VERSION ""

NS_ :

BS_:

BU_:

BO_ 2633719294 VFSSM3DET: 24 Vector__XXX
 SG_ VFSSMdl3Dttr1DttrTp : 0|4@1+ (1,0) [0|15] "" Vector__XXX
 SG_ VFSSMdl3Dttr1DttrDtSLOT : 4|4@1+ (1,0) [0|15] "" Vector__XXX
 SG_ VFSSMdl3Dttr2DttrTp : 24|4@1+ (1,0) [0|15] "" Vector__XXX
 SG_ VFSSMdl3Dttr2DttrDtSLOT : 28|4@1+ (1,0) [0|15] "" Vector__XXX
 SG_ VFSSMdl3Dttr3DttrTp : 48|4@1+ (1,0) [0|15] "" Vector__XXX
 SG_ VFSSMdl3Dttr3DttrDtSLOT : 52|4@1+ (1,0) [0|15] "" Vector__XXX
 SG_ VFSSMdl3Dttr4DttrTp : 72|4@1+ (1,0) [0|15] "" Vector__XXX
 SG_ VFSSMdl3Dttr4DttrDtSLOT : 76|4@1+ (1,0) [0|15] "" Vector__XXX
 SG_ VFSSMdl3Dttr5DttrTp : 96|4@1+ (1,0) [0|15] "" Vector__XXX
 SG_ VFSSMdl3Dttr5DttrDtSLOT : 100|4@1+ (1,0) [0|15] "" Vector__XXX
 SG_ VFSSMdl3Dttr6DttrTp : 120|4@1+ (1,0) [0|15] "" Vector__XXX
 SG_ VFSSMdl3Dttr6DttrDtSLOT : 124|4@1+ (1,0) [0|15] "" Vector__XXX
 SG_ VFSSMdl3Dttr7DttrTp : 144|4@1+ (1,0) [0|15] "" Vector__XXX
 SG_ VFSSMdl3Dttr7DttrDtSLOT : 148|4@1+ (1,0) [0|15] "" Vector__XXX
 SG_ VFSSMdl3Dttr8DttrTp : 168|4@1+ (1,0) [0|15] "" Vector__XXX
 SG_ VFSSMdl3Dttr8DttrDtSLOT : 172|4@1+ (1,0) [0|15] "" Vector__XXX

BO_ 2633719550 VFSSM4DET: 24 Vector__XXX
 SG_ VFSSMdl4Dttr1DttrTp : 0|4@1+ (1,0) [0|15] "" Vector__XXX
 SG_ VFSSMdl4Dttr1DttrDtSLOT : 4|4@1+ (1,0) [0|15] "" Vector__XXX
 SG_ VFSSMdl4Dttr2DttrTp : 24|4@1+ (1,0) [0|15] "" Vector__XXX
 SG_ VFSSMdl4Dttr2DttrDtSLOT : 28|4@1+ (1,0) [0|15] "" Vector__XXX
 SG_ VFSSMdl4Dttr3DttrTp : 48|4@1+ (1,0) [0|15] "" Vector__XXX
 SG_ VFSSMdl4Dttr3DttrDtSLOT : 52|4@1+ (1,0) [0|15] "" Vector__XXX
 SG_ VFSSMdl4Dttr4DttrTp : 72|4@1+ (1,0) [0|15] "" Vector__XXX
 SG_ VFSSMdl4Dttr4DttrDtSLOT : 76|4@1+ (1,0) [0|15] "" Vector__XXX
 SG_ VFSSMdl4Dttr5DttrTp : 96|4@1+ (1,0) [0|15] "" Vector__XXX
 SG_ VFSSMdl4Dttr5DttrDtSLOT : 100|4@1+ (1,0) [0|15] "" Vector__XXX
 SG_ VFSSMdl4Dttr6DttrTp : 120|4@1+ (1,0) [0|15] "" Vector__XXX
 SG_ VFSSMdl4Dttr6DttrDtSLOT : 124|4@1+ (1,0) [0|15] "" Vector__XXX
 SG_ VFSSMdl4Dttr7DttrTp : 144|4@1+ (1,0) [0|15] "" Vector__XXX
 SG_ VFSSMdl4Dttr7DttrDtSLOT : 148|4@1+ (1,0) [0|15] "" Vector__XXX
 SG_ VFSSMdl4Dttr8DttrTp : 168|4@1+ (1,0) [0|15] "" Vector__XXX
 SG_ VFSSMdl4Dttr8DttrDtSLOT : 172|4@1+ (1,0) [0|15] "" Vector__XXX

BO_ 2633719806 VFSSM1AUX: 16 Vector__XXX
 SG_ VFSSModule1HeatZone1Data : 0|16@1+ (0.01,0) [0|642.55] "V" Vector__XXX
 SG_ VFSSModule1HeatZone2Data : 16|16@1+ (0.01,0) [0|642.55] "V" Vector__XXX
 SG_ VFSSModule1ReleaseZone1Data : 32|16@1+ (0.01,0) [0|642.55] "V" Vector__XXX
 SG_ VFSSModule1ReleaseZone2Data : 48|16@1+ (0.01,0) [0|642.55] "V" Vector__XXX
 SG_ VFSSModule1PressureSwitch1Data : 64|16@1+ (0.01,0) [0|642.55] "V" Vector__XXX
 SG_ VFSSModule1PressureSwitch2Data : 80|16@1+ (0.01,0) [0|642.55] "V" Vector__XXX
 SG_ VFSSModule1PrimaryPowerVoltage : 96|16@1+ (0.01,0) [0|642.55] "V" Vector__XXX
 SG_ VFSSMdl1SndrPwrVltg : 112|16@1+ (0.01,0) [0|642.55] "V" Vector__XXX

BO_ 2633720062 VFSSM2AUX: 16 Vector__XXX
 SG_ VFSSModule2HeatZone1Data : 0|16@1+ (0.01,0) [0|642.55] "V" Vector__XXX
 SG_ VFSSModule2HeatZone2Data : 16|16@1+ (0.01,0) [0|642.55] "V" Vector__XXX
 SG_ VFSSModule2ReleaseZone1Data : 32|16@1+ (0.01,0) [0|642.55] "V" Vector__XXX
 SG_ VFSSModule2ReleaseZone2Data : 48|16@1+ (0.01,0) [0|642.55] "V" Vector__XXX
 SG_ VFSSModule2PressureSwitch1Data : 64|16@1+ (0.01,0) [0|642.55] "V" Vector__XXX
 SG_ VFSSModule2PressureSwitch2Data : 80|16@1+ (0.01,0) [0|642.55] "V" Vector__XXX
 SG_ VFSSModule2PrimaryPowerVoltage : 96|16@1+ (0.01,0) [0|642.55] "V" Vector__XXX
 SG_ VFSSMdl2SndrPwrVltg : 112|16@1+ (0.01,0) [0|642.55] "V" Vector__XXX

BO_ 2633720318 VFSSM3AUX: 16 Vector__XXX
 SG_ VFSSModule3HeatZone1Data : 0|16@1+ (0.01,0) [0|642.55] "V" Vector__XXX
 SG_ VFSSModule3HeatZone2Data : 16|16@1+ (0.01,0) [0|642.55] "V" Vector__XXX
 SG_ VFSSModule3ReleaseZone1Data : 32|16@1+ (0.01,0) [0|642.55] "V" Vector__XXX
 SG_ VFSSModule3ReleaseZone2Data : 48|16@1+ (0.01,0) [0|642.55] "V" Vector__XXX
 SG_ VFSSModule3PressureSwitch1Data : 64|16@1+ (0.01,0) [0|642.55] "V" Vector__XXX
 SG_ VFSSModule3PressureSwitch2Data : 80|16@1+ (0.01,0) [0|642.55] "V" Vector__XXX
 SG_ VFSSModule3PrimaryPowerVoltage : 96|16@1+ (0.01,0) [0|642.55] "V" Vector__XXX
 SG_ VFSSMdl3SndrPwrVltg : 112|16@1+ (0.01,0) [0|642.55] "V" Vector__XXX

BO_ 2633720574 VFSSM4AUX: 16 Vector__XXX
 SG_ VFSSModule4HeatZone1Data : 0|16@1+ (0.01,0) [0|642.55] "V" Vector__XXX
 SG_ VFSSModule4HeatZone2Data : 16|16@1+ (0.01,0) [0|642.55] "V" Vector__XXX
 SG_ VFSSModule4ReleaseZone1Data : 32|16@1+ (0.01,0) [0|642.55] "V" Vector__XXX
 SG_ VFSSModule4ReleaseZone2Data : 48|16@1+ (0.01,0) [0|642.55] "V" Vector__XXX
 SG_ VFSSModule4PressureSwitch1Data : 64|16@1+ (0.01,0) [0|642.55] "V" Vector__XXX
 SG_ VFSSModule4PressureSwitch2Data : 80|16@1+ (0.01,0) [0|642.55] "V" Vector__XXX
 SG_ VFSSModule4PrimaryPowerVoltage : 96|16@1+ (0.01,0) [0|642.55] "V" Vector__XXX
 SG_ VFSSMdl4SndrPwrVltg : 112|16@1+ (0.01,0) [0|642.55] "V" Vector__XXX

BO_ 2633720830 VFSSM1NAMES: 104 Vector__XXX
 SG_ VFSSModule1Name : 0|64@1+ (1,0) [0|255] "ASCII" Vector__XXX
 SG_ VFSSModule1DetectorZone1Name : 64|64@1+ (1,0) [0|255] "ASCII" Vector__XXX
 SG_ VFSSModule1DetectorZone2Name : 128|64@1+ (1,0) [0|255] "ASCII" Vector__XXX
 SG_ VFSSModule1DetectorZone3Name : 192|64@1+ (1,0) [0|255] "ASCII" Vector__XXX
 SG_ VFSSModule1DetectorZone4Name : 256|64@1+ (1,0) [0|255] "ASCII" Vector__XXX
 SG_ VFSSModule1DetectorZone5Name : 320|64@1+ (1,0) [0|255] "ASCII" Vector__XXX
 SG_ VFSSModule1DetectorZone6Name : 384|64@1+ (1,0) [0|255] "ASCII" Vector__XXX
 SG_ VFSSModule1DetectorZone7Name : 448|64@1+ (1,0) [0|255] "ASCII" Vector__XXX
 SG_ VFSSModule1DetectorZone8Name : 512|64@1+ (1,0) [0|255] "ASCII" Vector__XXX
 SG_ VFSSModule1HeatZone1Name : 576|64@1+ (1,0) [0|255] "ASCII" Vector__XXX
 SG_ VFSSModule1HeatZone2Name : 640|64@1+ (1,0) [0|255] "ASCII" Vector__XXX
 SG_ VFSSModule1ReleaseZone1Name : 704|64@1+ (1,0) [0|255] "ASCII" Vector__XXX
 SG_ VFSSModule1ReleaseZone2Name : 768|64@1+ (1,0) [0|255] "ASCII" Vector__XXX

BO_ 2633721086 VFSSM2NAMES: 104 Vector__XXX
 SG_ VFSSModule2Name : 0|64@1+ (1,0) [0|255] "ASCII" Vector__XXX
 SG_ VFSSModule2DetectorZone1Name : 64|64@1+ (1,0) [0|255] "ASCII" Vector__XXX
 SG_ VFSSModule2DetectorZone2Name : 128|64@1+ (1,0) [0|255] "ASCII" Vector__XXX
 SG_ VFSSModule2DetectorZone3Name : 192|64@1+ (1,0) [0|255] "ASCII" Vector__XXX
 SG_ VFSSModule2DetectorZone4Name : 256|64@1+ (1,0) [0|255] "ASCII" Vector__XXX
 SG_ VFSSModule2DetectorZone5Name : 320|64@1+ (1,0) [0|255] "ASCII" Vector__XXX
 SG_ VFSSModule2DetectorZone6Name : 384|64@1+ (1,0) [0|255] "ASCII" Vector__XXX
 SG_ VFSSModule2DetectorZone7Name : 448|64@1+ (1,0) [0|255] "ASCII" Vector__XXX
 SG_ VFSSModule2DetectorZone8Name : 512|64@1+ (1,0) [0|255] "ASCII" Vector__XXX
 SG_ VFSSModule2HeatZone1Name : 576|64@1+ (1,0) [0|255] "ASCII" Vector__XXX
 SG_ VFSSModule2HeatZone2Name : 640|64@1+ (1,0) [0|255] "ASCII" Vector__XXX
 SG_ VFSSModule2ReleaseZone1Name : 704|64@1+ (1,0) [0|255] "ASCII" Vector__XXX
 SG_ VFSSModule2ReleaseZone2Name : 768|64@1+ (1,0) [0|255] "ASCII" Vector__XXX

BO_ 2633721342 VFSSM3NAMES: 104 Vector__XXX
 SG_ VFSSModule3Name : 0|64@1+ (1,0) [0|255] "ASCII" Vector__XXX
 SG_ VFSSModule3DetectorZone1Name : 64|64@1+ (1,0) [0|255] "ASCII" Vector__XXX
 SG_ VFSSModule3DetectorZone2Name : 128|64@1+ (1,0) [0|255] "ASCII" Vector__XXX
 SG_ VFSSModule3DetectorZone3Name : 192|64@1+ (1,0) [0|255] "ASCII" Vector__XXX
 SG_ VFSSModule3DetectorZone4Name : 256|64@1+ (1,0) [0|255] "ASCII" Vector__XXX
 SG_ VFSSModule3DetectorZone5Name : 320|64@1+ (1,0) [0|255] "ASCII" Vector__XXX
 SG_ VFSSModule3DetectorZone6Name : 384|64@1+ (1,0) [0|255] "ASCII" Vector__XXX
 SG_ VFSSModule3DetectorZone7Name : 448|64@1+ (1,0) [0|255] "ASCII" Vector__XXX
 SG_ VFSSModule3DetectorZone8Name : 512|64@1+ (1,0) [0|255] "ASCII" Vector__XXX
 SG_ VFSSModule3HeatZone1Name : 576|64@1+ (1,0) [0|255] "ASCII" Vector__XXX
 SG_ VFSSModule3HeatZone2Name : 640|64@1+ (1,0) [0|255] "ASCII" Vector__XXX
 SG_ VFSSModule3ReleaseZone1Name : 704|64@1+ (1,0) [0|255] "ASCII" Vector__XXX
 SG_ VFSSModule3ReleaseZone2Name : 768|64@1+ (1,0) [0|255] "ASCII" Vector__XXX

BO_ 2633721598 VFSSM4NAMES: 104 Vector__XXX
 SG_ VFSSModule4Name : 0|64@1+ (1,0) [0|255] "ASCII" Vector__XXX
 SG_ VFSSModule4DetectorZone1Name : 64|64@1+ (1,0) [0|255] "ASCII" Vector__XXX
 SG_ VFSSModule4DetectorZone2Name : 128|64@1+ (1,0) [0|255] "ASCII" Vector__XXX
 SG_ VFSSModule4DetectorZone3Name : 192|64@1+ (1,0) [0|255] "ASCII" Vector__XXX
 SG_ VFSSModule4DetectorZone4Name : 256|64@1+ (1,0) [0|255] "ASCII" Vector__XXX
 SG_ VFSSModule4DetectorZone5Name : 320|64@1+ (1,0) [0|255] "ASCII" Vector__XXX
 SG_ VFSSModule4DetectorZone6Name : 384|64@1+ (1,0) [0|255] "ASCII" Vector__XXX
 SG_ VFSSModule4DetectorZone7Name : 448|64@1+ (1,0) [0|255] "ASCII" Vector__XXX
 SG_ VFSSModule4DetectorZone8Name : 512|64@1+ (1,0) [0|255] "ASCII" Vector__XXX
 SG_ VFSSModule4HeatZone1Name : 576|64@1+ (1,0) [0|255] "ASCII" Vector__XXX
 SG_ VFSSModule4HeatZone2Name : 640|64@1+ (1,0) [0|255] "ASCII" Vector__XXX
 SG_ VFSSModule4ReleaseZone1Name : 704|64@1+ (1,0) [0|255] "ASCII" Vector__XXX
 SG_ VFSSModule4ReleaseZone2Name : 768|64@1+ (1,0) [0|255] "ASCII" Vector__XXX

BO_ 2566612990 MG2IAPL: 8 Vector__XXX
 SG_ MtGt2IvtPwLtddtUddRs : 0|2@1+ (1,0) [0|3] "" Vector__XXX
 SG_ MtGt2IvtPwLtddtDCSdCtMx : 2|2@1+ (1,0) [0|3] "" Vector__XXX
 SG_ MtGt2IvtPwLtddtDCSdCtM : 4|2@1+ (1,0) [0|3] "" Vector__XXX
 SG_ MtGt2IvtPwLtddtDCSdVtMx : 6|2@1+ (1,0) [0|3] "" Vector__XXX
 SG_ MtGt2IvtPwLtddtDCSdVtM : 8|2@1+ (1,0) [0|3] "" Vector__XXX
 SG_ MtGt2IvtPwLtddtMPwMx : 10|2@1+ (1,0) [0|3] "" Vector__XXX
 SG_ MtGt2IvtPwLtddtMPwM : 12|2@1+ (1,0) [0|3] "" Vector__XXX
 SG_ MtGt2IvtPwLtddtDCSdPwMx : 14|2@1+ (1,0) [0|3] "" Vector__XXX
 SG_ MtGt2IvtPwLtddtDCSdPwM : 16|2@1+ (1,0) [0|3] "" Vector__XXX
 SG_ MtrGnrtr2InvrtrPwrLmtddtTrqMxmm : 18|2@1+ (1,0) [0|3] "" Vector__XXX
 SG_ MtrGnrtr2InvrtrPwrLmtddtTrqMnmm : 20|2@1+ (1,0) [0|3] "" Vector__XXX
 SG_ MtrGnrtr2InvrtrPwrLmtddtSpdMxmm : 22|2@1+ (1,0) [0|3] "" Vector__XXX
 SG_ MtrGnrtr2InvrtrPwrLmtddtSpdMnmm : 24|2@1+ (1,0) [0|3] "" Vector__XXX
 SG_ MtGt2IvtPwLtddtIvtTpt : 28|2@1+ (1,0) [0|3] "" Vector__XXX
 SG_ MtGt2IvtPwLtddtMtTpt : 30|2@1+ (1,0) [0|3] "" Vector__XXX
 SG_ MtGt2IvtPwLtdDtFtCdt : 32|2@1+ (1,0) [0|3] "" Vector__XXX
 SG_ MtGt2IvtPwLtdDtAtvTqRtLt : 34|2@1+ (1,0) [0|3] "" Vector__XXX
 SG_ MtGt2IvtPwLtdDtAtvSpdRtLt : 36|2@1+ (1,0) [0|3] "" Vector__XXX
 SG_ MtGt2IvtTqLtdDtMCtsts : 38|2@1+ (1,0) [0|3] "" Vector__XXX

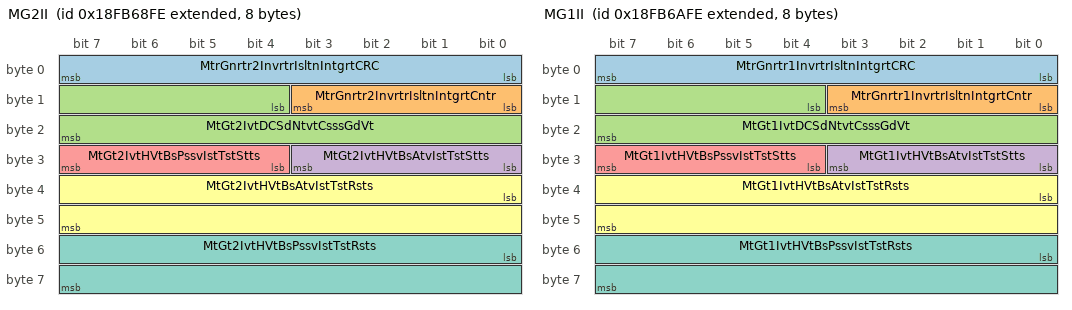
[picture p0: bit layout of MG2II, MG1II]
BO_ 2566613246 MG2II: 8 Vector__XXX
 SG_ MtrGnrtr2InvrtrIsltnIntgrtCRC : 0|8@1+ (1,0) [0|255] "count" Vector__XXX
 SG_ MtrGnrtr2InvrtrIsltnIntgrtCntr : 8|4@1+ (1,0) [0|15] "" Vector__XXX
 SG_ MtGt2IvtDCSdNtvtCsssGdVt : 12|12@1+ (42370,-125) [-125|125.9375] "%" Vector__XXX
 SG_ MtGt2IvtHVtBsAtvIstTstStts : 24|4@1+ (1,0) [0|15] "" Vector__XXX
 SG_ MtGt2IvtHVtBsPssvIstTstStts : 28|4@1+ (1,0) [0|15] "" Vector__XXX
 SG_ MtGt2IvtHVtBsAtvIstTstRsts : 32|16@1+ (0.1,0) [0|6425.5] "ohm/V" Vector__XXX
 SG_ MtGt2IvtHVtBsPssvIstTstRsts : 48|16@1+ (0.1,0) [0|6425.5] "ohm/V" Vector__XXX

BO_ 2566613502 MG1IAPL: 8 Vector__XXX
 SG_ MtGt1IvtPwLtddtUddRs : 0|2@1+ (1,0) [0|3] "" Vector__XXX
 SG_ MtGt1IvtPwLtddtDCSdCtMx : 2|2@1+ (1,0) [0|3] "" Vector__XXX
 SG_ MtGt1IvtPwLtddtDCSdCtM : 4|2@1+ (1,0) [0|3] "" Vector__XXX
 SG_ MtGt1IvtPwLtddtDCSdVtMx : 6|2@1+ (1,0) [0|3] "" Vector__XXX
 SG_ MtGt1IvtPwLtddtDCSdVtM : 8|2@1+ (1,0) [0|3] "" Vector__XXX
 SG_ MtGt1IvtPwLtddtMPwMx : 10|2@1+ (1,0) [0|3] "" Vector__XXX
 SG_ MtGt1IvtPwLtddtMPwM : 12|2@1+ (1,0) [0|3] "" Vector__XXX
 SG_ MtGt1IvtPwLtddtDCSdPwMx : 14|2@1+ (1,0) [0|3] "" Vector__XXX
 SG_ MtGt1IvtPwLtddtDCSdPwM : 16|2@1+ (1,0) [0|3] "" Vector__XXX
 SG_ MtrGnrtr1InvrtrPwrLmtddtTrqMxmm : 18|2@1+ (1,0) [0|3] "" Vector__XXX
 SG_ MtrGnrtr1InvrtrPwrLmtddtTrqMnmm : 20|2@1+ (1,0) [0|3] "" Vector__XXX
 SG_ MtrGnrtr1InvrtrPwrLmtddtSpdMxmm : 22|2@1+ (1,0) [0|3] "" Vector__XXX
 SG_ MtrGnrtr1InvrtrPwrLmtddtSpdMnmm : 24|2@1+ (1,0) [0|3] "" Vector__XXX
 SG_ MtGt1IvtPwLtddtIvtTpt : 28|2@1+ (1,0) [0|3] "" Vector__XXX
 SG_ MtGt1IvtPwLtddtMtTpt : 30|2@1+ (1,0) [0|3] "" Vector__XXX
 SG_ MtGt1IvtPwLtdDtFtCdt : 32|2@1+ (1,0) [0|3] "" Vector__XXX
 SG_ MtGt1IvtPwLtdDtAtvTqRtLt : 34|2@1+ (1,0) [0|3] "" Vector__XXX
 SG_ MtGt1IvtPwLtdDtAtvSpdRtLt : 36|2@1+ (1,0) [0|3] "" Vector__XXX
 SG_ MtGt1IvtTqLtdDtMCtsts : 38|2@1+ (1,0) [0|3] "" Vector__XXX

BO_ 2566613758 MG1II: 8 Vector__XXX
 SG_ MtrGnrtr1InvrtrIsltnIntgrtCRC : 0|8@1+ (1,0) [0|255] "count" Vector__XXX
 SG_ MtrGnrtr1InvrtrIsltnIntgrtCntr : 8|4@1+ (1,0) [0|15] "" Vector__XXX
 SG_ MtGt1IvtDCSdNtvtCsssGdVt : 12|12@1+ (42370,-125) [-125|125.9375] "%" Vector__XXX
 SG_ MtGt1IvtHVtBsAtvIstTstStts : 24|4@1+ (1,0) [0|15] "" Vector__XXX
 SG_ MtGt1IvtHVtBsPssvIstTstStts : 28|4@1+ (1,0) [0|15] "" Vector__XXX
 SG_ MtGt1IvtHVtBsAtvIstTstRsts : 32|16@1+ (0.1,0) [0|6425.5] "ohm/V" Vector__XXX
 SG_ MtGt1IvtHVtBsPssvIstTstRsts : 48|16@1+ (0.1,0) [0|6425.5] "ohm/V" Vector__XXX

BO_ 2566614014 HVBI: 8 Vector__XXX
 SG_ HighVoltageDCBusAvailability : 0|4@1+ (1,0) [0|15] "" Vector__XXX

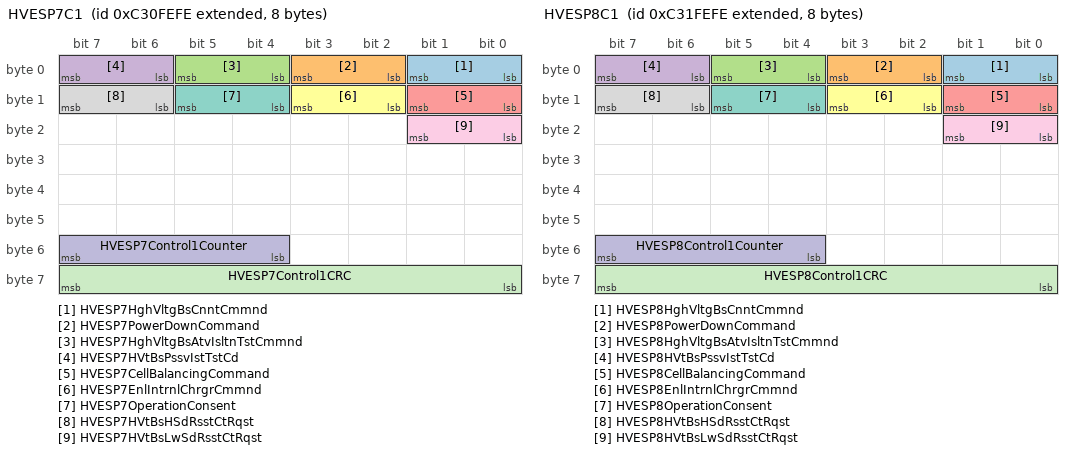
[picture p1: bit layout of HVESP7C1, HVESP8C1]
BO_ 2352021246 HVESP7C1: 8 Vector__XXX
 SG_ HVESP7HghVltgBsCnntCmmnd : 0|2@1+ (1,0) [0|3] "" Vector__XXX
 SG_ HVESP7PowerDownCommand : 2|2@1+ (1,0) [0|3] "" Vector__XXX
 SG_ HVESP7HghVltgBsAtvIsltnTstCmmnd : 4|2@1+ (1,0) [0|3] "" Vector__XXX
 SG_ HVESP7HVtBsPssvIstTstCd : 6|2@1+ (1,0) [0|3] "" Vector__XXX
 SG_ HVESP7CellBalancingCommand : 8|2@1+ (1,0) [0|3] "" Vector__XXX
 SG_ HVESP7EnlIntrnlChrgrCmmnd : 10|2@1+ (1,0) [0|3] "" Vector__XXX
 SG_ HVESP7OperationConsent : 12|2@1+ (1,0) [0|3] "" Vector__XXX
 SG_ HVESP7HVtBsHSdRsstCtRqst : 14|2@1+ (1,0) [0|3] "" Vector__XXX
 SG_ HVESP7HVtBsLwSdRsstCtRqst : 16|2@1+ (1,0) [0|3] "" Vector__XXX
 SG_ HVESP7Control1Counter : 52|4@1+ (1,0) [0|15] "" Vector__XXX
 SG_ HVESP7Control1CRC : 56|8@1+ (1,0) [0|255] "count" Vector__XXX

BO_ 2352086782 HVESP8C1: 8 Vector__XXX
 SG_ HVESP8HghVltgBsCnntCmmnd : 0|2@1+ (1,0) [0|3] "" Vector__XXX
 SG_ HVESP8PowerDownCommand : 2|2@1+ (1,0) [0|3] "" Vector__XXX
 SG_ HVESP8HghVltgBsAtvIsltnTstCmmnd : 4|2@1+ (1,0) [0|3] "" Vector__XXX
 SG_ HVESP8HVtBsPssvIstTstCd : 6|2@1+ (1,0) [0|3] "" Vector__XXX
 SG_ HVESP8CellBalancingCommand : 8|2@1+ (1,0) [0|3] "" Vector__XXX
 SG_ HVESP8EnlIntrnlChrgrCmmnd : 10|2@1+ (1,0) [0|3] "" Vector__XXX
 SG_ HVESP8OperationConsent : 12|2@1+ (1,0) [0|3] "" Vector__XXX
 SG_ HVESP8HVtBsHSdRsstCtRqst : 14|2@1+ (1,0) [0|3] "" Vector__XXX
 SG_ HVESP8HVtBsLwSdRsstCtRqst : 16|2@1+ (1,0) [0|3] "" Vector__XXX
 SG_ HVESP8Control1Counter : 52|4@1+ (1,0) [0|15] "" Vector__XXX
 SG_ HVESP8Control1CRC : 56|8@1+ (1,0) [0|255] "count" Vector__XXX

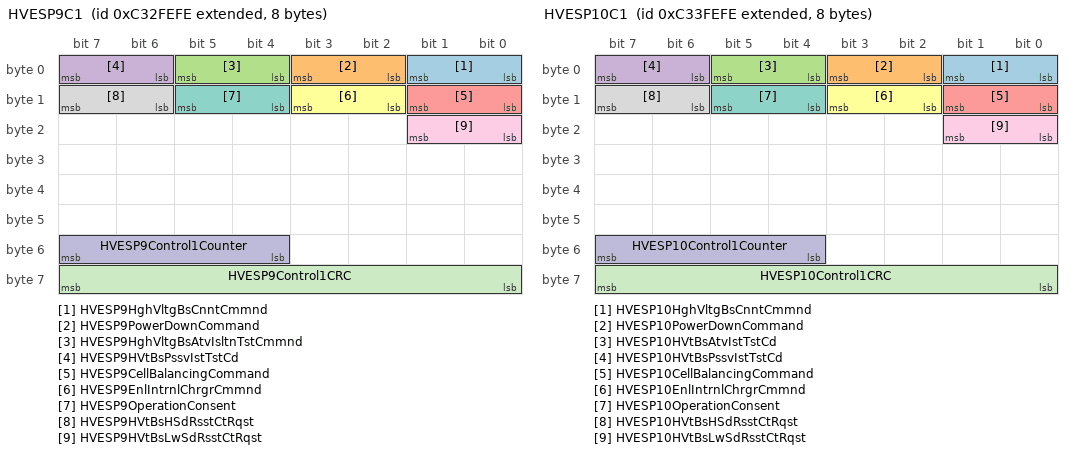
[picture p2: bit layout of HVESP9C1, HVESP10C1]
BO_ 2352152318 HVESP9C1: 8 Vector__XXX
 SG_ HVESP9HghVltgBsCnntCmmnd : 0|2@1+ (1,0) [0|3] "" Vector__XXX
 SG_ HVESP9PowerDownCommand : 2|2@1+ (1,0) [0|3] "" Vector__XXX
 SG_ HVESP9HghVltgBsAtvIsltnTstCmmnd : 4|2@1+ (1,0) [0|3] "" Vector__XXX
 SG_ HVESP9HVtBsPssvIstTstCd : 6|2@1+ (1,0) [0|3] "" Vector__XXX
 SG_ HVESP9CellBalancingCommand : 8|2@1+ (1,0) [0|3] "" Vector__XXX
 SG_ HVESP9EnlIntrnlChrgrCmmnd : 10|2@1+ (1,0) [0|3] "" Vector__XXX
 SG_ HVESP9OperationConsent : 12|2@1+ (1,0) [0|3] "" Vector__XXX
 SG_ HVESP9HVtBsHSdRsstCtRqst : 14|2@1+ (1,0) [0|3] "" Vector__XXX
 SG_ HVESP9HVtBsLwSdRsstCtRqst : 16|2@1+ (1,0) [0|3] "" Vector__XXX
 SG_ HVESP9Control1Counter : 52|4@1+ (1,0) [0|15] "" Vector__XXX
 SG_ HVESP9Control1CRC : 56|8@1+ (1,0) [0|255] "count" Vector__XXX

BO_ 2352217854 HVESP10C1: 8 Vector__XXX
 SG_ HVESP10HghVltgBsCnntCmmnd : 0|2@1+ (1,0) [0|3] "" Vector__XXX
 SG_ HVESP10PowerDownCommand : 2|2@1+ (1,0) [0|3] "" Vector__XXX
 SG_ HVESP10HVtBsAtvIstTstCd : 4|2@1+ (1,0) [0|3] "" Vector__XXX
 SG_ HVESP10HVtBsPssvIstTstCd : 6|2@1+ (1,0) [0|3] "" Vector__XXX
 SG_ HVESP10CellBalancingCommand : 8|2@1+ (1,0) [0|3] "" Vector__XXX
 SG_ HVESP10EnlIntrnlChrgrCmmnd : 10|2@1+ (1,0) [0|3] "" Vector__XXX
 SG_ HVESP10OperationConsent : 12|2@1+ (1,0) [0|3] "" Vector__XXX
 SG_ HVESP10HVtBsHSdRsstCtRqst : 14|2@1+ (1,0) [0|3] "" Vector__XXX
 SG_ HVESP10HVtBsLwSdRsstCtRqst : 16|2@1+ (1,0) [0|3] "" Vector__XXX
 SG_ HVESP10Control1Counter : 52|4@1+ (1,0) [0|15] "" Vector__XXX
 SG_ HVESP10Control1CRC : 56|8@1+ (1,0) [0|255] "count" Vector__XXX

BO_ 2555379454 DTS: 29 Vector__XXX
 SG_ DataTransferManufacturerID : 0|11@1+ (1,0) [0|2047] "" Vector__XXX
 SG_ TotalWeeklyMessageInstances : 88|16@1+ (1,0) [0|65535] "count" Vector__XXX
 SG_ LongestWeeklyMessageInstance : 104|24@1+ (1,0) [0|16777215] "count" Vector__XXX
 SG_ TotalMonthlyMessageInstances : 160|16@1+ (1,0) [0|65535] "count" Vector__XXX
 SG_ LongestMonthlyMessageInstance : 176|24@1+ (1,0) [0|16777215] "count" Vector__XXX
 SG_ TotalDailyMessageInstances : 16|16@1+ (1,0) [0|65535] "count" Vector__XXX
 SG_ LongestDailyMessageInstance : 32|24@1+ (1,0) [0|16777215] "count" Vector__XXX
 SG_ TotalDailyMessageBytes : 56|32@1+ (1,0) [0|4294967295] "count" Vector__XXX
 SG_ TotalWeeklyMessageBytes : 128|32@1+ (1,0) [0|4294967295] "count" Vector__XXX
 SG_ TotalMonthlyMessageBytes : 200|32@1+ (1,0) [0|4294967295] "count" Vector__XXX

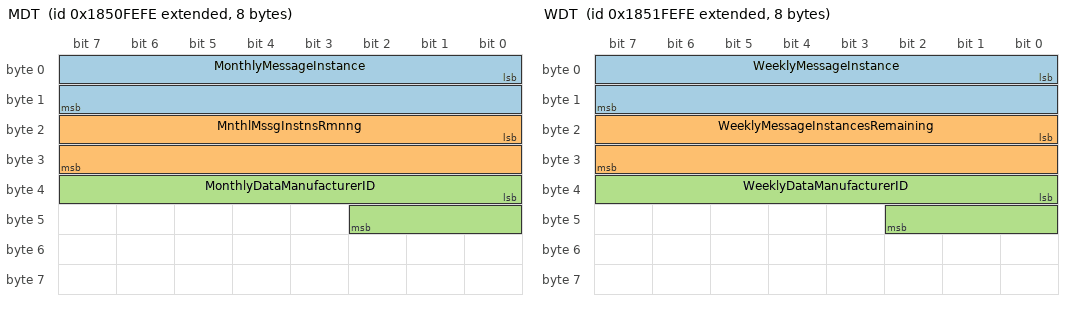
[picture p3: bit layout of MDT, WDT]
BO_ 2555444990 MDT: 8 Vector__XXX
 SG_ MonthlyMessageInstance : 0|16@1+ (1,0) [0|65535] "count" Vector__XXX
 SG_ MnthlMssgInstnsRmnng : 16|16@1+ (1,0) [0|65535] "count" Vector__XXX
 SG_ MonthlyDataManufacturerID : 32|11@1+ (1,0) [0|2047] "" Vector__XXX

BO_ 2555510526 WDT: 8 Vector__XXX
 SG_ WeeklyMessageInstance : 0|16@1+ (1,0) [0|65535] "count" Vector__XXX
 SG_ WeeklyMessageInstancesRemaining : 16|16@1+ (1,0) [0|65535] "count" Vector__XXX
 SG_ WeeklyDataManufacturerID : 32|11@1+ (1,0) [0|2047] "" Vector__XXX

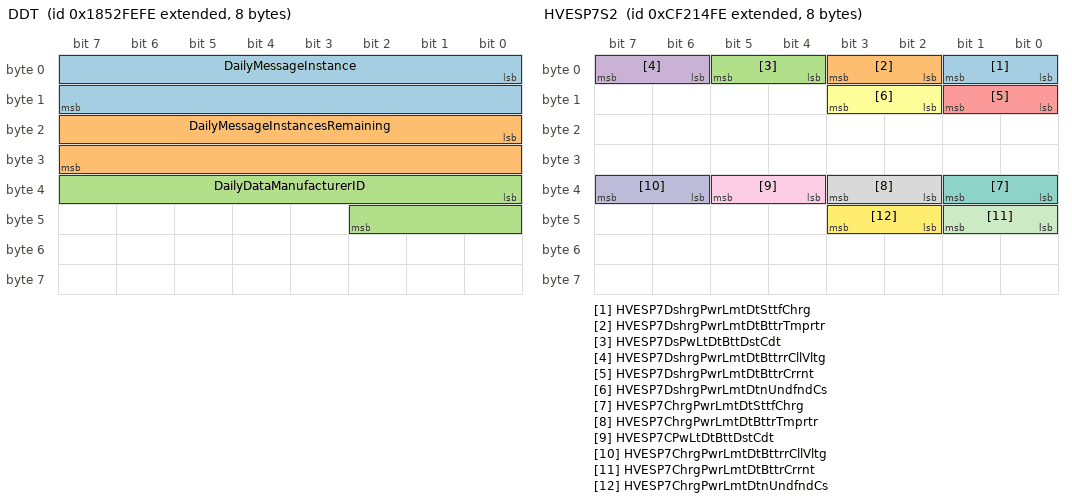
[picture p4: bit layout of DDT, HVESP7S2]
BO_ 2555576062 DDT: 8 Vector__XXX
 SG_ DailyMessageInstance : 0|16@1+ (1,0) [0|65535] "count" Vector__XXX
 SG_ DailyMessageInstancesRemaining : 16|16@1+ (1,0) [0|65535] "count" Vector__XXX
 SG_ DailyDataManufacturerID : 32|11@1+ (1,0) [0|2047] "" Vector__XXX

BO_ 2364675326 HVESP7S2: 8 Vector__XXX
 SG_ HVESP7DshrgPwrLmtDtSttfChrg : 0|2@1+ (1,0) [0|3] "" Vector__XXX
 SG_ HVESP7DshrgPwrLmtDtBttrTmprtr : 2|2@1+ (1,0) [0|3] "" Vector__XXX
 SG_ HVESP7DsPwLtDtBttDstCdt : 4|2@1+ (1,0) [0|3] "" Vector__XXX
 SG_ HVESP7DshrgPwrLmtDtBttrrCllVltg : 6|2@1+ (1,0) [0|3] "" Vector__XXX
 SG_ HVESP7DshrgPwrLmtDtBttrCrrnt : 8|2@1+ (1,0) [0|3] "" Vector__XXX
 SG_ HVESP7DshrgPwrLmtDtnUndfndCs : 10|2@1+ (1,0) [0|3] "" Vector__XXX
 SG_ HVESP7ChrgPwrLmtDtSttfChrg : 32|2@1+ (1,0) [0|3] "" Vector__XXX
 SG_ HVESP7ChrgPwrLmtDtBttrTmprtr : 34|2@1+ (1,0) [0|3] "" Vector__XXX
 SG_ HVESP7CPwLtDtBttDstCdt : 36|2@1+ (1,0) [0|3] "" Vector__XXX
 SG_ HVESP7ChrgPwrLmtDtBttrrCllVltg : 38|2@1+ (1,0) [0|3] "" Vector__XXX
 SG_ HVESP7ChrgPwrLmtDtBttrCrrnt : 40|2@1+ (1,0) [0|3] "" Vector__XXX
 SG_ HVESP7ChrgPwrLmtDtnUndfndCs : 42|2@1+ (1,0) [0|3] "" Vector__XXX

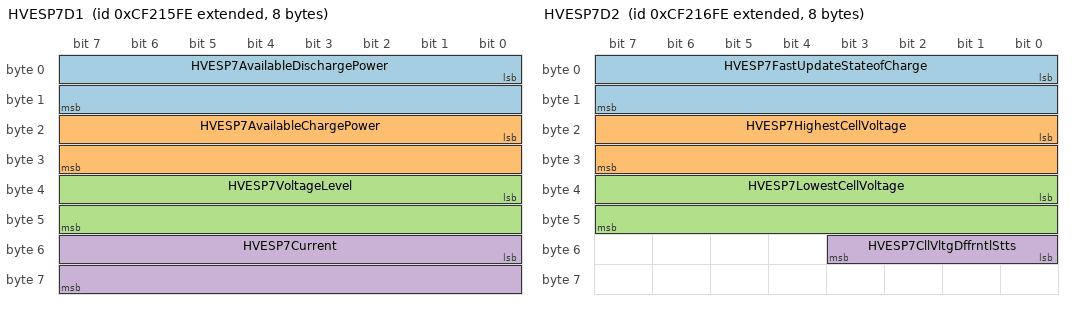
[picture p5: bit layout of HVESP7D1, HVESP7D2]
BO_ 2364675582 HVESP7D1: 8 Vector__XXX
 SG_ HVESP7AvailableDischargePower : 0|16@1+ (0.05,0) [0|3212.75] "kW" Vector__XXX
 SG_ HVESP7AvailableChargePower : 16|16@1+ (0.05,0) [0|3212.75] "kW" Vector__XXX
 SG_ HVESP7VoltageLevel : 32|16@1+ (0.05,0) [0|3212.75] "V" Vector__XXX
 SG_ HVESP7Current : 48|16@1+ (0.05,-1600) [-1600|1612.75] "A" Vector__XXX

BO_ 2364675838 HVESP7D2: 8 Vector__XXX
 SG_ HVESP7FastUpdateStateofCharge : 0|16@1+ (0.0015625,0) [0|100.3984375] "%" Vector__XXX
 SG_ HVESP7HighestCellVoltage : 16|16@1+ (0.001,0) [0|64.255] "V" Vector__XXX
 SG_ HVESP7LowestCellVoltage : 32|16@1+ (0.001,0) [0|64.255] "V" Vector__XXX
 SG_ HVESP7CllVltgDffrntlStts : 48|4@1+ (1,0) [0|15] "" Vector__XXX

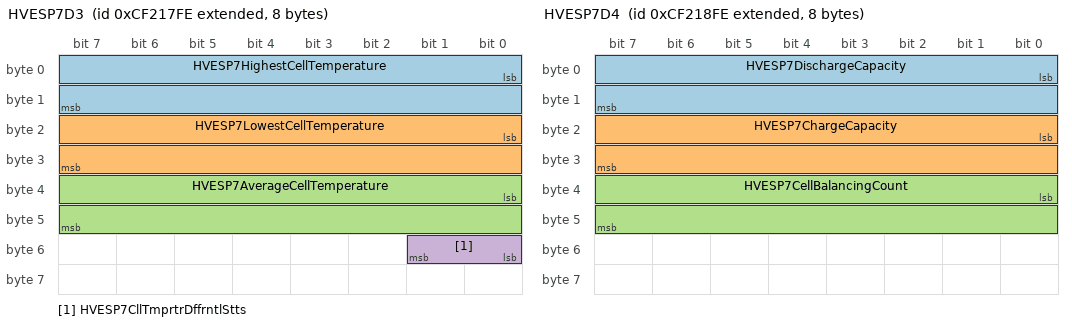
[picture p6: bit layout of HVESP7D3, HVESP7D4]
BO_ 2364676094 HVESP7D3: 8 Vector__XXX
 SG_ HVESP7HighestCellTemperature : 0|16@1+ (0.03125,-273) [-273|1734.96875] "degC" Vector__XXX
 SG_ HVESP7LowestCellTemperature : 16|16@1+ (0.03125,-273) [-273|1734.96875] "degC" Vector__XXX
 SG_ HVESP7AverageCellTemperature : 32|16@1+ (0.03125,-273) [-273|1734.96875] "degC" Vector__XXX
 SG_ HVESP7CllTmprtrDffrntlStts : 48|2@1+ (1,0) [0|3] "" Vector__XXX

BO_ 2364676350 HVESP7D4: 8 Vector__XXX
 SG_ HVESP7DischargeCapacity : 0|16@1+ (0.01,0) [0|642.55] "Ah" Vector__XXX
 SG_ HVESP7ChargeCapacity : 16|16@1+ (0.01,0) [0|642.55] "Ah" Vector__XXX
 SG_ HVESP7CellBalancingCount : 32|16@1+ (1,0) [0|64255] "count" Vector__XXX

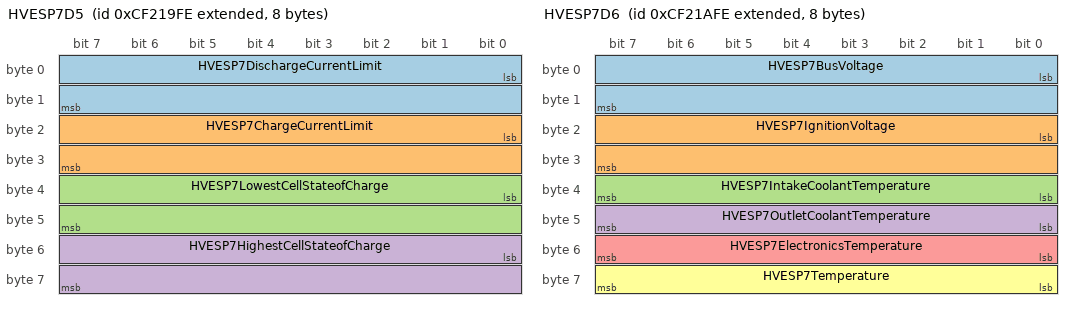
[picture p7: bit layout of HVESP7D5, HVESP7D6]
BO_ 2364676606 HVESP7D5: 8 Vector__XXX
 SG_ HVESP7DischargeCurrentLimit : 0|16@1+ (0.05,-1600) [-1600|1612.75] "A" Vector__XXX
 SG_ HVESP7ChargeCurrentLimit : 16|16@1+ (0.05,-1600) [-1600|1612.75] "A" Vector__XXX
 SG_ HVESP7LowestCellStateofCharge : 32|16@1+ (0.0015625,0) [0|100.3984375] "%" Vector__XXX
 SG_ HVESP7HighestCellStateofCharge : 48|16@1+ (0.0015625,0) [0|100.3984375] "%" Vector__XXX

BO_ 2364676862 HVESP7D6: 8 Vector__XXX
 SG_ HVESP7BusVoltage : 0|16@1+ (0.05,0) [0|3212.75] "V" Vector__XXX
 SG_ HVESP7IgnitionVoltage : 16|16@1+ (0.01,0) [0|642.55] "V" Vector__XXX
 SG_ HVESP7IntakeCoolantTemperature : 32|8@1+ (1,-40) [-40|210] "degC" Vector__XXX
 SG_ HVESP7OutletCoolantTemperature : 40|8@1+ (1,-40) [-40|210] "degC" Vector__XXX
 SG_ HVESP7ElectronicsTemperature : 48|8@1+ (1,-40) [-40|210] "degC" Vector__XXX
 SG_ HVESP7Temperature : 56|8@1+ (1,-40) [-40|210] "degC" Vector__XXX

BO_ 2364677118 HVESP7S1: 8 Vector__XXX
 SG_ HVESP7HghVltgBsPstvCnttrStt : 0|2@1+ (1,0) [0|3] "" Vector__XXX
 SG_ HVESP7HghVltgBsNgtvCnttrStt : 2|2@1+ (1,0) [0|3] "" Vector__XXX
 SG_ HVESP7HghVltgBsDsnntFrwrnng : 4|4@1+ (1,0) [0|15] "" Vector__XXX
 SG_ HVESP7HghVltgBsPrChrgRlStt : 8|2@1+ (1,0) [0|3] "" Vector__XXX
 SG_ HVESP7CntrfPkCnttrStt : 10|2@1+ (1,0) [0|3] "" Vector__XXX
 SG_ HVESP7HghVltgBsAtvIsltnTstStts : 12|4@1+ (1,0) [0|15] "" Vector__XXX
 SG_ HVESP7HghVltgBsPssvIsltnTstStts : 16|4@1+ (1,0) [0|15] "" Vector__XXX
 SG_ HVESP7HVILStatus : 20|2@1+ (1,0) [0|3] "" Vector__XXX
 SG_ HVESP7InertiaSwitchStatus : 22|2@1+ (1,0) [0|3] "" Vector__XXX
 SG_ HVESP7StateofChargeStatus : 24|4@1+ (1,0) [0|15] "" Vector__XXX
 SG_ HVESP7CellBalanceStatus : 28|2@1+ (1,0) [0|3] "" Vector__XXX
 SG_ HVESP7CellBalancingActive : 30|2@1+ (1,0) [0|3] "" Vector__XXX
 SG_ HVESP7InternalChargerStatus : 32|2@1+ (1,0) [0|3] "" Vector__XXX
 SG_ HVESP7HghVltgBsCnntnStts : 40|4@1+ (1,0) [0|15] "" Vector__XXX
 SG_ HVESP7OperationalStatus : 44|4@1+ (1,0) [0|15] "" Vector__XXX
 SG_ HVESP7Status1Counter : 52|4@1+ (1,0) [0|15] "" Vector__XXX
 SG_ HVESP7Status1CRC : 56|8@1+ (1,0) [0|255] "count" Vector__XXX

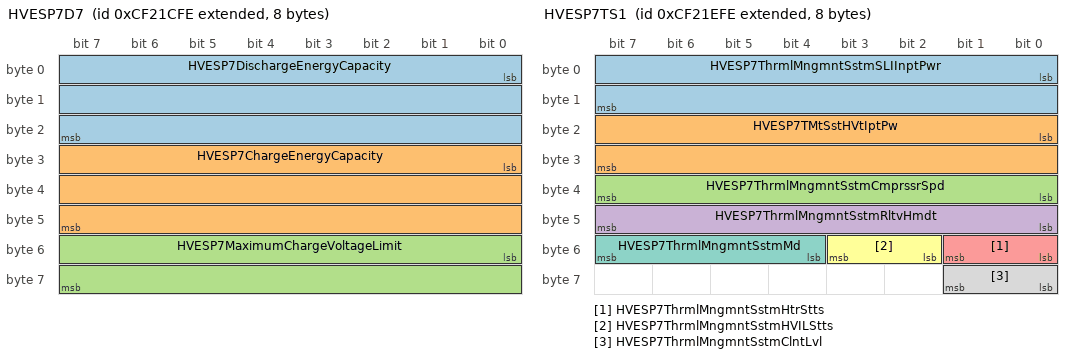
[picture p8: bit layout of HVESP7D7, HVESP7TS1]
BO_ 2364677374 HVESP7D7: 8 Vector__XXX
 SG_ HVESP7DischargeEnergyCapacity : 0|24@1+ (0.001,0) [0|16449.535] "kWh" Vector__XXX
 SG_ HVESP7ChargeEnergyCapacity : 24|24@1+ (0.001,0) [0|16449.535] "kWh" Vector__XXX
 SG_ HVESP7MaximumChargeVoltageLimit : 48|16@1+ (0.05,0) [0|3212.75] "V" Vector__XXX

BO_ 2364677630 HVESP7MS1: 8 Vector__XXX
 SG_ HVESP7Module1OperationalStatus : 0|2@1+ (1,0) [0|3] "" Vector__XXX
 SG_ HVESP7Module2OperationalStatus : 2|2@1+ (1,0) [0|3] "" Vector__XXX
 SG_ HVESP7Module3OperationalStatus : 4|2@1+ (1,0) [0|3] "" Vector__XXX
 SG_ HVESP7Module4OperationalStatus : 6|2@1+ (1,0) [0|3] "" Vector__XXX
 SG_ HVESP7Module5OperationalStatus : 8|2@1+ (1,0) [0|3] "" Vector__XXX
 SG_ HVESP7Module6OperationalStatus : 10|2@1+ (1,0) [0|3] "" Vector__XXX
 SG_ HVESP7Module7OperationalStatus : 12|2@1+ (1,0) [0|3] "" Vector__XXX
 SG_ HVESP7Module8OperationalStatus : 14|2@1+ (1,0) [0|3] "" Vector__XXX
 SG_ HVESP7Module9OperationalStatus : 16|2@1+ (1,0) [0|3] "" Vector__XXX
 SG_ HVESP7Module10OperationalStatus : 18|2@1+ (1,0) [0|3] "" Vector__XXX
 SG_ HVESP7Module11OperationalStatus : 20|2@1+ (1,0) [0|3] "" Vector__XXX
 SG_ HVESP7Module12OperationalStatus : 22|2@1+ (1,0) [0|3] "" Vector__XXX
 SG_ HVESP7Module13OperationalStatus : 24|2@1+ (1,0) [0|3] "" Vector__XXX
 SG_ HVESP7Module14OperationalStatus : 26|2@1+ (1,0) [0|3] "" Vector__XXX
 SG_ HVESP7Module15OperationalStatus : 28|2@1+ (1,0) [0|3] "" Vector__XXX
 SG_ HVESP7Module16OperationalStatus : 30|2@1+ (1,0) [0|3] "" Vector__XXX
 SG_ HVESP7Module17OperationalStatus : 32|2@1+ (1,0) [0|3] "" Vector__XXX
 SG_ HVESP7Module18OperationalStatus : 34|2@1+ (1,0) [0|3] "" Vector__XXX
 SG_ HVESP7Module19OperationalStatus : 36|2@1+ (1,0) [0|3] "" Vector__XXX
 SG_ HVESP7Module20OperationalStatus : 38|2@1+ (1,0) [0|3] "" Vector__XXX
 SG_ HVESP7Module21OperationalStatus : 40|2@1+ (1,0) [0|3] "" Vector__XXX
 SG_ HVESP7Module22OperationalStatus : 42|2@1+ (1,0) [0|3] "" Vector__XXX
 SG_ HVESP7Module23OperationalStatus : 44|2@1+ (1,0) [0|3] "" Vector__XXX
 SG_ HVESP7Module24OperationalStatus : 46|2@1+ (1,0) [0|3] "" Vector__XXX
 SG_ HVESP7Module25OperationalStatus : 48|2@1+ (1,0) [0|3] "" Vector__XXX
 SG_ HVESP7Module26OperationalStatus : 50|2@1+ (1,0) [0|3] "" Vector__XXX
 SG_ HVESP7Module27OperationalStatus : 52|2@1+ (1,0) [0|3] "" Vector__XXX
 SG_ HVESP7Module28OperationalStatus : 54|2@1+ (1,0) [0|3] "" Vector__XXX
 SG_ HVESP7Module29OperationalStatus : 56|2@1+ (1,0) [0|3] "" Vector__XXX
 SG_ HVESP7Module30OperationalStatus : 58|2@1+ (1,0) [0|3] "" Vector__XXX
 SG_ HVESP7Module31OperationalStatus : 60|2@1+ (1,0) [0|3] "" Vector__XXX
 SG_ HVESP7Module32OperationalStatus : 62|2@1+ (1,0) [0|3] "" Vector__XXX

BO_ 2364677886 HVESP7TS1: 8 Vector__XXX
 SG_ HVESP7ThrmlMngmntSstmSLIInptPwr : 0|16@1+ (0.5,0) [0|32127.5] "W" Vector__XXX
 SG_ HVESP7TMtSstHVtIptPw : 16|16@1+ (0.5,0) [0|32127.5] "W" Vector__XXX
 SG_ HVESP7ThrmlMngmntSstmCmprssrSpd : 32|8@1+ (32,0) [0|8000] "rpm" Vector__XXX
 SG_ HVESP7ThrmlMngmntSstmRltvHmdt : 40|8@1+ (0.4,0) [0|100] "%" Vector__XXX
 SG_ HVESP7ThrmlMngmntSstmHtrStts : 48|2@1+ (1,0) [0|3] "" Vector__XXX
 SG_ HVESP7ThrmlMngmntSstmHVILStts : 50|2@1+ (1,0) [0|3] "" Vector__XXX
 SG_ HVESP7ThrmlMngmntSstmMd : 52|4@1+ (1,0) [0|15] "" Vector__XXX
 SG_ HVESP7ThrmlMngmntSstmClntLvl : 56|2@1+ (1,0) [0|3] "" Vector__XXX

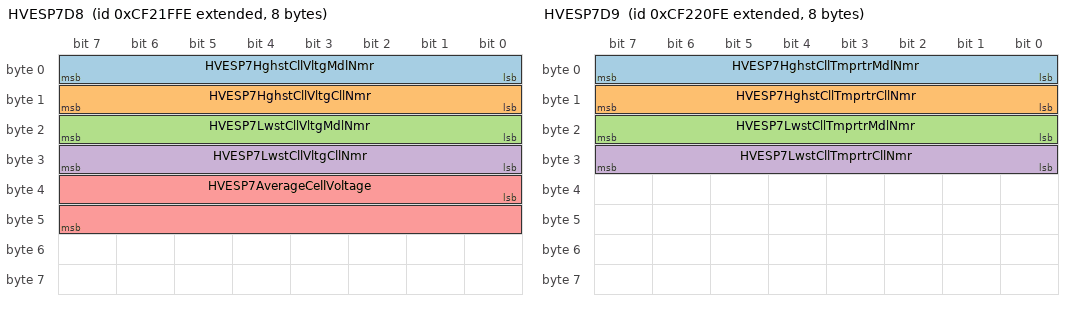
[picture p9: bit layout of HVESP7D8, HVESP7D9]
BO_ 2364678142 HVESP7D8: 8 Vector__XXX
 SG_ HVESP7HghstCllVltgMdlNmr : 0|8@1+ (1,0) [0|250] "count" Vector__XXX
 SG_ HVESP7HghstCllVltgCllNmr : 8|8@1+ (1,0) [0|250] "count" Vector__XXX
 SG_ HVESP7LwstCllVltgMdlNmr : 16|8@1+ (1,0) [0|250] "count" Vector__XXX
 SG_ HVESP7LwstCllVltgCllNmr : 24|8@1+ (1,0) [0|250] "count" Vector__XXX
 SG_ HVESP7AverageCellVoltage : 32|16@1+ (0.001,0) [0|64.255] "V" Vector__XXX

BO_ 2364678398 HVESP7D9: 8 Vector__XXX
 SG_ HVESP7HghstCllTmprtrMdlNmr : 0|8@1+ (1,0) [0|250] "count" Vector__XXX
 SG_ HVESP7HghstCllTmprtrCllNmr : 8|8@1+ (1,0) [0|250] "count" Vector__XXX
 SG_ HVESP7LwstCllTmprtrMdlNmr : 16|8@1+ (1,0) [0|250] "count" Vector__XXX
 SG_ HVESP7LwstCllTmprtrCllNmr : 24|8@1+ (1,0) [0|250] "count" Vector__XXX

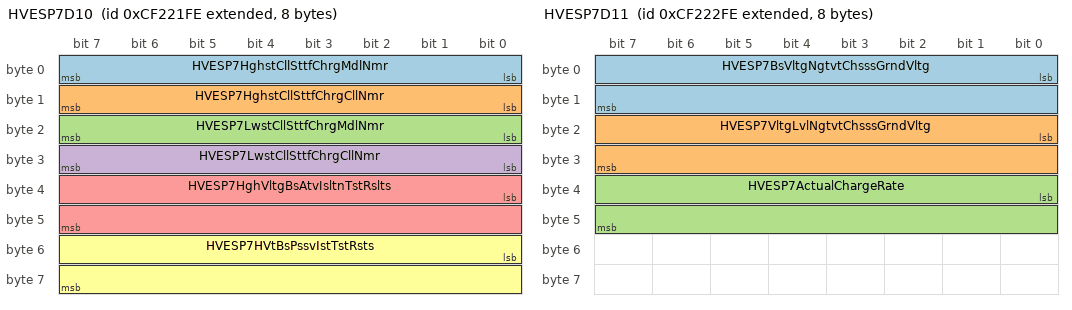
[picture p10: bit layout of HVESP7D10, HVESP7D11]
BO_ 2364678654 HVESP7D10: 8 Vector__XXX
 SG_ HVESP7HghstCllSttfChrgMdlNmr : 0|8@1+ (1,0) [0|250] "count" Vector__XXX
 SG_ HVESP7HghstCllSttfChrgCllNmr : 8|8@1+ (1,0) [0|250] "count" Vector__XXX
 SG_ HVESP7LwstCllSttfChrgMdlNmr : 16|8@1+ (1,0) [0|250] "count" Vector__XXX
 SG_ HVESP7LwstCllSttfChrgCllNmr : 24|8@1+ (1,0) [0|250] "count" Vector__XXX
 SG_ HVESP7HghVltgBsAtvIsltnTstRslts : 32|16@1+ (0.1,0) [0|6425.5] "ohm/V" Vector__XXX
 SG_ HVESP7HVtBsPssvIstTstRsts : 48|16@1+ (0.1,0) [0|6425.5] "ohm/V" Vector__XXX

BO_ 2364678910 HVESP7D11: 8 Vector__XXX
 SG_ HVESP7BsVltgNgtvtChsssGrndVltg : 0|16@1+ (0.05,0) [0|3212.75] "V" Vector__XXX
 SG_ HVESP7VltgLvlNgtvtChsssGrndVltg : 16|16@1+ (0.05,0) [0|3212.75] "V" Vector__XXX
 SG_ HVESP7ActualChargeRate : 32|16@1+ (0.05,0) [0|3212.75] "kW" Vector__XXX

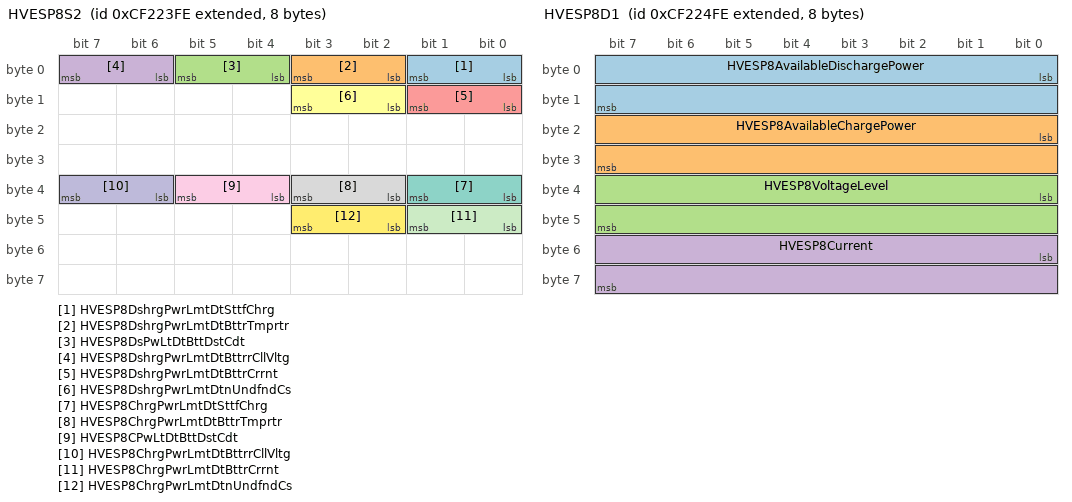
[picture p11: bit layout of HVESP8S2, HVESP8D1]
BO_ 2364679166 HVESP8S2: 8 Vector__XXX
 SG_ HVESP8DshrgPwrLmtDtSttfChrg : 0|2@1+ (1,0) [0|3] "" Vector__XXX
 SG_ HVESP8DshrgPwrLmtDtBttrTmprtr : 2|2@1+ (1,0) [0|3] "" Vector__XXX
 SG_ HVESP8DsPwLtDtBttDstCdt : 4|2@1+ (1,0) [0|3] "" Vector__XXX
 SG_ HVESP8DshrgPwrLmtDtBttrrCllVltg : 6|2@1+ (1,0) [0|3] "" Vector__XXX
 SG_ HVESP8DshrgPwrLmtDtBttrCrrnt : 8|2@1+ (1,0) [0|3] "" Vector__XXX
 SG_ HVESP8DshrgPwrLmtDtnUndfndCs : 10|2@1+ (1,0) [0|3] "" Vector__XXX
 SG_ HVESP8ChrgPwrLmtDtSttfChrg : 32|2@1+ (1,0) [0|3] "" Vector__XXX
 SG_ HVESP8ChrgPwrLmtDtBttrTmprtr : 34|2@1+ (1,0) [0|3] "" Vector__XXX
 SG_ HVESP8CPwLtDtBttDstCdt : 36|2@1+ (1,0) [0|3] "" Vector__XXX
 SG_ HVESP8ChrgPwrLmtDtBttrrCllVltg : 38|2@1+ (1,0) [0|3] "" Vector__XXX
 SG_ HVESP8ChrgPwrLmtDtBttrCrrnt : 40|2@1+ (1,0) [0|3] "" Vector__XXX
 SG_ HVESP8ChrgPwrLmtDtnUndfndCs : 42|2@1+ (1,0) [0|3] "" Vector__XXX

BO_ 2364679422 HVESP8D1: 8 Vector__XXX
 SG_ HVESP8AvailableDischargePower : 0|16@1+ (0.05,0) [0|3212.75] "kW" Vector__XXX
 SG_ HVESP8AvailableChargePower : 16|16@1+ (0.05,0) [0|3212.75] "kW" Vector__XXX
 SG_ HVESP8VoltageLevel : 32|16@1+ (0.05,0) [0|3212.75] "V" Vector__XXX
 SG_ HVESP8Current : 48|16@1+ (0.05,-1600) [-1600|1612.75] "A" Vector__XXX

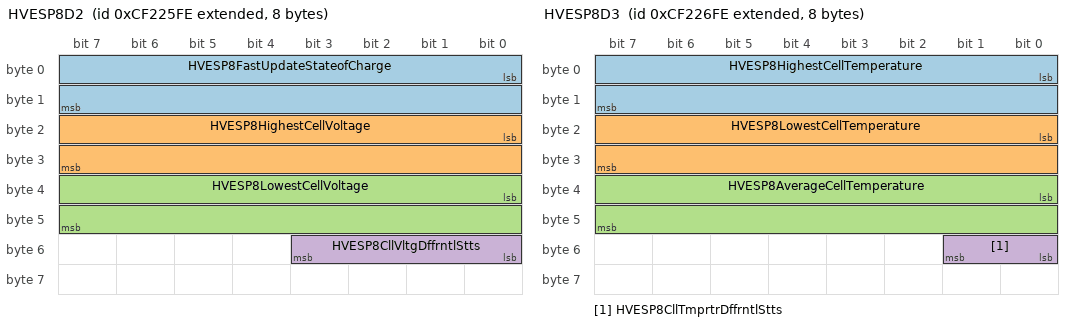
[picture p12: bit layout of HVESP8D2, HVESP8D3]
BO_ 2364679678 HVESP8D2: 8 Vector__XXX
 SG_ HVESP8FastUpdateStateofCharge : 0|16@1+ (0.0015625,0) [0|100.3984375] "%" Vector__XXX
 SG_ HVESP8HighestCellVoltage : 16|16@1+ (0.001,0) [0|64.255] "V" Vector__XXX
 SG_ HVESP8LowestCellVoltage : 32|16@1+ (0.001,0) [0|64.255] "V" Vector__XXX
 SG_ HVESP8CllVltgDffrntlStts : 48|4@1+ (1,0) [0|15] "" Vector__XXX

BO_ 2364679934 HVESP8D3: 8 Vector__XXX
 SG_ HVESP8HighestCellTemperature : 0|16@1+ (0.03125,-273) [-273|1734.96875] "degC" Vector__XXX
 SG_ HVESP8LowestCellTemperature : 16|16@1+ (0.03125,-273) [-273|1734.96875] "degC" Vector__XXX
 SG_ HVESP8AverageCellTemperature : 32|16@1+ (0.03125,-273) [-273|1734.96875] "degC" Vector__XXX
 SG_ HVESP8CllTmprtrDffrntlStts : 48|2@1+ (1,0) [0|3] "" Vector__XXX

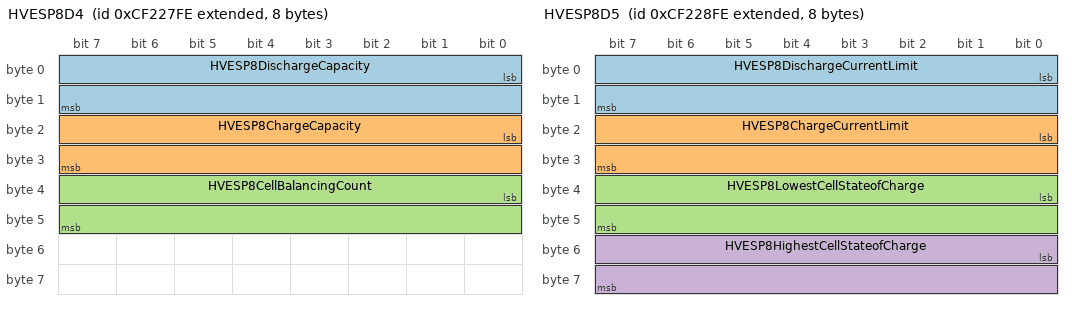
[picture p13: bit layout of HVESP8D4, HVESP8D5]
BO_ 2364680190 HVESP8D4: 8 Vector__XXX
 SG_ HVESP8DischargeCapacity : 0|16@1+ (0.01,0) [0|642.55] "Ah" Vector__XXX
 SG_ HVESP8ChargeCapacity : 16|16@1+ (0.01,0) [0|642.55] "Ah" Vector__XXX
 SG_ HVESP8CellBalancingCount : 32|16@1+ (1,0) [0|64255] "count" Vector__XXX

BO_ 2364680446 HVESP8D5: 8 Vector__XXX
 SG_ HVESP8DischargeCurrentLimit : 0|16@1+ (0.05,-1600) [-1600|1612.75] "A" Vector__XXX
 SG_ HVESP8ChargeCurrentLimit : 16|16@1+ (0.05,-1600) [-1600|1612.75] "A" Vector__XXX
 SG_ HVESP8LowestCellStateofCharge : 32|16@1+ (0.0015625,0) [0|100.3984375] "%" Vector__XXX
 SG_ HVESP8HighestCellStateofCharge : 48|16@1+ (0.0015625,0) [0|100.3984375] "%" Vector__XXX

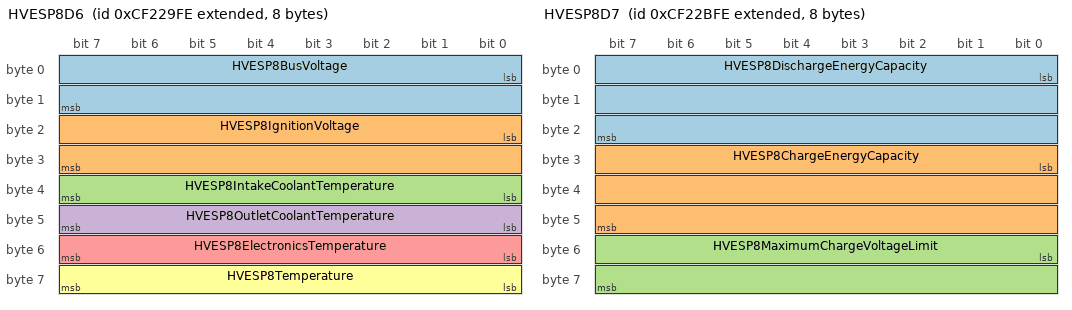
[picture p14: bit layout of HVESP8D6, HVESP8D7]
BO_ 2364680702 HVESP8D6: 8 Vector__XXX
 SG_ HVESP8BusVoltage : 0|16@1+ (0.05,0) [0|3212.75] "V" Vector__XXX
 SG_ HVESP8IgnitionVoltage : 16|16@1+ (0.01,0) [0|642.55] "V" Vector__XXX
 SG_ HVESP8IntakeCoolantTemperature : 32|8@1+ (1,-40) [-40|210] "degC" Vector__XXX
 SG_ HVESP8OutletCoolantTemperature : 40|8@1+ (1,-40) [-40|210] "degC" Vector__XXX
 SG_ HVESP8ElectronicsTemperature : 48|8@1+ (1,-40) [-40|210] "degC" Vector__XXX
 SG_ HVESP8Temperature : 56|8@1+ (1,-40) [-40|210] "degC" Vector__XXX

BO_ 2364680958 HVESP8S1: 8 Vector__XXX
 SG_ HVESP8HghVltgBsPstvCnttrStt : 0|2@1+ (1,0) [0|3] "" Vector__XXX
 SG_ HVESP8HghVltgBsNgtvCnttrStt : 2|2@1+ (1,0) [0|3] "" Vector__XXX
 SG_ HVESP8HghVltgBsDsnntFrwrnng : 4|4@1+ (1,0) [0|15] "" Vector__XXX
 SG_ HVESP8HghVltgBsPrChrgRlStt : 8|2@1+ (1,0) [0|3] "" Vector__XXX
 SG_ HVESP8CntrfPkCnttrStt : 10|2@1+ (1,0) [0|3] "" Vector__XXX
 SG_ HVESP8HghVltgBsAtvIsltnTstStts : 12|4@1+ (1,0) [0|15] "" Vector__XXX
 SG_ HVESP8HghVltgBsPssvIsltnTstStts : 16|4@1+ (1,0) [0|15] "" Vector__XXX
 SG_ HVESP8HVILStatus : 20|2@1+ (1,0) [0|3] "" Vector__XXX
 SG_ HVESP8InertiaSwitchStatus : 22|2@1+ (1,0) [0|3] "" Vector__XXX
 SG_ HVESP8StateofChargeStatus : 24|4@1+ (1,0) [0|15] "" Vector__XXX
 SG_ HVESP8CellBalanceStatus : 28|2@1+ (1,0) [0|3] "" Vector__XXX
 SG_ HVESP8CellBalancingActive : 30|2@1+ (1,0) [0|3] "" Vector__XXX
 SG_ HVESP8InternalChargerStatus : 32|2@1+ (1,0) [0|3] "" Vector__XXX
 SG_ HVESP8HghVltgBsCnntnStts : 40|4@1+ (1,0) [0|15] "" Vector__XXX
 SG_ HVESP8OperationalStatus : 44|4@1+ (1,0) [0|15] "" Vector__XXX
 SG_ HVESP8Status1Counter : 52|4@1+ (1,0) [0|15] "" Vector__XXX
 SG_ HVESP8Status1CRC : 56|8@1+ (1,0) [0|255] "count" Vector__XXX

BO_ 2364681214 HVESP8D7: 8 Vector__XXX
 SG_ HVESP8DischargeEnergyCapacity : 0|24@1+ (0.001,0) [0|16449.535] "kWh" Vector__XXX
 SG_ HVESP8ChargeEnergyCapacity : 24|24@1+ (0.001,0) [0|16449.535] "kWh" Vector__XXX
 SG_ HVESP8MaximumChargeVoltageLimit : 48|16@1+ (0.05,0) [0|3212.75] "V" Vector__XXX

BO_ 2364681470 HVESP8MS1: 8 Vector__XXX
 SG_ HVESP8Module1OperationalStatus : 0|2@1+ (1,0) [0|3] "" Vector__XXX
 SG_ HVESP8Module2OperationalStatus : 2|2@1+ (1,0) [0|3] "" Vector__XXX
 SG_ HVESP8Module3OperationalStatus : 4|2@1+ (1,0) [0|3] "" Vector__XXX
 SG_ HVESP8Module4OperationalStatus : 6|2@1+ (1,0) [0|3] "" Vector__XXX
 SG_ HVESP8Module5OperationalStatus : 8|2@1+ (1,0) [0|3] "" Vector__XXX
 SG_ HVESP8Module6OperationalStatus : 10|2@1+ (1,0) [0|3] "" Vector__XXX
 SG_ HVESP8Module7OperationalStatus : 12|2@1+ (1,0) [0|3] "" Vector__XXX
 SG_ HVESP8Module8OperationalStatus : 14|2@1+ (1,0) [0|3] "" Vector__XXX
 SG_ HVESP8Module9OperationalStatus : 16|2@1+ (1,0) [0|3] "" Vector__XXX
 SG_ HVESP8Module10OperationalStatus : 18|2@1+ (1,0) [0|3] "" Vector__XXX
 SG_ HVESP8Module11OperationalStatus : 20|2@1+ (1,0) [0|3] "" Vector__XXX
 SG_ HVESP8Module12OperationalStatus : 22|2@1+ (1,0) [0|3] "" Vector__XXX
 SG_ HVESP8Module13OperationalStatus : 24|2@1+ (1,0) [0|3] "" Vector__XXX
 SG_ HVESP8Module14OperationalStatus : 26|2@1+ (1,0) [0|3] "" Vector__XXX
 SG_ HVESP8Module15OperationalStatus : 28|2@1+ (1,0) [0|3] "" Vector__XXX
 SG_ HVESP8Module16OperationalStatus : 30|2@1+ (1,0) [0|3] "" Vector__XXX
 SG_ HVESP8Module17OperationalStatus : 32|2@1+ (1,0) [0|3] "" Vector__XXX
 SG_ HVESP8Module18OperationalStatus : 34|2@1+ (1,0) [0|3] "" Vector__XXX
 SG_ HVESP8Module19OperationalStatus : 36|2@1+ (1,0) [0|3] "" Vector__XXX
 SG_ HVESP8Module20OperationalStatus : 38|2@1+ (1,0) [0|3] "" Vector__XXX
 SG_ HVESP8Module21OperationalStatus : 40|2@1+ (1,0) [0|3] "" Vector__XXX
 SG_ HVESP8Module22OperationalStatus : 42|2@1+ (1,0) [0|3] "" Vector__XXX
 SG_ HVESP8Module23OperationalStatus : 44|2@1+ (1,0) [0|3] "" Vector__XXX
 SG_ HVESP8Module24OperationalStatus : 46|2@1+ (1,0) [0|3] "" Vector__XXX
 SG_ HVESP8Module25OperationalStatus : 48|2@1+ (1,0) [0|3] "" Vector__XXX
 SG_ HVESP8Module26OperationalStatus : 50|2@1+ (1,0) [0|3] "" Vector__XXX
 SG_ HVESP8Module27OperationalStatus : 52|2@1+ (1,0) [0|3] "" Vector__XXX
 SG_ HVESP8Module28OperationalStatus : 54|2@1+ (1,0) [0|3] "" Vector__XXX
 SG_ HVESP8Module29OperationalStatus : 56|2@1+ (1,0) [0|3] "" Vector__XXX
 SG_ HVESP8Module30OperationalStatus : 58|2@1+ (1,0) [0|3] "" Vector__XXX
 SG_ HVESP8Module31OperationalStatus : 60|2@1+ (1,0) [0|3] "" Vector__XXX
 SG_ HVESP8Module32OperationalStatus : 62|2@1+ (1,0) [0|3] "" Vector__XXX

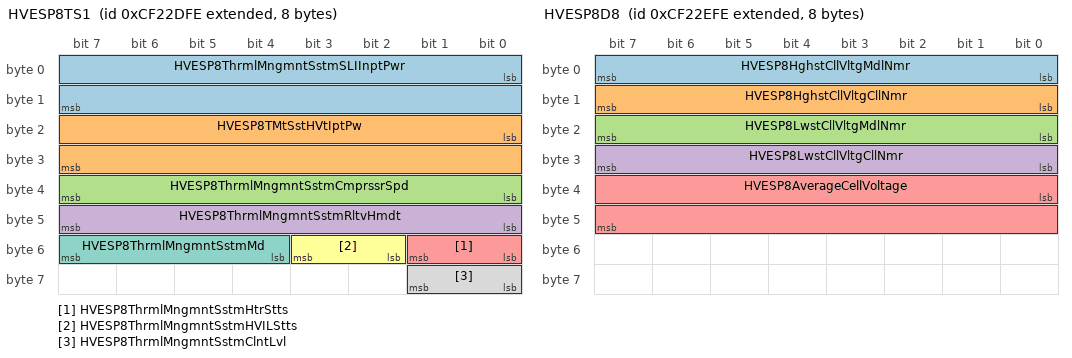
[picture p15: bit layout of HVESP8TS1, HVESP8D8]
BO_ 2364681726 HVESP8TS1: 8 Vector__XXX
 SG_ HVESP8ThrmlMngmntSstmSLIInptPwr : 0|16@1+ (0.5,0) [0|32127.5] "W" Vector__XXX
 SG_ HVESP8TMtSstHVtIptPw : 16|16@1+ (0.5,0) [0|32127.5] "W" Vector__XXX
 SG_ HVESP8ThrmlMngmntSstmCmprssrSpd : 32|8@1+ (32,0) [0|8000] "rpm" Vector__XXX
 SG_ HVESP8ThrmlMngmntSstmRltvHmdt : 40|8@1+ (0.4,0) [0|100] "%" Vector__XXX
 SG_ HVESP8ThrmlMngmntSstmHtrStts : 48|2@1+ (1,0) [0|3] "" Vector__XXX
 SG_ HVESP8ThrmlMngmntSstmHVILStts : 50|2@1+ (1,0) [0|3] "" Vector__XXX
 SG_ HVESP8ThrmlMngmntSstmMd : 52|4@1+ (1,0) [0|15] "" Vector__XXX
 SG_ HVESP8ThrmlMngmntSstmClntLvl : 56|2@1+ (1,0) [0|3] "" Vector__XXX

BO_ 2364681982 HVESP8D8: 8 Vector__XXX
 SG_ HVESP8HghstCllVltgMdlNmr : 0|8@1+ (1,0) [0|250] "count" Vector__XXX
 SG_ HVESP8HghstCllVltgCllNmr : 8|8@1+ (1,0) [0|250] "count" Vector__XXX
 SG_ HVESP8LwstCllVltgMdlNmr : 16|8@1+ (1,0) [0|250] "count" Vector__XXX
 SG_ HVESP8LwstCllVltgCllNmr : 24|8@1+ (1,0) [0|250] "count" Vector__XXX
 SG_ HVESP8AverageCellVoltage : 32|16@1+ (0.001,0) [0|64.255] "V" Vector__XXX

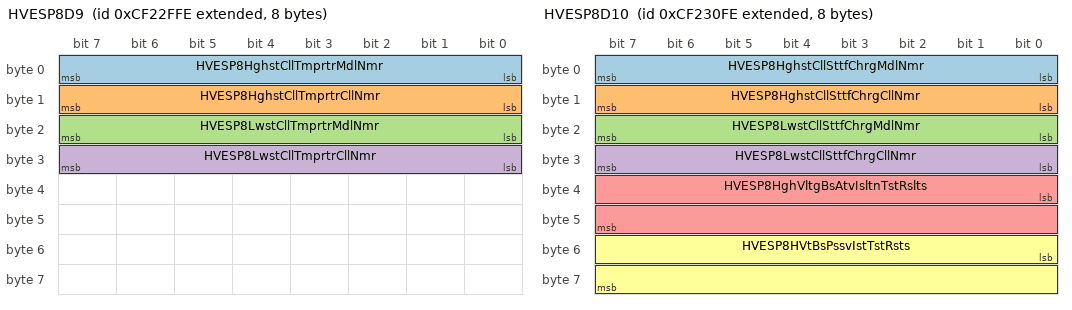
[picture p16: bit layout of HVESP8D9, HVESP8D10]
BO_ 2364682238 HVESP8D9: 8 Vector__XXX
 SG_ HVESP8HghstCllTmprtrMdlNmr : 0|8@1+ (1,0) [0|250] "count" Vector__XXX
 SG_ HVESP8HghstCllTmprtrCllNmr : 8|8@1+ (1,0) [0|250] "count" Vector__XXX
 SG_ HVESP8LwstCllTmprtrMdlNmr : 16|8@1+ (1,0) [0|250] "count" Vector__XXX
 SG_ HVESP8LwstCllTmprtrCllNmr : 24|8@1+ (1,0) [0|250] "count" Vector__XXX

BO_ 2364682494 HVESP8D10: 8 Vector__XXX
 SG_ HVESP8HghstCllSttfChrgMdlNmr : 0|8@1+ (1,0) [0|250] "count" Vector__XXX
 SG_ HVESP8HghstCllSttfChrgCllNmr : 8|8@1+ (1,0) [0|250] "count" Vector__XXX
 SG_ HVESP8LwstCllSttfChrgMdlNmr : 16|8@1+ (1,0) [0|250] "count" Vector__XXX
 SG_ HVESP8LwstCllSttfChrgCllNmr : 24|8@1+ (1,0) [0|250] "count" Vector__XXX
 SG_ HVESP8HghVltgBsAtvIsltnTstRslts : 32|16@1+ (0.1,0) [0|6425.5] "ohm/V" Vector__XXX
 SG_ HVESP8HVtBsPssvIstTstRsts : 48|16@1+ (0.1,0) [0|6425.5] "ohm/V" Vector__XXX

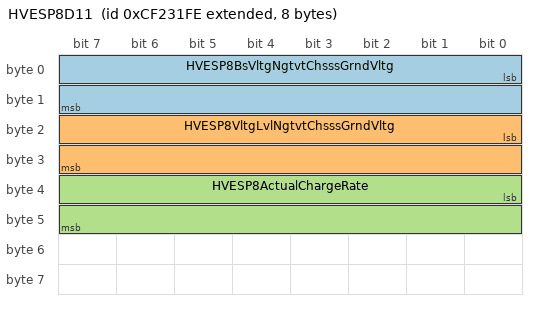
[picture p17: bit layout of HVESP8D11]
BO_ 2364682750 HVESP8D11: 8 Vector__XXX
 SG_ HVESP8BsVltgNgtvtChsssGrndVltg : 0|16@1+ (0.05,0) [0|3212.75] "V" Vector__XXX
 SG_ HVESP8VltgLvlNgtvtChsssGrndVltg : 16|16@1+ (0.05,0) [0|3212.75] "V" Vector__XXX
 SG_ HVESP8ActualChargeRate : 32|16@1+ (0.05,0) [0|3212.75] "kW" Vector__XXX

CM_ BO_ 2633719294 "Vehicle Fire Suppression System Module 3 Detector Data";
CM_ SG_ 2633719294 VFSSMdl3Dttr1DttrTp "VFSS Module 3 Detector 1 Detector Type: The type of detector for detector 1 of module 3.0 = Analog thermal sensor1 = Analog gas sensor2 = Analog optical sensor3 = Heat detector4 = Manual release switch5 = SAE Reserved6 = SAE Reserved7 = SAE Reserved8...";
CM_ SG_ 2633719294 VFSSMdl3Dttr1DttrDtSLOT "VFSS Module 3 Detector 1 Detector Data SLOT: The SAE SLOT encoding used for data reported in SPN 10871 (VFSS Module 3 Detector 1 Data) for this detector instance of this module.0 = SAEev03 (voltage)1 = SAEpc07 (percent)2 = SAEtp02 (temperature)3 = SA...";
CM_ SG_ 2633719294 VFSSMdl3Dttr2DttrTp "VFSS Module 3 Detector 2 Detector Type: The type of detector for detector 2 of module 3.0 = Analog thermal sensor1 = Analog gas sensor2 = Analog optical sensor3 = Heat detector4 = Manual release switch5 = SAE Reserved6 = SAE Reserved7 = SAE Reserved8...";
CM_ SG_ 2633719294 VFSSMdl3Dttr2DttrDtSLOT "VFSS Module 3 Detector 2 Detector Data SLOT: The SAE SLOT encoding used for data reported in SPN 10871 (VFSS Module 3 Detector 2 Data) for this detector instance of this module.0 = SAEev03 (voltage)1 = SAEpc07 (percent)2 = SAEtp02 (temperature)3 = SA...";
CM_ SG_ 2633719294 VFSSMdl3Dttr3DttrTp "VFSS Module 3 Detector 3 Detector Type: The type of detector for detector 3 of module 3.0 = Analog thermal sensor1 = Analog gas sensor2 = Analog optical sensor3 = Heat detector4 = Manual release switch5 = SAE Reserved6 = SAE Reserved7 = SAE Reserved8...";
CM_ SG_ 2633719294 VFSSMdl3Dttr3DttrDtSLOT "VFSS Module 3 Detector 3 Detector Data SLOT: The SAE SLOT encoding used for data reported in SPN 10871 (VFSS Module 3 Detector 3 Data) for this detector instance of this module.0 = SAEev03 (voltage)1 = SAEpc07 (percent)2 = SAEtp02 (temperature)3 = SA...";
CM_ SG_ 2633719294 VFSSMdl3Dttr4DttrTp "VFSS Module 3 Detector 4 Detector Type: The type of detector for detector 4 of module 3.0 = Analog thermal sensor1 = Analog gas sensor2 = Analog optical sensor3 = Heat detector4 = Manual release switch5 = SAE Reserved6 = SAE Reserved7 = SAE Reserved8...";
CM_ SG_ 2633719294 VFSSMdl3Dttr4DttrDtSLOT "VFSS Module 3 Detector 4 Detector Data SLOT: The SAE SLOT encoding used for data reported in SPN 10871 (VFSS Module 3 Detector 4 Data) for this detector instance of this module.0 = SAEev03 (voltage)1 = SAEpc07 (percent)2 = SAEtp02 (temperature)3 = SA...";
CM_ SG_ 2633719294 VFSSMdl3Dttr5DttrTp "VFSS Module 3 Detector 5 Detector Type: The type of detector for detector 5 of module 3.0 = Analog thermal sensor1 = Analog gas sensor2 = Analog optical sensor3 = Heat detector4 = Manual release switch5 = SAE Reserved6 = SAE Reserved7 = SAE Reserved8...";
CM_ SG_ 2633719294 VFSSMdl3Dttr5DttrDtSLOT "VFSS Module 3 Detector 5 Detector Data SLOT: The SAE SLOT encoding used for data reported in SPN 10871 (VFSS Module 3 Detector 5 Data) for this detector instance of this module.0 = SAEev03 (voltage)1 = SAEpc07 (percent)2 = SAEtp02 (temperature)3 = SA...";
CM_ SG_ 2633719294 VFSSMdl3Dttr6DttrTp "VFSS Module 3 Detector 6 Detector Type: The type of detector for detector 6 of module 3.0 = Analog thermal sensor1 = Analog gas sensor2 = Analog optical sensor3 = Heat detector4 = Manual release switch5 = SAE Reserved6 = SAE Reserved7 = SAE Reserved8...";
CM_ SG_ 2633719294 VFSSMdl3Dttr6DttrDtSLOT "VFSS Module 3 Detector 6 Detector Data SLOT: The SAE SLOT encoding used for data reported in SPN 10871 (VFSS Module 3 Detector 6 Data) for this detector instance of this module.0 = SAEev03 (voltage)1 = SAEpc07 (percent)2 = SAEtp02 (temperature)3 = SA...";
CM_ SG_ 2633719294 VFSSMdl3Dttr7DttrTp "VFSS Module 3 Detector 7 Detector Type: The type of detector for detector 7 of module 3.0 = Analog thermal sensor1 = Analog gas sensor2 = Analog optical sensor3 = Heat detector4 = Manual release switch5 = SAE Reserved6 = SAE Reserved7 = SAE Reserved8...";
CM_ SG_ 2633719294 VFSSMdl3Dttr7DttrDtSLOT "VFSS Module 3 Detector 7 Detector Data SLOT: The SAE SLOT encoding used for data reported in SPN 10871 (VFSS Module 3 Detector 7 Data) for this detector instance of this module.0 = SAEev03 (voltage)1 = SAEpc07 (percent)2 = SAEtp02 (temperature)3 = SA...";
CM_ SG_ 2633719294 VFSSMdl3Dttr8DttrTp "VFSS Module 3 Detector 8 Detector Type: The type of detector for detector 8 of module 3.0 = Analog thermal sensor1 = Analog gas sensor2 = Analog optical sensor3 = Heat detector4 = Manual release switch5 = SAE Reserved6 = SAE Reserved7 = SAE Reserved8...";
CM_ SG_ 2633719294 VFSSMdl3Dttr8DttrDtSLOT "VFSS Module 3 Detector 8 Detector Data SLOT: The SAE SLOT encoding used for data reported in SPN 10871 (VFSS Module 3 Detector 8 Data) for this detector instance of this module.0 = SAEev03 (voltage)1 = SAEpc07 (percent)2 = SAEtp02 (temperature)3 = SA...";
CM_ BO_ 2633719550 "Vehicle Fire Suppression System Module 4 Detector Data";
CM_ SG_ 2633719550 VFSSMdl4Dttr1DttrTp "VFSS Module 4 Detector 1 Detector Type: The type of detector for detector 1 of module 4.0 = Analog thermal sensor1 = Analog gas sensor2 = Analog optical sensor3 = Heat detector4 = Manual release switch5 = SAE Reserved6 = SAE Reserved7 = SAE Reserved8...";
CM_ SG_ 2633719550 VFSSMdl4Dttr1DttrDtSLOT "VFSS Module 4 Detector 1 Detector Data SLOT: The SAE SLOT encoding used for data reported in SPN 10871 (VFSS Module 4 Detector 1 Data) for this detector instance of this module.0 = SAEev03 (voltage)1 = SAEpc07 (percent)2 = SAEtp02 (temperature)3 = SA...";
CM_ SG_ 2633719550 VFSSMdl4Dttr2DttrTp "VFSS Module 4 Detector 2 Detector Type: The type of detector for detector 2 of module 4.0 = Analog thermal sensor1 = Analog gas sensor2 = Analog optical sensor3 = Heat detector4 = Manual release switch5 = SAE Reserved6 = SAE Reserved7 = SAE Reserved8...";
CM_ SG_ 2633719550 VFSSMdl4Dttr2DttrDtSLOT "VFSS Module 4 Detector 2 Detector Data SLOT: The SAE SLOT encoding used for data reported in SPN 10871 (VFSS Module 4 Detector 2 Data) for this detector instance of this module.0 = SAEev03 (voltage)1 = SAEpc07 (percent)2 = SAEtp02 (temperature)3 = SA...";
CM_ SG_ 2633719550 VFSSMdl4Dttr3DttrTp "VFSS Module 4 Detector 3 Detector Type: The type of detector for detector 3 of module 4.0 = Analog thermal sensor1 = Analog gas sensor2 = Analog optical sensor3 = Heat detector4 = Manual release switch5 = SAE Reserved6 = SAE Reserved7 = SAE Reserved8...";
CM_ SG_ 2633719550 VFSSMdl4Dttr3DttrDtSLOT "VFSS Module 4 Detector 3 Detector Data SLOT: The SAE SLOT encoding used for data reported in SPN 10871 (VFSS Module 4 Detector 3 Data) for this detector instance of this module.0 = SAEev03 (voltage)1 = SAEpc07 (percent)2 = SAEtp02 (temperature)3 = SA...";
CM_ SG_ 2633719550 VFSSMdl4Dttr4DttrTp "VFSS Module 4 Detector 4 Detector Type: The type of detector for detector 4 of module 4.0 = Analog thermal sensor1 = Analog gas sensor2 = Analog optical sensor3 = Heat detector4 = Manual release switch5 = SAE Reserved6 = SAE Reserved7 = SAE Reserved8...";
CM_ SG_ 2633719550 VFSSMdl4Dttr4DttrDtSLOT "VFSS Module 4 Detector 4 Detector Data SLOT: The SAE SLOT encoding used for data reported in SPN 10871 (VFSS Module 4 Detector 4 Data) for this detector instance of this module.0 = SAEev03 (voltage)1 = SAEpc07 (percent)2 = SAEtp02 (temperature)3 = SA...";
CM_ SG_ 2633719550 VFSSMdl4Dttr5DttrTp "VFSS Module 4 Detector 5 Detector Type: The type of detector for detector 5 of module 4.0 = Analog thermal sensor1 = Analog gas sensor2 = Analog optical sensor3 = Heat detector4 = Manual release switch5 = SAE Reserved6 = SAE Reserved7 = SAE Reserved8...";
CM_ SG_ 2633719550 VFSSMdl4Dttr5DttrDtSLOT "VFSS Module 4 Detector 5 Detector Data SLOT: The SAE SLOT encoding used for data reported in SPN 10871 (VFSS Module 4 Detector 5 Data) for this detector instance of this module.0 = SAEev03 (voltage)1 = SAEpc07 (percent)2 = SAEtp02 (temperature)3 = SA...";
CM_ SG_ 2633719550 VFSSMdl4Dttr6DttrTp "VFSS Module 4 Detector 6 Detector Type: The type of detector for detector 6 of module 4.0 = Analog thermal sensor1 = Analog gas sensor2 = Analog optical sensor3 = Heat detector4 = Manual release switch5 = SAE Reserved6 = SAE Reserved7 = SAE Reserved8...";
CM_ SG_ 2633719550 VFSSMdl4Dttr6DttrDtSLOT "VFSS Module 4 Detector 6 Detector Data SLOT: The SAE SLOT encoding used for data reported in SPN 10871 (VFSS Module 4 Detector 6 Data) for this detector instance of this module.0 = SAEev03 (voltage)1 = SAEpc07 (percent)2 = SAEtp02 (temperature)3 = SA...";
CM_ SG_ 2633719550 VFSSMdl4Dttr7DttrTp "VFSS Module 4 Detector 7 Detector Type: The type of detector for detector 7 of module 4.0 = Analog thermal sensor1 = Analog gas sensor2 = Analog optical sensor3 = Heat detector4 = Manual release switch5 = SAE Reserved6 = SAE Reserved7 = SAE Reserved8...";
CM_ SG_ 2633719550 VFSSMdl4Dttr7DttrDtSLOT "VFSS Module 4 Detector 7 Detector Data SLOT: The SAE SLOT encoding used for data reported in SPN 10871 (VFSS Module 4 Detector 7 Data) for this detector instance of this module.0 = SAEev03 (voltage)1 = SAEpc07 (percent)2 = SAEtp02 (temperature)3 = SA...";
CM_ SG_ 2633719550 VFSSMdl4Dttr8DttrTp "VFSS Module 4 Detector 8 Detector Type: The type of detector for detector 8 of module 4.0 = Analog thermal sensor1 = Analog gas sensor2 = Analog optical sensor3 = Heat detector4 = Manual release switch5 = SAE Reserved6 = SAE Reserved7 = SAE Reserved8...";
CM_ SG_ 2633719550 VFSSMdl4Dttr8DttrDtSLOT "VFSS Module 4 Detector 8 Detector Data SLOT: The SAE SLOT encoding used for data reported in SPN 10871 (VFSS Module 4 Detector 8 Data) for this detector instance of this module.0 = SAEev03 (voltage)1 = SAEpc07 (percent)2 = SAEtp02 (temperature)3 = SA...";
CM_ BO_ 2633719806 "Vehicle Fire Suppression System Module 1 Auxilliary Data";
CM_ SG_ 2633719806 VFSSModule1HeatZone1Data "VFSS Module 1 Heat Zone 1 Data: Current measured value for heat zone 1 of module 1.";
CM_ SG_ 2633719806 VFSSModule1HeatZone2Data "VFSS Module 1 Heat Zone 2 Data: Current measured value for heat zone 2 of module 1.";
CM_ SG_ 2633719806 VFSSModule1ReleaseZone1Data "VFSS Module 1 Release Zone 1 Data: Current measured value for release zone 1 of module 1.";
CM_ SG_ 2633719806 VFSSModule1ReleaseZone2Data "VFSS Module 1 Release Zone 2 Data: Current measured value for release zone 2 of module 1.";
CM_ SG_ 2633719806 VFSSModule1PressureSwitch1Data "VFSS Module 1 Pressure Switch 1 Data: Current measured value for pressure switch 1 of module 1.";
CM_ SG_ 2633719806 VFSSModule1PressureSwitch2Data "VFSS Module 1 Pressure Switch 2 Data: Current measured value for pressure switch 2 of module 1.";
CM_ SG_ 2633719806 VFSSModule1PrimaryPowerVoltage "VFSS Module 1 Primary Power Voltage: Current measured value for primary power voltage of module 1.";
CM_ SG_ 2633719806 VFSSMdl1SndrPwrVltg "VFSS Module 1 Secondary Power Voltage: Current measured value for secondary power voltage of module 1.";
CM_ BO_ 2633720062 "Vehicle Fire Suppression System Module 2 Auxilliary Data";
CM_ SG_ 2633720062 VFSSModule2HeatZone1Data "VFSS Module 2 Heat Zone 1 Data: Current measured value for heat zone 1 of module 2.";
CM_ SG_ 2633720062 VFSSModule2HeatZone2Data "VFSS Module 2 Heat Zone 2 Data: Current measured value for heat zone 2 of module 2.";
CM_ SG_ 2633720062 VFSSModule2ReleaseZone1Data "VFSS Module 2 Release Zone 1 Data: Current measured value for release zone 1 of module 2.";
CM_ SG_ 2633720062 VFSSModule2ReleaseZone2Data "VFSS Module 2 Release Zone 2 Data: Current measured value for release zone 2 of module 2.";
CM_ SG_ 2633720062 VFSSModule2PressureSwitch1Data "VFSS Module 2 Pressure Switch 1 Data: Current measured value for pressure switch 1 of module 2.";
CM_ SG_ 2633720062 VFSSModule2PressureSwitch2Data "VFSS Module 2 Pressure Switch 2 Data: Current measured value for pressure switch 2 of module 2.";
CM_ SG_ 2633720062 VFSSModule2PrimaryPowerVoltage "VFSS Module 2 Primary Power Voltage: Current measured value for primary power voltage of module 2.";
CM_ SG_ 2633720062 VFSSMdl2SndrPwrVltg "VFSS Module 2 Secondary Power Voltage: Current measured value for secondary power voltage of module 2.";
CM_ BO_ 2633720318 "Vehicle Fire Suppression System Module 3 Auxilliary Data";
CM_ SG_ 2633720318 VFSSModule3HeatZone1Data "VFSS Module 3 Heat Zone 1 Data: Current measured value for heat zone 1 of module 3.";
CM_ SG_ 2633720318 VFSSModule3HeatZone2Data "VFSS Module 3 Heat Zone 2 Data: Current measured value for heat zone 2 of module 3.";
CM_ SG_ 2633720318 VFSSModule3ReleaseZone1Data "VFSS Module 3 Release Zone 1 Data: Current measured value for release zone 1 of module 3.";
CM_ SG_ 2633720318 VFSSModule3ReleaseZone2Data "VFSS Module 3 Release Zone 2 Data: Current measured value for release zone 2 of module 3.";
CM_ SG_ 2633720318 VFSSModule3PressureSwitch1Data "VFSS Module 3 Pressure Switch 1 Data: Current measured value for pressure switch 1 of module 3.";
CM_ SG_ 2633720318 VFSSModule3PressureSwitch2Data "VFSS Module 3 Pressure Switch 2 Data: Current measured value for pressure switch 2 of module 3.";
CM_ SG_ 2633720318 VFSSModule3PrimaryPowerVoltage "VFSS Module 3 Primary Power Voltage: Current measured value for primary power voltage of module 3.";
CM_ SG_ 2633720318 VFSSMdl3SndrPwrVltg "VFSS Module 3 Secondary Power Voltage: Current measured value for secondary power voltage of module 3.";
CM_ BO_ 2633720574 "Vehicle Fire Suppression System Module 4 Auxilliary Data";
CM_ SG_ 2633720574 VFSSModule4HeatZone1Data "VFSS Module 4 Heat Zone 1 Data: Current measured value for heat zone 1 of module 4.";
CM_ SG_ 2633720574 VFSSModule4HeatZone2Data "VFSS Module 4 Heat Zone 2 Data: Current measured value for heat zone 2 of module 4.";
CM_ SG_ 2633720574 VFSSModule4ReleaseZone1Data "VFSS Module 4 Release Zone 1 Data: Current measured value for release zone 1 of module 4.";
CM_ SG_ 2633720574 VFSSModule4ReleaseZone2Data "VFSS Module 4 Release Zone 2 Data: Current measured value for release zone 2 of module 4.";
CM_ SG_ 2633720574 VFSSModule4PressureSwitch1Data "VFSS Module 4 Pressure Switch 1 Data: Current measured value for pressure switch 1 of module 4.";
CM_ SG_ 2633720574 VFSSModule4PressureSwitch2Data "VFSS Module 4 Pressure Switch 2 Data: Current measured value for pressure switch 2 of module 4.";
CM_ SG_ 2633720574 VFSSModule4PrimaryPowerVoltage "VFSS Module 4 Primary Power Voltage: Current measured value for primary power voltage of module 4.";
CM_ SG_ 2633720574 VFSSMdl4SndrPwrVltg "VFSS Module 4 Secondary Power Voltage: Current measured value for secondary power voltage of module 4.";
CM_ BO_ 2633720830 "Vehicle Fire Suppression System Module 1 Names";
CM_ SG_ 2633720830 VFSSModule1Name "VFSS Module 1 Name: Descriptive name for the VFSS module/zone 1.";
CM_ SG_ 2633720830 VFSSModule1DetectorZone1Name "VFSS Module 1 Detector Zone 1 Name: Descriptive name for detector zone 1 of module 1.";
CM_ SG_ 2633720830 VFSSModule1DetectorZone2Name "VFSS Module 1 Detector Zone 2 Name: Descriptive name for detector zone 2 of module 1.";
CM_ SG_ 2633720830 VFSSModule1DetectorZone3Name "VFSS Module 1 Detector Zone 3 Name: Descriptive name for detector zone 3 of module 1.";
CM_ SG_ 2633720830 VFSSModule1DetectorZone4Name "VFSS Module 1 Detector Zone 4 Name: Descriptive name for detector zone 4 of module 1.";
CM_ SG_ 2633720830 VFSSModule1DetectorZone5Name "VFSS Module 1 Detector Zone 5 Name: Descriptive name for detector zone 5 of module 1.";
CM_ SG_ 2633720830 VFSSModule1DetectorZone6Name "VFSS Module 1 Detector Zone 6 Name: Descriptive name for detector zone 6 of module 1.";
CM_ SG_ 2633720830 VFSSModule1DetectorZone7Name "VFSS Module 1 Detector Zone 7 Name: Descriptive name for detector zone 7 of module 1.";
CM_ SG_ 2633720830 VFSSModule1DetectorZone8Name "VFSS Module 1 Detector Zone 8 Name: Descriptive name for detector zone 8 of module 1.";
CM_ SG_ 2633720830 VFSSModule1HeatZone1Name "VFSS Module 1 Heat Zone 1 Name: Descriptive name for heat zone 1 of module 1.";
CM_ SG_ 2633720830 VFSSModule1HeatZone2Name "VFSS Module 1 Heat Zone 2 Name: Descriptive name for heat zone 2 of module 1.";
CM_ SG_ 2633720830 VFSSModule1ReleaseZone1Name "VFSS Module 1 Release Zone 1 Name: Descriptive name for release zone 1 of module 1.";
CM_ SG_ 2633720830 VFSSModule1ReleaseZone2Name "VFSS Module 1 Release Zone 2 Name: Descriptive name for release zone 2 of module 1.";
CM_ BO_ 2633721086 "Vehicle Fire Suppression System Module 2 Names";
CM_ SG_ 2633721086 VFSSModule2Name "VFSS Module 2 Name: Descriptive name for the VFSS module/zone 2.";
CM_ SG_ 2633721086 VFSSModule2DetectorZone1Name "VFSS Module 2 Detector Zone 1 Name: Descriptive name for detector zone 1 of module 2.";
CM_ SG_ 2633721086 VFSSModule2DetectorZone2Name "VFSS Module 2 Detector Zone 2 Name: Descriptive name for detector zone 2 of module 2.";
CM_ SG_ 2633721086 VFSSModule2DetectorZone3Name "VFSS Module 2 Detector Zone 3 Name: Descriptive name for detector zone 3 of module 2.";
CM_ SG_ 2633721086 VFSSModule2DetectorZone4Name "VFSS Module 2 Detector Zone 4 Name: Descriptive name for detector zone 4 of module 2.";
CM_ SG_ 2633721086 VFSSModule2DetectorZone5Name "VFSS Module 2 Detector Zone 5 Name: Descriptive name for detector zone 5 of module 2.";
CM_ SG_ 2633721086 VFSSModule2DetectorZone6Name "VFSS Module 2 Detector Zone 6 Name: Descriptive name for detector zone 6 of module 2.";
CM_ SG_ 2633721086 VFSSModule2DetectorZone7Name "VFSS Module 2 Detector Zone 7 Name: Descriptive name for detector zone 7 of module 2.";
CM_ SG_ 2633721086 VFSSModule2DetectorZone8Name "VFSS Module 2 Detector Zone 8 Name: Descriptive name for detector zone 8 of module 2.";
CM_ SG_ 2633721086 VFSSModule2HeatZone1Name "VFSS Module 2 Heat Zone 1 Name: Descriptive name for heat zone 1 of module 2.";
CM_ SG_ 2633721086 VFSSModule2HeatZone2Name "VFSS Module 2 Heat Zone 2 Name: Descriptive name for heat zone 2 of module 2.";
CM_ SG_ 2633721086 VFSSModule2ReleaseZone1Name "VFSS Module 2 Release Zone 1 Name: Descriptive name for release zone 1 of module 2.";
CM_ SG_ 2633721086 VFSSModule2ReleaseZone2Name "VFSS Module 2 Release Zone 2 Name: Descriptive name for release zone 2 of module 2.";
CM_ BO_ 2633721342 "Vehicle Fire Suppression System Module 3 Names";
CM_ SG_ 2633721342 VFSSModule3Name "VFSS Module 3 Name: Descriptive name for the VFSS module/zone 3.";
CM_ SG_ 2633721342 VFSSModule3DetectorZone1Name "VFSS Module 3 Detector Zone 1 Name: Descriptive name for detector zone 1 of module 3.";
CM_ SG_ 2633721342 VFSSModule3DetectorZone2Name "VFSS Module 3 Detector Zone 2 Name: Descriptive name for detector zone 2 of module 3.";
CM_ SG_ 2633721342 VFSSModule3DetectorZone3Name "VFSS Module 3 Detector Zone 3 Name: Descriptive name for detector zone 3 of module 3.";
CM_ SG_ 2633721342 VFSSModule3DetectorZone4Name "VFSS Module 3 Detector Zone 4 Name: Descriptive name for detector zone 4 of module 3.";
CM_ SG_ 2633721342 VFSSModule3DetectorZone5Name "VFSS Module 3 Detector Zone 5 Name: Descriptive name for detector zone 5 of module 3.";
CM_ SG_ 2633721342 VFSSModule3DetectorZone6Name "VFSS Module 3 Detector Zone 6 Name: Descriptive name for detector zone 6 of module 3.";
CM_ SG_ 2633721342 VFSSModule3DetectorZone7Name "VFSS Module 3 Detector Zone 7 Name: Descriptive name for detector zone 7 of module 3.";
CM_ SG_ 2633721342 VFSSModule3DetectorZone8Name "VFSS Module 3 Detector Zone 8 Name: Descriptive name for detector zone 8 of module 3.";
CM_ SG_ 2633721342 VFSSModule3HeatZone1Name "VFSS Module 3 Heat Zone 1 Name: Descriptive name for heat zone 1 of module 3.";
CM_ SG_ 2633721342 VFSSModule3HeatZone2Name "VFSS Module 3 Heat Zone 2 Name: Descriptive name for heat zone 2 of module 3.";
CM_ SG_ 2633721342 VFSSModule3ReleaseZone1Name "VFSS Module 3 Release Zone 1 Name: Descriptive name for release zone 1 of module 3.";
CM_ SG_ 2633721342 VFSSModule3ReleaseZone2Name "VFSS Module 3 Release Zone 2 Name: Descriptive name for release zone 2 of module 3.";
CM_ BO_ 2633721598 "Vehicle Fire Suppression System Module 4 Names";
CM_ SG_ 2633721598 VFSSModule4Name "VFSS Module 4 Name: Descriptive name for the VFSS module/zone 4.";
CM_ SG_ 2633721598 VFSSModule4DetectorZone1Name "VFSS Module 4 Detector Zone 1 Name: Descriptive name for detector zone 1 of module 4.";
CM_ SG_ 2633721598 VFSSModule4DetectorZone2Name "VFSS Module 4 Detector Zone 2 Name: Descriptive name for detector zone 2 of module 4.";
CM_ SG_ 2633721598 VFSSModule4DetectorZone3Name "VFSS Module 4 Detector Zone 3 Name: Descriptive name for detector zone 3 of module 4.";
CM_ SG_ 2633721598 VFSSModule4DetectorZone4Name "VFSS Module 4 Detector Zone 4 Name: Descriptive name for detector zone 4 of module 4.";
CM_ SG_ 2633721598 VFSSModule4DetectorZone5Name "VFSS Module 4 Detector Zone 5 Name: Descriptive name for detector zone 5 of module 4.";
CM_ SG_ 2633721598 VFSSModule4DetectorZone6Name "VFSS Module 4 Detector Zone 6 Name: Descriptive name for detector zone 6 of module 4.";
CM_ SG_ 2633721598 VFSSModule4DetectorZone7Name "VFSS Module 4 Detector Zone 7 Name: Descriptive name for detector zone 7 of module 4.";
CM_ SG_ 2633721598 VFSSModule4DetectorZone8Name "VFSS Module 4 Detector Zone 8 Name: Descriptive name for detector zone 8 of module 4.";
CM_ SG_ 2633721598 VFSSModule4HeatZone1Name "VFSS Module 4 Heat Zone 1 Name: Descriptive name for heat zone 1 of module 4.";
CM_ SG_ 2633721598 VFSSModule4HeatZone2Name "VFSS Module 4 Heat Zone 2 Name: Descriptive name for heat zone 2 of module 4.";
CM_ SG_ 2633721598 VFSSModule4ReleaseZone1Name "VFSS Module 4 Release Zone 1 Name: Descriptive name for release zone 1 of module 4.";
CM_ SG_ 2633721598 VFSSModule4ReleaseZone2Name "VFSS Module 4 Release Zone 2 Name: Descriptive name for release zone 2 of module 4.";
CM_ BO_ 2566612990 "Motor/Generator 2 Inverter Active Power Limits";
CM_ SG_ 2566612990 MtGt2IvtPwLtddtUddRs "Motor/Generator 2 Inverter Power Limited due to Undefined Reason: Output power is being limited due to an undefined reason.00b = No power limit for this reason01b = Power limited for this reason10b = Error11b = Not Available";
CM_ SG_ 2566612990 MtGt2IvtPwLtddtDCSdCtMx "Motor/Generator 2 Inverter Power Limited due to DC Side Current Maximum: Output power is being limited due to SPN 10241 [Inverter DC Side Current] approaching or exceeding the SPN 10280 [Inverter Limits Active DC Side Current Maximum].00b = No power ...";
CM_ SG_ 2566612990 MtGt2IvtPwLtddtDCSdCtM "Motor/Generator 2 Inverter Power Limited due to DC Side Current Minimum: Output power is being limited due to SPN 10241 [Inverter DC Side Current] approaching or falling below the SPN 10281 [Inverter Limits Active DC Side Current Minimum].00b = No po...";
CM_ SG_ 2566612990 MtGt2IvtPwLtddtDCSdVtMx "Motor/Generator 2 Inverter Power Limited due to DC Side Voltage Maximum: Output power is being limited due to SPN 9102 [Inverter DC Side Voltage] approaching or exceeding the SPN 10278 [Inverter Limits Active DC Side Voltage Maximum].00b = No power l...";
CM_ SG_ 2566612990 MtGt2IvtPwLtddtDCSdVtM "Motor/Generator 2 Inverter Power Limited due to DC Side Voltage Minimum: Output power is being limited due to SPN 9102 [Inverter DC Side Voltage] approaching or falling below the SPN 10279 [Inverter Limits Active DC Side Voltage Minimum].00b = No pow...";
CM_ SG_ 2566612990 MtGt2IvtPwLtddtMPwMx "Motor/Generator 2 Inverter Power Limited due to Mechanical Power Maximum: Output power is being limited due to Mechanical Power (product of SPN 9062 [Torque] and SPN 9058 [Speed]) approaching or exceeding the SPN 10250 [Inverter Limits Active Mechani...";
CM_ SG_ 2566612990 MtGt2IvtPwLtddtMPwM "Motor/Generator 2 Inverter Power Limited due to Mechanical Power Minimum: Output power is being limited due to Mechanical Power (product of SPN 9062 [Torque] and SPN 9058 [Speed]) approaching or falling below the SPN 10251 [Inverter Limits Active Mec...";
CM_ SG_ 2566612990 MtGt2IvtPwLtddtDCSdPwMx "Motor/Generator 2 Inverter Power Limited due to DC Side Power Maximum: Output power is being limited due to DC Side Power (product of SPN 10241 [Inverter DC Side Current] and SPN 9102 [Inverter DC Side Voltage]) approaching or exceeding the SPN 10252...";
CM_ SG_ 2566612990 MtGt2IvtPwLtddtDCSdPwM "Motor/Generator 2 Inverter Power Limited due to DC Side Power Minimum: Output power is being limited due to DC Side Power (product of SPN 10241 [Inverter DC Side Current] and SPN 9102 [Inverter DC Side Voltage]) approaching or falling below the SPN 1...";
CM_ SG_ 2566612990 MtrGnrtr2InvrtrPwrLmtddtTrqMxmm "Motor/Generator 2 Inverter Power Limited due to Torque Maximum: Output power is being limited due to SPN 9062 [Torque] approaching or exceeding the SPN 10262 [Inverter Limits Active Torque Maximum].00b = No power limit for this reason01b = Power limi...";
CM_ SG_ 2566612990 MtrGnrtr2InvrtrPwrLmtddtTrqMnmm "Motor/Generator 2 Inverter Power Limited due to Torque Minimum: Output power is being limited due to SPN 9062 [Torque] approaching or falling below the SPN 10263 [Inverter Limits Active Torque Minimum].00b = No power limit for this reason01b = Power ...";
CM_ SG_ 2566612990 MtrGnrtr2InvrtrPwrLmtddtSpdMxmm "Motor/Generator 2 Inverter Power Limited due to Speed Maximum: Output power is being limited due to SPN 9058 [Speed] approaching or exceeding the SPN 10264 [Inverter Limits Active Speed Maximum].00b = No power limit for this reason01b = Power limited...";
CM_ SG_ 2566612990 MtrGnrtr2InvrtrPwrLmtddtSpdMnmm "Motor/Generator 2 Inverter Power Limited due to Speed Minimum: Output power is being limited due to SPN 9058 [Speed] approaching or falling below the SPN 10265 [Inverter Limits Active Speed Minimum].00b = No power limit for this reason01b = Power lim...";
CM_ SG_ 2566612990 MtGt2IvtPwLtddtIvtTpt "Motor/Generator 2 Inverter Power Limited due to Inverter Temperature: Output power is being limited due to one or more inverter temperature(s), see SPNs 10282 through 10285 [Inverter Temperature 1-4] approaching or exceeding internally defined limit(...";
CM_ SG_ 2566612990 MtGt2IvtPwLtddtMtTpt "Motor/Generator 2 Inverter Power Limited due to Motor Temperature: Output power is being limited due to one or more motor temperature(s), see SPNs 9060 and 10286 through 10288 [Motor Temperature 1-4] approaching or exceeding internally defined limit(...";
CM_ SG_ 2566612990 MtGt2IvtPwLtdDtFtCdt "Motor/Generator 2 Inverter Power Limited Due to Fault Condition: Output power is being limited due to an fault condition that requires a torque limitation to prevent further damage (e.g. “limp home mode”).  For example, this could be in case of tempe...";
CM_ SG_ 2566612990 MtGt2IvtPwLtdDtAtvTqRtLt "Motor/Generator 2 Inverter Power Limited Due to Active Torque Rate Limit: Output power is being limited due to exceeding internally defined torque rate limit(s) or SPN 10835 [Inverter Rate Limits Request Absolute Torque Rate Limit].00b = No power lim...";
CM_ SG_ 2566612990 MtGt2IvtPwLtdDtAtvSpdRtLt "Motor/Generator 2 Inverter Power Limited Due to Active Speed Rate Limit: Output power is being limited due to exceeding internally defined speed rate limit(s) or SPN 10834 [Inverter Rate Limits Request Absolute Speed Rate Limit].00b = No power limit ...";
CM_ SG_ 2566612990 MtGt2IvtTqLtdDtMCtsts "Motor/Generator 2 Inverter Torque Limited Due to Machine Characteristics: Output torque is being limited due to SPN 9062 [Torque] approaching or exceeding a motor design characteristic.  For example, for permanent magnet machines, this would be in th...";
CM_ BO_ 2566613246 "Motor/Generator 2 Inverter Isolation Integrity";
CM_ SG_ 2566613246 MtrGnrtr2InvrtrIsltnIntgrtCRC "Motor/Generator 2 Inverter Isolation Integrity CRC: The CRC is defined as follows:• Length: 8 bits• Polynomial: x^8+x^5+x^3+x^2+x+1• Initial Value: FFh• Input Data Reflection: Not reflected• Result Data Reflection: Not reflected• XOR value: FFhSAE ma...";
CM_ SG_ 2566613246 MtrGnrtr2InvrtrIsltnIntgrtCntr "Motor/Generator 2 Inverter Isolation Integrity Counter: The message counter is used to detect situations where the transmitting ECU malfunction repeats the same frame all the time. The receiver of the information may use the counter parameter to dete...";
CM_ SG_ 2566613246 MtGt2IvtDCSdNtvtCsssGdVt "Motor/Generator 2 Inverter DC Side Negative to Chassis Ground Voltage: The voltage level of the high voltage DC side, as measured by the inverter between the negative side of the High Voltage DC Side input and the chassis of the inverter enclosure.  ...";
CM_ SG_ 2566613246 MtGt2IvtHVtBsAtvIstTstStts "Motor/Generator 2 Inverter High-Voltage Bus Active Isolation Test Status: Status of the high-voltage bus electrical active isolation test as performed by this instance of the motor/generator.0000b = No test requested / No test in process0001b = Test ...";
CM_ SG_ 2566613246 MtGt2IvtHVtBsPssvIstTstStts "Motor/Generator 2 Inverter High-Voltage Bus Passive Isolation Test Status: Status of the high-voltage bus electrical passive isolation test as performed by this instance of the Motor/Generator.0000b = No test requested / No test in process0001b = Tes...";
CM_ SG_ 2566613246 MtGt2IvtHVtBsAtvIstTstRsts "Motor/Generator 2 Inverter High-Voltage Bus Active Isolation Test Results: The isolation resistance that resulted from the High-Voltage Bus Active Isolation Test.See SPN 10813 [High-Voltage Bus Active Isolation Test Status] for test status and SPN 10...";
CM_ SG_ 2566613246 MtGt2IvtHVtBsPssvIstTstRsts "Motor/Generator 2 Inverter High-Voltage Bus Passive Isolation Test Results: The isolation resistance that resulted from the High-Voltage Bus Passive Isolation Test.See SPN 10814 [High-Voltage Bus Passive Isolation Test Status] for test status and SPN...";
CM_ BO_ 2566613502 "Motor/Generator 1 Inverter Active Power Limits";
CM_ SG_ 2566613502 MtGt1IvtPwLtddtUddRs "Motor/Generator 1 Inverter Power Limited due to Undefined Reason: Output power is being limited due to an undefined reason.00b = No power limit for this reason01b = Power limited for this reason10b = Error11b = Not Available";
CM_ SG_ 2566613502 MtGt1IvtPwLtddtDCSdCtMx "Motor/Generator 1 Inverter Power Limited due to DC Side Current Maximum: Output power is being limited due to SPN 10175 [Inverter DC Side Current] approaching or exceeding the SPN 10214 [Inverter Limits Active DC Side Current Maximum].00b = No power ...";
CM_ SG_ 2566613502 MtGt1IvtPwLtddtDCSdCtM "Motor/Generator 1 Inverter Power Limited due to DC Side Current Minimum: Output power is being limited due to SPN 10175 [Inverter DC Side Current] approaching or falling below the SPN 10215 [Inverter Limits Active DC Side Current Minimum].00b = No po...";
CM_ SG_ 2566613502 MtGt1IvtPwLtddtDCSdVtMx "Motor/Generator 1 Inverter Power Limited due to DC Side Voltage Maximum: Output power is being limited due to SPN 9101 [Inverter DC Side Voltage] approaching or exceeding the SPN 10212 [Inverter Limits Active DC Side Voltage Maximum].00b = No power l...";
CM_ SG_ 2566613502 MtGt1IvtPwLtddtDCSdVtM "Motor/Generator 1 Inverter Power Limited due to DC Side Voltage Minimum: Output power is being limited due to SPN 9101 [Inverter DC Side Voltage] approaching or falling below the SPN 10213 [Inverter Limits Active DC Side Voltage Minimum].00b = No pow...";
CM_ SG_ 2566613502 MtGt1IvtPwLtddtMPwMx "Motor/Generator 1 Inverter Power Limited due to Mechanical Power Maximum: Output power is being limited due to Mechanical Power (product of SPN 9061 [Torque] and SPN 9057 [Speed]) approaching or exceeding the SPN 10184 [Inverter Limits Active Mechani...";
CM_ SG_ 2566613502 MtGt1IvtPwLtddtMPwM "Motor/Generator 1 Inverter Power Limited due to Mechanical Power Minimum: Output power is being limited due to Mechanical Power (product of SPN 9061 [Torque] and SPN 9057 [Speed]) approaching or falling below the SPN 10185 [Inverter Limits Active Mec...";
CM_ SG_ 2566613502 MtGt1IvtPwLtddtDCSdPwMx "Motor/Generator 1 Inverter Power Limited due to DC Side Power Maximum: Output power is being limited due to DC Side Power (product of SPN 10175 [Inverter DC Side Current] and SPN 9101 [Inverter DC Side Voltage]) approaching or exceeding the SPN 10186...";
CM_ SG_ 2566613502 MtGt1IvtPwLtddtDCSdPwM "Motor/Generator 1 Inverter Power Limited due to DC Side Power Minimum: Output power is being limited due to DC Side Power (product of SPN 10175 [Inverter DC Side Current] and SPN 9101 [Inverter DC Side Voltage]) approaching or falling below the SPN 1...";
CM_ SG_ 2566613502 MtrGnrtr1InvrtrPwrLmtddtTrqMxmm "Motor/Generator 1 Inverter Power Limited due to Torque Maximum: Output power is being limited due to SPN 9061 [Torque] approaching or exceeding the SPN 10196 [Inverter Limits Active Torque Maximum].00b = No power limit for this reason01b = Power limi...";
CM_ SG_ 2566613502 MtrGnrtr1InvrtrPwrLmtddtTrqMnmm "Motor/Generator 1 Inverter Power Limited due to Torque Minimum: Output power is being limited due to SPN 9061 [Torque] approaching or falling below the SPN 10197 [Inverter Limits Active Torque Minimum].00b = No power limit for this reason01b = Power ...";
CM_ SG_ 2566613502 MtrGnrtr1InvrtrPwrLmtddtSpdMxmm "Motor/Generator 1 Inverter Power Limited due to Speed Maximum: Output power is being limited due to SPN 9057 [Speed] approaching or exceeding the SPN 10198 [Inverter Limits Active Speed Maximum].00b = No power limit for this reason01b = Power limited...";
CM_ SG_ 2566613502 MtrGnrtr1InvrtrPwrLmtddtSpdMnmm "Motor/Generator 1 Inverter Power Limited due to Speed Minimum: Output power is being limited due to SPN 9057 [Speed] approaching or falling below the SPN 10199 [Inverter Limits Active Speed Minimum].00b = No power limit for this reason01b = Power lim...";
CM_ SG_ 2566613502 MtGt1IvtPwLtddtIvtTpt "Motor/Generator 1 Inverter Power Limited due to Inverter Temperature: Output power is being limited due to one or more inverter temperature(s), see SPNs 10216 through 10219 [Inverter Temperature 1-4] approaching or exceeding internally defined limit(...";
CM_ SG_ 2566613502 MtGt1IvtPwLtddtMtTpt "Motor/Generator 1 Inverter Power Limited due to Motor Temperature: Output power is being limited due to one or more motor temperature(s), see SPNs 9059 and 10220 through 10222 [Motor Temperature 1-4] approaching or exceeding internally defined limit(...";
CM_ SG_ 2566613502 MtGt1IvtPwLtdDtFtCdt "Motor/Generator 1 Inverter Power Limited Due to Fault Condition: Output power is being limited due to an fault condition that requires a torque limitation to prevent further damage (e.g. “limp home mode”).  For example, this could be in case of tempe...";
CM_ SG_ 2566613502 MtGt1IvtPwLtdDtAtvTqRtLt "Motor/Generator 1 Inverter Power Limited Due to Active Torque Rate Limit: Output power is being limited due to exceeding internally defined torque rate limit(s) or SPN 10797 [Inverter Rate Limits Request Absolute Torque Rate Limit]. 00b = No power li...";
CM_ SG_ 2566613502 MtGt1IvtPwLtdDtAtvSpdRtLt "Motor/Generator 1 Inverter Power Limited Due to Active Speed Rate Limit: Output power is being limited due to exceeding internally defined speed rate limit(s) or SPN 10796 [Inverter Rate Limits Request Absolute Speed Rate Limit].00b = No power limit ...";
CM_ SG_ 2566613502 MtGt1IvtTqLtdDtMCtsts "Motor/Generator 1 Inverter Torque Limited Due to Machine Characteristics: Output torque is being limited due to SPN 9061 [Torque] approaching or exceeding a motor design characteristic.  For example, for permanent magnet machines, this would be in th...";
CM_ BO_ 2566613758 "Motor/Generator 1 Inverter Isolation Integrity";
CM_ SG_ 2566613758 MtrGnrtr1InvrtrIsltnIntgrtCRC "Motor/Generator 1 Inverter Isolation Integrity CRC: The CRC is defined as follows:• Length: 8 bits• Polynomial: x^8+x^5+x^3+x^2+x+1• Initial Value: FFh• Input Data Reflection: Not reflected• Result Data Reflection: Not reflected• XOR value: FFhSAE ma...";
CM_ SG_ 2566613758 MtrGnrtr1InvrtrIsltnIntgrtCntr "Motor/Generator 1 Inverter Isolation Integrity Counter: The message counter is used to detect situations where the transmitting ECU malfunction repeats the same frame all the time. The receiver of the information may use the counter parameter to dete...";
CM_ SG_ 2566613758 MtGt1IvtDCSdNtvtCsssGdVt "Motor/Generator 1 Inverter DC Side Negative to Chassis Ground Voltage: The voltage level of the high voltage DC side, as measured by the inverter between the negative side of the High Voltage DC Side input and the chassis of the inverter enclosure.  ...";
CM_ SG_ 2566613758 MtGt1IvtHVtBsAtvIstTstStts "Motor/Generator 1 Inverter High-Voltage Bus Active Isolation Test Status: Status of the high-voltage bus electrical active isolation test as performed by this instance of the Motor/Generator.0000b = No test requested / No test in process0001b = Test ...";
CM_ SG_ 2566613758 MtGt1IvtHVtBsPssvIstTstStts "Motor/Generator 1 Inverter High-Voltage Bus Passive Isolation Test Status: Status of the high-voltage bus electrical passive isolation test as performed by this instance of the Motor/Generator.0000b = No test requested / No test in process0001b = Tes...";
CM_ SG_ 2566613758 MtGt1IvtHVtBsAtvIstTstRsts "Motor/Generator 1 Inverter High-Voltage Bus Active Isolation Test Results: The isolation resistance that resulted from the High-Voltage Bus Active Isolation Test.See SPN 10775 [High-Voltage Bus Active Isolation Test Status] for test status and SPN 10...";
CM_ SG_ 2566613758 MtGt1IvtHVtBsPssvIstTstRsts "Motor/Generator 1 Inverter High-Voltage Bus Passive Isolation Test Results: The isolation resistance that resulted from the High-Voltage Bus Passive Isolation Test.See SPN 10776 [High-Voltage Bus Passive Isolation Test Status] for test status and SPN...";
CM_ BO_ 2566614014 "High Voltage Bus Information";
CM_ SG_ 2566614014 HighVoltageDCBusAvailability "High Voltage DC Bus Availability: This parameter indicates the availability of the high voltage bus to power components.  Power sources may include, but are not limited to batteries, fuel cells, generators, etc.  Note:  For batteries, SPN 8413 exists...";
CM_ BO_ 2352021246 "High Voltage Energy Storage Pack 7 Control 1";
CM_ SG_ 2352021246 HVESP7HghVltgBsCnntCmmnd "HVESP7 High-Voltage Bus Connect Command: Command to connect this High Voltage Energy Storage Pack instance to the high-voltage bus.  The emergency contactor closure request may be used in situations where one or more faults in the hybrid powertrain p...";
CM_ SG_ 2352021246 HVESP7PowerDownCommand "HVESP7 Power-Down Command: Command to shut down this High Voltage Energy Storage Pack instance.  A normal power-down may involve steps that take some period of time (tests, writing of data, etc.).  However, an emergency power-down should shut down th...";
CM_ SG_ 2352021246 HVESP7HghVltgBsAtvIsltnTstCmmnd "HVESP7 High-Voltage Bus Active Isolation Test Command: Command for this High Voltage Energy Storage Pack instance to perform an active electrical isolation test on the high voltage bus.An active isolation test might use a generated signal (e.g. an in...";
CM_ SG_ 2352021246 HVESP7HVtBsPssvIstTstCd "HVESP7 High-Voltage Bus Passive Isolation Test Command: Command for this High Voltage Energy Storage Pack instance to perform a passive electrical isolation test on the high voltage bus.A passive isolation test uses additional circuitry (e.g. a high ...";
CM_ SG_ 2352021246 HVESP7CellBalancingCommand "HVESP7 Cell Balancing Command: Command for this High Voltage Energy Storage Pack instance to perform cell balancing.This parameter is for one of multiple packs in an HVESS.  If there is only one pack in the system, the HVESS parameters should be used...";
CM_ SG_ 2352021246 HVESP7EnlIntrnlChrgrCmmnd "HVESP7 Enable Internal Charger Command: When the HVES has an internal charger this parameter will enable it.   External chargers may use the External Energy Source Connection Demand (SPN 7890) and related SPs.This parameter is for one of multiple pac...";
CM_ SG_ 2352021246 HVESP7OperationConsent "HVESP7 Operation Consent: This parameter provides an indication to this High Voltage Energy Storage Pack instance that an external device is ready for this HVES instance to proceed with normal operation.  In applications which support this parameter,...";
CM_ SG_ 2352021246 HVESP7HVtBsHSdRsstCtRqst "HVESP7 High-Voltage Bus High Side Resistor Connect Request: This parameter is used to request connection of this HVES instance High-Voltage bus high side resistor in order to perform an isolation test. See also SPN 14045 (HVESP7 High-Voltage Bus Low ...";
CM_ SG_ 2352021246 HVESP7HVtBsLwSdRsstCtRqst "HVESP7 High-Voltage Bus Low Side Resistor Connect Request: This parameter is used to request connection of this HVES instance High-Voltage bus low side resistor in order to perform an isolation test. See also SPN 14044 (HVESP7 High-Voltage Bus High S...";
CM_ SG_ 2352021246 HVESP7Control1Counter "HVESP7 Control 1 Counter: The message counter is used to detect situations where the transmitting ECU malfunction repeats the same frame all the time. The receiver of the information may use the counter parameter to detect this situation. The transmi...";
CM_ SG_ 2352021246 HVESP7Control1CRC "HVESP7 Control 1 CRC: The CRC is defined as follows: • Length: 8 bits • Polynomial: x^8+x^5+x^3+x^2+x+1 • Initial Value: FFh • Input Data Reflection: Not reflected • Result Data Reflection: Not reflected • XOR value: FFhSAE makes no claim of the func...";
CM_ BO_ 2352086782 "High Voltage Energy Storage Pack 8 Control 1";
CM_ SG_ 2352086782 HVESP8HghVltgBsCnntCmmnd "HVESP8 High-Voltage Bus Connect Command: Command to connect this High Voltage Energy Storage Pack instance to the high-voltage bus.  The emergency contactor closure request may be used in situations where one or more faults in the hybrid powertrain p...";
CM_ SG_ 2352086782 HVESP8PowerDownCommand "HVESP8 Power-Down Command: Command to shut down this High Voltage Energy Storage Pack instance.  A normal power-down may involve steps that take some period of time (tests, writing of data, etc.).  However, an emergency power-down should shut down th...";
CM_ SG_ 2352086782 HVESP8HghVltgBsAtvIsltnTstCmmnd "HVESP8 High-Voltage Bus Active Isolation Test Command: Command for this High Voltage Energy Storage Pack instance to perform an active electrical isolation test on the high voltage bus.An active isolation test might use a generated signal (e.g. an in...";
CM_ SG_ 2352086782 HVESP8HVtBsPssvIstTstCd "HVESP8 High-Voltage Bus Passive Isolation Test Command: Command for this High Voltage Energy Storage Pack instance to perform a passive electrical isolation test on the high voltage bus.A passive isolation test uses additional circuitry (e.g. a high ...";
CM_ SG_ 2352086782 HVESP8CellBalancingCommand "HVESP8 Cell Balancing Command: Command for this High Voltage Energy Storage Pack instance to perform cell balancing.This parameter is for one of multiple packs in an HVESS.  If there is only one pack in the system, the HVESS parameters should be used...";
CM_ SG_ 2352086782 HVESP8EnlIntrnlChrgrCmmnd "HVESP8 Enable Internal Charger Command: When the HVES has an internal charger this parameter will enable it.   External chargers may use the External Energy Source Connection Demand (SPN 7890) and related SPs.This parameter is for one of multiple pac...";
CM_ SG_ 2352086782 HVESP8OperationConsent "HVESP8 Operation Consent: This parameter provides an indication to this High Voltage Energy Storage Pack instance that an external device is ready for this HVES instance to proceed with normal operation.  In applications which support this parameter,...";
CM_ SG_ 2352086782 HVESP8HVtBsHSdRsstCtRqst "HVESP8 High-Voltage Bus High Side Resistor Connect Request: This parameter is used to request connection of this HVES instance High-Voltage bus high side resistor in order to perform an isolation test. See also SPN 14188 (HVESP8 High-Voltage Bus Low ...";
CM_ SG_ 2352086782 HVESP8HVtBsLwSdRsstCtRqst "HVESP8 High-Voltage Bus Low Side Resistor Connect Request: This parameter is used to request connection of this HVES instance High-Voltage bus low side resistor in order to perform an isolation test. See also SPN 14187 (HVESP8 High-Voltage Bus High S...";
CM_ SG_ 2352086782 HVESP8Control1Counter "HVESP8 Control 1 Counter: The message counter is used to detect situations where the transmitting ECU malfunction repeats the same frame all the time. The receiver of the information may use the counter parameter to detect this situation. The transmi...";
CM_ SG_ 2352086782 HVESP8Control1CRC "HVESP8 Control 1 CRC: The CRC is defined as follows: • Length: 8 bits • Polynomial: x^8+x^5+x^3+x^2+x+1 • Initial Value: FFh • Input Data Reflection: Not reflected • Result Data Reflection: Not reflected • XOR value: FFhSAE makes no claim of the func...";
CM_ BO_ 2352152318 "High Voltage Energy Storage Pack 9 Control 1";
CM_ SG_ 2352152318 HVESP9HghVltgBsCnntCmmnd "HVESP9 High-Voltage Bus Connect Command: Command to connect this High Voltage Energy Storage Pack instance to the high-voltage bus.  The emergency contactor closure request may be used in situations where one or more faults in the hybrid powertrain p...";
CM_ SG_ 2352152318 HVESP9PowerDownCommand "HVESP9 Power-Down Command: Command to shut down this High Voltage Energy Storage Pack instance.  A normal power-down may involve steps that take some period of time (tests, writing of data, etc.).  However, an emergency power-down should shut down th...";
CM_ SG_ 2352152318 HVESP9HghVltgBsAtvIsltnTstCmmnd "HVESP9 High-Voltage Bus Active Isolation Test Command: Command for this High Voltage Energy Storage Pack instance to perform an active electrical isolation test on the high voltage bus.An active isolation test might use a generated signal (e.g. an in...";
CM_ SG_ 2352152318 HVESP9HVtBsPssvIstTstCd "HVESP9 High-Voltage Bus Passive Isolation Test Command: Command for this High Voltage Energy Storage Pack instance to perform a passive electrical isolation test on the high voltage bus.A passive isolation test uses additional circuitry (e.g. a high ...";
CM_ SG_ 2352152318 HVESP9CellBalancingCommand "HVESP9 Cell Balancing Command: Command for this High Voltage Energy Storage Pack instance to perform cell balancing.This parameter is for one of multiple packs in an HVESS.  If there is only one pack in the system, the HVESS parameters should be used...";
CM_ SG_ 2352152318 HVESP9EnlIntrnlChrgrCmmnd "HVESP9 Enable Internal Charger Command: When the HVES has an internal charger this parameter will enable it.   External chargers may use the External Energy Source Connection Demand (SPN 7890) and related SPs.This parameter is for one of multiple pac...";
CM_ SG_ 2352152318 HVESP9OperationConsent "HVESP9 Operation Consent: This parameter provides an indication to this High Voltage Energy Storage Pack instance that an external device is ready for this HVES instance to proceed with normal operation.  In applications which support this parameter,...";
CM_ SG_ 2352152318 HVESP9HVtBsHSdRsstCtRqst "HVESP9 High-Voltage Bus High Side Resistor Connect Request: This parameter is used to request connection of this HVES instance High-Voltage bus high side resistor in order to perform an isolation test. See also SPN 14331 (HVESP9 High-Voltage Bus Low ...";
CM_ SG_ 2352152318 HVESP9HVtBsLwSdRsstCtRqst "HVESP9 High-Voltage Bus Low Side Resistor Connect Request: This parameter is used to request connection of this HVES instance High-Voltage bus low side resistor in order to perform an isolation test. See also SPN 14330 (HVESP9 High-Voltage Bus High S...";
CM_ SG_ 2352152318 HVESP9Control1Counter "HVESP9 Control 1 Counter: The message counter is used to detect situations where the transmitting ECU malfunction repeats the same frame all the time. The receiver of the information may use the counter parameter to detect this situation. The transmi...";
CM_ SG_ 2352152318 HVESP9Control1CRC "HVESP9 Control 1 CRC: The CRC is defined as follows: • Length: 8 bits • Polynomial: x^8+x^5+x^3+x^2+x+1 • Initial Value: FFh • Input Data Reflection: Not reflected • Result Data Reflection: Not reflected • XOR value: FFhSAE makes no claim of the func...";
CM_ BO_ 2352217854 "High Voltage Energy Storage Pack 10 Control 1";
CM_ SG_ 2352217854 HVESP10HghVltgBsCnntCmmnd "HVESP10 High-Voltage Bus Connect Command: Command to connect this High Voltage Energy Storage Pack instance to the high-voltage bus.  The emergency contactor closure request may be used in situations where one or more faults in the hybrid powertrain ...";
CM_ SG_ 2352217854 HVESP10PowerDownCommand "HVESP10 Power-Down Command: Command to shut down this High Voltage Energy Storage Pack instance.  A normal power-down may involve steps that take some period of time (tests, writing of data, etc.).  However, an emergency power-down should shut down t...";
CM_ SG_ 2352217854 HVESP10HVtBsAtvIstTstCd "HVESP10 High-Voltage Bus Active Isolation Test Command: Command for this High Voltage Energy Storage Pack instance to perform an active electrical isolation test on the high voltage bus.An active isolation test might use a generated signal (e.g. an i...";
CM_ SG_ 2352217854 HVESP10HVtBsPssvIstTstCd "HVESP10 High-Voltage Bus Passive Isolation Test Command: Command for this High Voltage Energy Storage Pack instance to perform a passive electrical isolation test on the high voltage bus.A passive isolation test uses additional circuitry (e.g. a high...";
CM_ SG_ 2352217854 HVESP10CellBalancingCommand "HVESP10 Cell Balancing Command: Command for this High Voltage Energy Storage Pack instance to perform cell balancing.This parameter is for one of multiple packs in an HVESS.  If there is only one pack in the system, the HVESS parameters should be use...";
CM_ SG_ 2352217854 HVESP10EnlIntrnlChrgrCmmnd "HVESP10 Enable Internal Charger Command: When the HVES has an internal charger this parameter will enable it.   External chargers may use the External Energy Source Connection Demand (SPN 7890) and related SPs.This parameter is for one of multiple pa...";
CM_ SG_ 2352217854 HVESP10OperationConsent "HVESP10 Operation Consent: This parameter provides an indication to this High Voltage Energy Storage Pack instance that an external device is ready for this HVES instance to proceed with normal operation.  In applications which support this parameter...";
CM_ SG_ 2352217854 HVESP10HVtBsHSdRsstCtRqst "HVESP10 High-Voltage Bus High Side Resistor Connect Request: This parameter is used to request connection of this HVES instance High-Voltage bus high side resistor in order to perform an isolation test. See also SPN 14474 (HVESP10 High-Voltage Bus Lo...";
CM_ SG_ 2352217854 HVESP10HVtBsLwSdRsstCtRqst "HVESP10 High-Voltage Bus Low Side Resistor Connect Request: This parameter is used to request connection of this HVES instance High-Voltage bus low side resistor in order to perform an isolation test. See also SPN 14473 (HVESP10 High-Voltage Bus High...";
CM_ SG_ 2352217854 HVESP10Control1Counter "HVESP10 Control 1 Counter: The message counter is used to detect situations where the transmitting ECU malfunction repeats the same frame all the time. The receiver of the information may use the counter parameter to detect this situation. The transm...";
CM_ SG_ 2352217854 HVESP10Control1CRC "HVESP10 Control 1 CRC: The CRC is defined as follows: • Length: 8 bits • Polynomial: x^8+x^5+x^3+x^2+x+1 • Initial Value: FFh • Input Data Reflection: Not reflected • Result Data Reflection: Not reflected • XOR value: FFhSAE makes no claim of the fun...";
CM_ BO_ 2555379454 "Data Transfer Support";
CM_ SG_ 2555379454 DataTransferManufacturerID "Data Transfer Manufacturer ID: The 11-bit Manufacturer ID as defined in the J1939DA. An intermediary (e.g. telematics device) can use this to associate the Data Transfer Support requirements with the Data Transfer messages from the same manufacturer.";
CM_ SG_ 2555379454 TotalWeeklyMessageInstances "Total Weekly Message Instances: The total count of weekly message instances that will be broadcast by the transmitter. An intermediary (e.g. telematics device) can use this parameter to determine how many message instances it will receive after a Dat...";
CM_ SG_ 2555379454 LongestWeeklyMessageInstance "Longest Weekly Message Instance: The number of bytes in the longest Weekly Data Transfer message instance broadcast by the transmitter. An intermediary (e.g. telematics device) can use this to estimate the buffer sizes necessary to handle data acquir...";
CM_ SG_ 2555379454 TotalMonthlyMessageInstances "Total Monthly Message Instances: The total count of monthly message instances that will be broadcast by the transmitter. An intermediary (e.g. telematics device) can use this parameter to determine how many message instances it will receive after a D...";
CM_ SG_ 2555379454 LongestMonthlyMessageInstance "Longest Monthly Message Instance: The number of bytes in the longest Monthly Data Transfer message instance broadcast by the transmitter. An intermediary (e.g. telematics device) can use this to estimate the buffer sizes necessary to handle data acqu...";
CM_ SG_ 2555379454 TotalDailyMessageInstances "Total Daily Message Instances: The total count of daily message instances that will be broadcast by the transmitter. An intermediary (e.g. telematics device) can use this parameter to determine how many message instances it will receive after a Data ...";
CM_ SG_ 2555379454 LongestDailyMessageInstance "Longest Daily Message Instance: The number of bytes in the longest Daily Data Transfer message instance broadcast by the transmitter. An intermediary (e.g. telematics device) can use this to estimate the buffer sizes necessary to handle data acquired...";
CM_ SG_ 2555379454 TotalDailyMessageBytes "Total Daily Message Bytes: The total number of bytes in all Daily Data Transfer message instances that will be broadcast by the transmitter.  An intermediary (e.g. telematics device) can use this to estimate the amount of memory necessary to handle d...";
CM_ SG_ 2555379454 TotalWeeklyMessageBytes "Total Weekly Message Bytes: The total number of bytes in all Weekly Data Transfer message instances that will be broadcast by the transmitter. An intermediary (e.g. telematics device) can use this to estimate the amount of memory necessary to handle ...";
CM_ SG_ 2555379454 TotalMonthlyMessageBytes "Total Monthly Message Bytes: The total number of bytes in all Monthly Data Transfer message instances that will be broadcast by the transmitter. An intermediary (e.g. telematics device) can use this to estimate the amount of memory necessary to handl...";
CM_ BO_ 2555444990 "Monthly Data Transfer";
CM_ SG_ 2555444990 MonthlyMessageInstance "Monthly Message Instance: A transmitter sets this number to indicate the Monthly Data Transfer message instance currently being sent in a broadcast series. It allows an intermediary device to determine what message instance is being sent or was last ...";
CM_ SG_ 2555444990 MnthlMssgInstnsRmnng "Monthly Message Instances Remaining: This number indicates the message instances yet to be broadcast in a transmitter’s Monthly Data Transfer broadcast series. When used together with SPN 12983 [Monthly Message Instance], an intermediary device can d...";
CM_ SG_ 2555444990 MonthlyDataManufacturerID "Monthly Data Manufacturer ID: This 11-bit Manufacturer ID (defined in the J1939DA) identifies the transmitter manufacturer whose cloud or data repository is the final destination for the associated data.";
CM_ BO_ 2555510526 "Weekly Data Transfer";
CM_ SG_ 2555510526 WeeklyMessageInstance "Weekly Message Instance: A transmitter sets this number to indicate the Weekly Data Transfer message instance currently being sent in a broadcast series. It allows an intermediary device to determine what message instance is being sent or was last re...";
CM_ SG_ 2555510526 WeeklyMessageInstancesRemaining "Weekly Message Instances Remaining: This number indicates the message instances yet to be broadcast in a transmitter’s Weekly Transfer broadcast series. When used together with SPN 12978 [Weekly Message Instance], an intermediary device can determine...";
CM_ SG_ 2555510526 WeeklyDataManufacturerID "Weekly Data Manufacturer ID: This 11-bit Manufacturer ID (defined in the J1939DA) identifies the transmitter manufacturer whose cloud or data repository is the final destination for the associated data.";
CM_ BO_ 2555576062 "Daily Data Transfer";
CM_ SG_ 2555576062 DailyMessageInstance "Daily Message Instance: A transmitter sets this number to indicate the Daily Data Transfer message instance currently being sent in a broadcast series. It allows an intermediary device to determine what message instance is being sent or was last rece...";
CM_ SG_ 2555576062 DailyMessageInstancesRemaining "Daily Message Instances Remaining: This number indicates the message instances yet to be broadcast in a transmitter’s Daily Data Transfer broadcast series. When used together with SPN 12973 [Daily Message Instance], an intermediary device can determi...";
CM_ SG_ 2555576062 DailyDataManufacturerID "Daily Data Manufacturer ID: This 11-bit Manufacturer ID (defined in the J1939DA) identifies the transmitter manufacturer whose cloud or data repository is the final destination for the associated data.";
CM_ BO_ 2364675326 "High Voltage Energy Storage Pack 7 Status 2";
CM_ SG_ 2364675326 HVESP7DshrgPwrLmtDtSttfChrg "HVESP7 Discharge Power Limit Due to State of Charge: Indicates whether or not discharge power of this HVES instance is being limited due to state of charge.This parameter is for one of multiple packs in an HVESS.  If there is only one pack in the sys...";
CM_ SG_ 2364675326 HVESP7DshrgPwrLmtDtBttrTmprtr "HVESP7 Discharge Power Limit Due to Battery Temperature: Indicates whether or not discharge power of this HVES instance is being limited due to battery temperature.This parameter is for one of multiple packs in an HVESS.  If there is only one pack in...";
CM_ SG_ 2364675326 HVESP7DsPwLtDtBttDstCdt "HVESP7 Discharge Power Limit Due to Battery Diagnostic Condition: Indicates whether or not discharge power of this HVES instance is being limited due to a battery diagnostic condition.This parameter is for one of multiple packs in an HVESS.  If there...";
CM_ SG_ 2364675326 HVESP7DshrgPwrLmtDtBttrrCllVltg "HVESP7 Discharge Power Limit Due to Battery or Cell Voltage: Indicates whether or not discharge power of this HVES instance is being limited due to a battery or cell voltage level.This parameter is for one of multiple packs in an HVESS.  If there is ...";
CM_ SG_ 2364675326 HVESP7DshrgPwrLmtDtBttrCrrnt "HVESP7 Discharge Power Limit Due to Battery Current: Indicates whether or not discharge power of this HVES instance is being limited due to battery current.This parameter is for one of multiple packs in an HVESS.  If there is only one pack in the sys...";
CM_ SG_ 2364675326 HVESP7DshrgPwrLmtDtnUndfndCs "HVESP7 Discharge Power Limit Due to an Undefined Cause: Indicates whether or not discharge power of this HVES instance is being limited due to an undefined cause.This parameter is for one of multiple packs in an HVESS.  If there is only one pack in t...";
CM_ SG_ 2364675326 HVESP7ChrgPwrLmtDtSttfChrg "HVESP7 Charge Power Limit Due to State of Charge: Indicates whether or not charge power of this HVES instance is being limited due to state of charge.This parameter is for one of multiple packs in an HVESS.  If there is only one pack in the system, t...";
CM_ SG_ 2364675326 HVESP7ChrgPwrLmtDtBttrTmprtr "HVESP7 Charge Power Limit Due to Battery Temperature: Indicates whether or not charge power of this HVES instance is being limited due to battery temperature.This parameter is for one of multiple packs in an HVESS.  If there is only one pack in the s...";
CM_ SG_ 2364675326 HVESP7CPwLtDtBttDstCdt "HVESP7 Charge Power Limit Due to Battery Diagnostic Condition: Indicates whether or not charge power of this HVES instance is being limited due to a battery diagnostic condition.This parameter is for one of multiple packs in an HVESS.  If there is on...";
CM_ SG_ 2364675326 HVESP7ChrgPwrLmtDtBttrrCllVltg "HVESP7 Charge Power Limit Due to Battery or Cell Voltage: Indicates whether or not charge power of this HVES instance is being limited due to a battery or cell voltage level.This parameter is for one of multiple packs in an HVESS.  If there is only o...";
CM_ SG_ 2364675326 HVESP7ChrgPwrLmtDtBttrCrrnt "HVESP7 Charge Power Limit Due to Battery Current: Indicates whether or not charge power of this HVES instance is being limited due to battery current.This parameter is for one of multiple packs in an HVESS.  If there is only one pack in the system, t...";
CM_ SG_ 2364675326 HVESP7ChrgPwrLmtDtnUndfndCs "HVESP7 Charge Power Limit Due to an Undefined Cause: Indicates whether or not charge power of this HVES instance is being limited due to an undefined cause.This parameter is for one of multiple packs in an HVESS.  If there is only one pack in the sys...";
CM_ BO_ 2364675582 "High Voltage Energy Storage Pack 7 Data 1";
CM_ SG_ 2364675582 HVESP7AvailableDischargePower "HVESP7 Available Discharge Power: The rate at which this High Voltage Energy Storage Pack instance can currently provide energy for propulsion or other uses.This parameter is for one of multiple packs in an HVESS.  If there is only one pack in the sy...";
CM_ SG_ 2364675582 HVESP7AvailableChargePower "HVESP7 Available Charge Power: The rate at which this High Voltage Energy Storage Pack instance can currently receive energy from a regenerative or recharging system.This parameter is for one of multiple packs in an HVESS.  If there is only one pack ...";
CM_ SG_ 2364675582 HVESP7VoltageLevel "HVESP7 Voltage Level: The voltage level of this High Voltage Energy Storage Pack instance. This parameter should be synchronized with SPN 14063 (HVESP7 Current) such that a realized power value can be calculated. If the HVES component physically cont...";
CM_ SG_ 2364675582 HVESP7Current "HVESP7 Current: The current in or out of this High Voltage Energy Storage Pack instance. This parameter should be synchronized with SPN 14062 (HVESP7 Voltage Level) such that a realized power value can be calculated. This parameter is defined from th...";
CM_ BO_ 2364675838 "High Voltage Energy Storage Pack 7 Data 2";
CM_ SG_ 2364675838 HVESP7FastUpdateStateofCharge "HVESP7 Fast Update State of Charge: Indicates this High Voltage Energy Storage Pack instance state of charge. 0% means no charge remaining, 100% means the system is fully charged in terms of physical limits of this energy storage pack instance. Accep...";
CM_ SG_ 2364675838 HVESP7HighestCellVoltage "HVESP7 Highest Cell Voltage: The highest voltage level reported by any cell in this High Voltage Energy Storage Pack instance. If a single voltage sensor covers more than one cell, the value in this parameter is for the smallest group of cells measur...";
CM_ SG_ 2364675838 HVESP7LowestCellVoltage "HVESP7 Lowest Cell Voltage: The lowest voltage level reported by any cell in this High Voltage Energy Storage Pack instance. If a single voltage sensor covers more than one cell, the value in this parameter is for the smallest group of cells measured...";
CM_ SG_ 2364675838 HVESP7CllVltgDffrntlStts "HVESP7 Cell Voltage Differential Status: Indicates whether or not the differential between the highest and lowest cell voltages are within acceptable limits, according to this High Voltage Energy Storage Pack instance. The actual voltage differential...";
CM_ BO_ 2364676094 "High Voltage Energy Storage Pack 7 Data 3";
CM_ SG_ 2364676094 HVESP7HighestCellTemperature "HVESP7 Highest Cell Temperature: The highest temperature level reported by any cell in this High Voltage Energy Storage Pack instance. If a single temperature sensor covers more than one cell, the value in this parameter is for the smallest group of ...";
CM_ SG_ 2364676094 HVESP7LowestCellTemperature "HVESP7 Lowest Cell Temperature: The lowest temperature level reported by any cell in this High Voltage Energy Storage Pack instance. If a single temperature sensor covers more than one cell, the value in this parameter is for the smallest group of ce...";
CM_ SG_ 2364676094 HVESP7AverageCellTemperature "HVESP7 Average Cell Temperature: The average temperature level of all cells in this High Voltage Energy Storage Pack instance.This parameter is for one of multiple packs in an HVESS.  If there is only one pack in the system, the HVESS parameters shou...";
CM_ SG_ 2364676094 HVESP7CllTmprtrDffrntlStts "HVESP7 Cell Temperature Differential Status: Indicates whether or not the differential between the highest and lowest cell temperatures are within acceptable limits per this High Voltage Energy Storage Pack instance. The actual temperature differenti...";
CM_ BO_ 2364676350 "High Voltage Energy Storage Pack 7 Data 4";
CM_ SG_ 2364676350 HVESP7DischargeCapacity "HVESP7 Discharge Capacity: The amount of stored electrical charge in this High Voltage Energy Storage Pack instance that is available for use by the hybrid system, i.e. “how full is the tank”. See SPN 14102 (HVESP7 Discharge Energy Capacity) for kilo...";
CM_ SG_ 2364676350 HVESP7ChargeCapacity "HVESP7 Charge Capacity: The amount of unused electrical charge storage in this High Voltage Energy Storage Pack instance that is available to be filled by charging, i.e. “how much empty space is remaining in the tank”. See SPN 14103 (HVESP7 Charge En...";
CM_ SG_ 2364676350 HVESP7CellBalancingCount "HVESP7 Cell Balancing Count: The number of cells that are currently being balanced in this High Voltage Energy Storage Pack instance.This parameter is for one of multiple packs in an HVESS.  If there is only one pack in the system, the HVESS paramete...";
CM_ BO_ 2364676606 "High Voltage Energy Storage Pack 7 Data 5";
CM_ SG_ 2364676606 HVESP7DischargeCurrentLimit "HVESP7 Discharge Current Limit: The maximum permissible current flow out of this High Voltage Energy Storage Pack instance. This parameter is defined from the high voltage energy storage pack's point of view.A negative value represents current flowin...";
CM_ SG_ 2364676606 HVESP7ChargeCurrentLimit "HVESP7 Charge Current Limit: The maximum permissible current flow into this High Voltage Energy Storage Pack instance. This parameter is defined from the high voltage energy storage pack's point of view.A positive value represents current flowing int...";
CM_ SG_ 2364676606 HVESP7LowestCellStateofCharge "HVESP7 Lowest Cell State of Charge: Indicates the state of charge of the lowest-charged cell in this High Voltage Energy Storage Pack instance. 0% means no charge remaining, 100% means the cell is fully charged. If a single state of charge value cove...";
CM_ SG_ 2364676606 HVESP7HighestCellStateofCharge "HVESP7 Highest Cell State of Charge: Indicates the state of charge of the highest-charged cell in this High Voltage Energy Storage Pack instance. 0% means no charge remaining, 100% means the cell is fully charged. If a single state of charge value co...";
CM_ BO_ 2364676862 "High Voltage Energy Storage Pack 7 Data 6";
CM_ SG_ 2364676862 HVESP7BusVoltage "HVESP7 Bus Voltage: The voltage level of the high voltage bus, as measured by this High Voltage Energy Storage Pack instance on the bus side (not the battery side) of its contactors.This parameter is for one of multiple packs in an HVESS.  If there i...";
CM_ SG_ 2364676862 HVESP7IgnitionVoltage "HVESP7 Ignition Voltage: The voltage level at the ignition input of this High Voltage Energy Storage Pack controller.This parameter is for one of multiple packs in an HVESS.  If there is only one pack in the system, the HVESS parameters should be use...";
CM_ SG_ 2364676862 HVESP7IntakeCoolantTemperature "HVESP7 Intake Coolant Temperature: The temperature of liquid coolant as it enters this High Voltage Energy Storage Pack instance.This parameter is for one of multiple packs in an HVESS.  If there is only one pack in the system, the HVESS parameters s...";
CM_ SG_ 2364676862 HVESP7OutletCoolantTemperature "HVESP7 Outlet Coolant Temperature: The temperature of liquid coolant as it exits this High Voltage Energy Storage Pack instance.This parameter is for one of multiple packs in an HVESS.  If there is only one pack in the system, the HVESS parameters sh...";
CM_ SG_ 2364676862 HVESP7ElectronicsTemperature "HVESP7 Electronics Temperature: The temperature of the electronics or control modules in this High Voltage Energy Storage Pack instance.  If there are multiple temperature sensors then this parameter would be set to the maximum sensor reading.This pa...";
CM_ SG_ 2364676862 HVESP7Temperature "HVESP7 Temperature: The temperature of this High Voltage Energy Storage Pack instance. The value may be determined from a unique sensor specifically for this purpose, or by aggregating various temperature sensor readings within the pack.This paramete...";
CM_ BO_ 2364677118 "High Voltage Energy Storage Pack 7 Status 1";
CM_ SG_ 2364677118 HVESP7HghVltgBsPstvCnttrStt "HVESP7 High-Voltage Bus (Positive) Contactor State: Position of this High Voltage Energy Storage Pack instance positive side bus contactor.  When this contactor is closed, the positive side of this HVES instance is connected to the positive side of t...";
CM_ SG_ 2364677118 HVESP7HghVltgBsNgtvCnttrStt "HVESP7 High-Voltage Bus (Negative) Contactor State: Position of this High Voltage Energy Storage Pack instance negative side bus contactor. When this contactor is closed, the negative side of this HVES instance is connected to the negative side of th...";
CM_ SG_ 2364677118 HVESP7HghVltgBsDsnntFrwrnng "HVESP7 High-Voltage Bus Disconnect Forewarning: Indicates that this High Voltage Energy Storage Pack instance is about to disconnect from the high voltage bus due to unacceptable conditions.This parameter is for one of multiple packs in an HVESS. If ...";
CM_ SG_ 2364677118 HVESP7HghVltgBsPrChrgRlStt "HVESP7 High-Voltage Bus Pre-Charge Relay State: Position of the high-voltage bus contactor pre-charge relay.  When this relay is closed, this High Voltage Energy Storage Pack instance is bringing the high-voltage bus up to its operating level.This pa...";
CM_ SG_ 2364677118 HVESP7CntrfPkCnttrStt "HVESP7 Center of Pack Contactor State: Position of the center high-voltage contactor. When this contactor is closed, the positive half of this High Voltage Energy Storage Pack instance is connected to the negative half. If a system controls the posit...";
CM_ SG_ 2364677118 HVESP7HghVltgBsAtvIsltnTstStts "HVESP7 High-Voltage Bus Active Isolation Test Status: Status of the high-voltage bus electrical active isolation test as performed by this High Voltage Energy Storage Pack instance.This parameter is for one of multiple packs in an HVESS. If there is ...";
CM_ SG_ 2364677118 HVESP7HghVltgBsPssvIsltnTstStts "HVESP7 High-Voltage Bus Passive Isolation Test Status: Status of the high-voltage bus electrical passive isolation test as performed by this High Voltage Energy Storage Pack instance.This parameter is for one of multiple packs in an HVESS. If there i...";
CM_ SG_ 2364677118 HVESP7HVILStatus "HVESP7 HVIL Status: Status of the High Voltage Interlock Loop from the viewpoint of this High Voltage Energy Storage Pack instance.This parameter is for one of multiple packs in an HVESS. If there is only one pack in the system, the HVESS parameters ...";
CM_ SG_ 2364677118 HVESP7InertiaSwitchStatus "HVESP7 Inertia Switch Status: Switch indicating that an impact has been sensed by this High Voltage Energy Storage Pack instance. The impact indication may require action by another controller, or by this HVES instance itself.  For example, a control...";
CM_ SG_ 2364677118 HVESP7StateofChargeStatus "HVESP7 State of Charge Status: Status of this High Voltage Energy Storage Pack instance State of Charge (SOC).  Note:  A given HVES controller may not support all of the states.This parameter is for one of multiple packs in an HVESS.  If there is onl...";
CM_ SG_ 2364677118 HVESP7CellBalanceStatus "HVESP7 Cell Balance Status: Indicates whether or not the cells in this High Voltage Energy Storage Pack instance are balanced.This parameter is for one of multiple packs in an HVESS.  If there is only one pack in the system, the HVESS parameters shou...";
CM_ SG_ 2364677118 HVESP7CellBalancingActive "HVESP7 Cell Balancing Active: Indicates whether or not the cells in this High Voltage Energy Storage Pack instance are currently being balanced.This parameter is for one of multiple packs in an HVESS.  If there is only one pack in the system, the HVE...";
CM_ SG_ 2364677118 HVESP7InternalChargerStatus "HVESP7 Internal Charger Status: Indicates that the charger in this HVES instance is on.  External chargers may use the External Energy Source Connection Status (SPN 7898) and related SPs.This parameter is for one of multiple packs in an HVESS. If the...";
CM_ SG_ 2364677118 HVESP7HghVltgBsCnntnStts "HVESP7 High-Voltage Bus Connection Status: This parameter provides high level feedback on this High Voltage Energy Storage Pack instance high voltage bus connection. For specific contactor information, see SPN 14085 (HVESP7 High-Voltage Bus (Positive...";
CM_ SG_ 2364677118 HVESP7OperationalStatus "HVESP7 Operational Status: Provides feedback on where this High Voltage Energy Storage Pack instance is in its operating spectrum, and includes feedback in response to the Operation Consent [i.e. SPN 14043 (HVESP7 Operation Consent)] and Power Down C...";
CM_ SG_ 2364677118 HVESP7Status1Counter "HVESP7 Status 1 Counter: The message counter is used to detect situations where the transmitting ECU malfunction repeats the same frame all the time. The receiver of the information may use the counter parameter to detect this situation. The transmit...";
CM_ SG_ 2364677118 HVESP7Status1CRC "HVESP7 Status 1 CRC: The CRC is defined as follows: • Length: 8 bits • Polynomial: x^8+x^5+x^3+x^2+x+1 • Initial Value: FFh • Input Data Reflection: Not reflected • Result Data Reflection: Not reflected • XOR value: FFhSAE makes no claim of the funct...";
CM_ BO_ 2364677374 "High Voltage Energy Storage Pack 7 Data 7";
CM_ SG_ 2364677374 HVESP7DischargeEnergyCapacity "HVESP7 Discharge Energy Capacity: The amount of stored electrical energy in this High Voltage Energy Storage Pack instance that is available for use by the hybrid system, i.e. “how full is the tank”. See SPN 14072 (HVESP7 Discharge Capacity) for Ampe...";
CM_ SG_ 2364677374 HVESP7ChargeEnergyCapacity "HVESP7 Charge Energy Capacity: The amount of unused electrical energy storage available to be filled by charging this High Voltage Energy Storage Pack instance, i.e. “how much empty space is remaining in the tank”. See SPN 14073 (HVESP7 Charge Capaci...";
CM_ SG_ 2364677374 HVESP7MaximumChargeVoltageLimit "HVESP7 Maximum Charge Voltage Limit: The maximum voltage level not to be exceeded while charging this High Voltage Energy Storage Pack instance. If this parameter is not supported, the maximum charge voltage should be limited to SPN 14173 (HVESP7 Rec...";
CM_ BO_ 2364677630 "High Voltage Energy Storage Pack 7 Module Status 1";
CM_ SG_ 2364677630 HVESP7Module1OperationalStatus "HVESP7 Module 1 Operational Status: Operational Status of Module 1 in this High Voltage Energy Storage Pack Instance.  Not Operational is used when the module is initializing or not able to function (e.g. internal module level monitors have failed). ...";
CM_ SG_ 2364677630 HVESP7Module2OperationalStatus "HVESP7 Module 2 Operational Status: Operational Status of Module 2 in this High Voltage Energy Storage Pack Instance.  Not Operational is used when the module is initializing or not able to function (e.g. internal module level monitors have failed). ...";
CM_ SG_ 2364677630 HVESP7Module3OperationalStatus "HVESP7 Module 3 Operational Status: Operational Status of Module 3 in this High Voltage Energy Storage Pack Instance.  Not Operational is used when the module is initializing or not able to function (e.g. internal module level monitors have failed). ...";
CM_ SG_ 2364677630 HVESP7Module4OperationalStatus "HVESP7 Module 4 Operational Status: Operational Status of Module 4 in this High Voltage Energy Storage Pack Instance.  Not Operational is used when the module is initializing or not able to function (e.g. internal module level monitors have failed). ...";
CM_ SG_ 2364677630 HVESP7Module5OperationalStatus "HVESP7 Module 5 Operational Status: Operational Status of Module 5 in this High Voltage Energy Storage Pack Instance.  Not Operational is used when the module is initializing or not able to function (e.g. internal module level monitors have failed). ...";
CM_ SG_ 2364677630 HVESP7Module6OperationalStatus "HVESP7 Module 6 Operational Status: Operational Status of Module 6 in this High Voltage Energy Storage Pack Instance.  Not Operational is used when the module is initializing or not able to function (e.g. internal module level monitors have failed). ...";
CM_ SG_ 2364677630 HVESP7Module7OperationalStatus "HVESP7 Module 7 Operational Status: Operational Status of Module 7 in this High Voltage Energy Storage Pack Instance.  Not Operational is used when the module is initializing or not able to function (e.g. internal module level monitors have failed). ...";
CM_ SG_ 2364677630 HVESP7Module8OperationalStatus "HVESP7 Module 8 Operational Status: Operational Status of Module 8 in this High Voltage Energy Storage Pack Instance.  Not Operational is used when the module is initializing or not able to function (e.g. internal module level monitors have failed). ...";
CM_ SG_ 2364677630 HVESP7Module9OperationalStatus "HVESP7 Module 9 Operational Status: Operational Status of Module 9 in this High Voltage Energy Storage Pack Instance.  Not Operational is used when the module is initializing or not able to function (e.g. internal module level monitors have failed). ...";
CM_ SG_ 2364677630 HVESP7Module10OperationalStatus "HVESP7 Module 10 Operational Status: Operational Status of Module 10 in this High Voltage Energy Storage Pack Instance.  Not Operational is used when the module is initializing or not able to function (e.g. internal module level monitors have failed)...";
CM_ SG_ 2364677630 HVESP7Module11OperationalStatus "HVESP7 Module 11 Operational Status: Operational Status of Module 11 in this High Voltage Energy Storage Pack Instance.  Not Operational is used when the module is initializing or not able to function (e.g. internal module level monitors have failed)...";
CM_ SG_ 2364677630 HVESP7Module12OperationalStatus "HVESP7 Module 12 Operational Status: Operational Status of Module 12 in this High Voltage Energy Storage Pack Instance.  Not Operational is used when the module is initializing or not able to function (e.g. internal module level monitors have failed)...";
CM_ SG_ 2364677630 HVESP7Module13OperationalStatus "HVESP7 Module 13 Operational Status: Operational Status of Module 13 in this High Voltage Energy Storage Pack Instance.  Not Operational is used when the module is initializing or not able to function (e.g. internal module level monitors have failed)...";
CM_ SG_ 2364677630 HVESP7Module14OperationalStatus "HVESP7 Module 14 Operational Status: Operational Status of Module 14 in this High Voltage Energy Storage Pack Instance.  Not Operational is used when the module is initializing or not able to function (e.g. internal module level monitors have failed)...";
CM_ SG_ 2364677630 HVESP7Module15OperationalStatus "HVESP7 Module 15 Operational Status: Operational Status of Module 15 in this High Voltage Energy Storage Pack Instance.  Not Operational is used when the module is initializing or not able to function (e.g. internal module level monitors have failed)...";
CM_ SG_ 2364677630 HVESP7Module16OperationalStatus "HVESP7 Module 16 Operational Status: Operational Status of Module 16 in this High Voltage Energy Storage Pack Instance.  Not Operational is used when the module is initializing or not able to function (e.g. internal module level monitors have failed)...";
CM_ SG_ 2364677630 HVESP7Module17OperationalStatus "HVESP7 Module 17 Operational Status: Operational Status of Module 17 in this High Voltage Energy Storage Pack Instance.  Not Operational is used when the module is initializing or not able to function (e.g. internal module level monitors have failed)...";
CM_ SG_ 2364677630 HVESP7Module18OperationalStatus "HVESP7 Module 18 Operational Status: Operational Status of Module 18 in this High Voltage Energy Storage Pack Instance.  Not Operational is used when the module is initializing or not able to function (e.g. internal module level monitors have failed)...";
CM_ SG_ 2364677630 HVESP7Module19OperationalStatus "HVESP7 Module 19 Operational Status: Operational Status of Module 19 in this High Voltage Energy Storage Pack Instance.  Not Operational is used when the module is initializing or not able to function (e.g. internal module level monitors have failed)...";
CM_ SG_ 2364677630 HVESP7Module20OperationalStatus "HVESP7 Module 20 Operational Status: Operational Status of Module 20 in this High Voltage Energy Storage Pack Instance.  Not Operational is used when the module is initializing or not able to function (e.g. internal module level monitors have failed)...";
CM_ SG_ 2364677630 HVESP7Module21OperationalStatus "HVESP7 Module 21 Operational Status: Operational Status of Module 21 in this High Voltage Energy Storage Pack Instance.  Not Operational is used when the module is initializing or not able to function (e.g. internal module level monitors have failed)...";
CM_ SG_ 2364677630 HVESP7Module22OperationalStatus "HVESP7 Module 22 Operational Status: Operational Status of Module 22 in this High Voltage Energy Storage Pack Instance.  Not Operational is used when the module is initializing or not able to function (e.g. internal module level monitors have failed)...";
CM_ SG_ 2364677630 HVESP7Module23OperationalStatus "HVESP7 Module 23 Operational Status: Operational Status of Module 23 in this High Voltage Energy Storage Pack Instance.  Not Operational is used when the module is initializing or not able to function (e.g. internal module level monitors have failed)...";
CM_ SG_ 2364677630 HVESP7Module24OperationalStatus "HVESP7 Module 24 Operational Status: Operational Status of Module 24 in this High Voltage Energy Storage Pack Instance.  Not Operational is used when the module is initializing or not able to function (e.g. internal module level monitors have failed)...";
CM_ SG_ 2364677630 HVESP7Module25OperationalStatus "HVESP7 Module 25 Operational Status: Operational Status of Module 25 in this High Voltage Energy Storage Pack Instance.  Not Operational is used when the module is initializing or not able to function (e.g. internal module level monitors have failed)...";
CM_ SG_ 2364677630 HVESP7Module26OperationalStatus "HVESP7 Module 26 Operational Status: Operational Status of Module 26 in this High Voltage Energy Storage Pack Instance.  Not Operational is used when the module is initializing or not able to function (e.g. internal module level monitors have failed)...";
CM_ SG_ 2364677630 HVESP7Module27OperationalStatus "HVESP7 Module 27 Operational Status: Operational Status of Module 27 in this High Voltage Energy Storage Pack Instance.  Not Operational is used when the module is initializing or not able to function (e.g. internal module level monitors have failed)...";
CM_ SG_ 2364677630 HVESP7Module28OperationalStatus "HVESP7 Module 28 Operational Status: Operational Status of Module 28 in this High Voltage Energy Storage Pack Instance.  Not Operational is used when the module is initializing or not able to function (e.g. internal module level monitors have failed)...";
CM_ SG_ 2364677630 HVESP7Module29OperationalStatus "HVESP7 Module 29 Operational Status: Operational Status of Module 29 in this High Voltage Energy Storage Pack Instance.  Not Operational is used when the module is initializing or not able to function (e.g. internal module level monitors have failed)...";
CM_ SG_ 2364677630 HVESP7Module30OperationalStatus "HVESP7 Module 30 Operational Status: Operational Status of Module 30 in this High Voltage Energy Storage Pack Instance.  Not Operational is used when the module is initializing or not able to function (e.g. internal module level monitors have failed)...";
CM_ SG_ 2364677630 HVESP7Module31OperationalStatus "HVESP7 Module 31 Operational Status: Operational Status of Module 31 in this High Voltage Energy Storage Pack Instance.  Not Operational is used when the module is initializing or not able to function (e.g. internal module level monitors have failed)...";
CM_ SG_ 2364677630 HVESP7Module32OperationalStatus "HVESP7 Module 32 Operational Status: Operational Status of Module 32 in this High Voltage Energy Storage Pack Instance.  Not Operational is used when the module is initializing or not able to function (e.g. internal module level monitors have failed)...";
CM_ BO_ 2364677886 "High Voltage Energy Storage Pack 7 Thermal Management System Status 1";
CM_ SG_ 2364677886 HVESP7ThrmlMngmntSstmSLIInptPwr "HVESP7 Thermal Management System SLI Input Power: This is the low-voltage power consumed by this HVES Thermal Management System (TMS).This parameter is for one of multiple packs in an HVESS.  If there is only one pack in the system, the HVESS paramet...";
CM_ SG_ 2364677886 HVESP7TMtSstHVtIptPw "HVESP7 Thermal Management System High-Voltage Input Power: This is the high-voltage power consumed by this HVES Thermal Management System (TMS).This parameter is for one of multiple packs in an HVESS.  If there is only one pack in the system, the HVE...";
CM_ SG_ 2364677886 HVESP7ThrmlMngmntSstmCmprssrSpd "HVESP7 Thermal Management System Compressor Speed: When this High Voltage Energy Storage Pack Thermal Management System is equipped with an active cooling system (e.g. air conditioner), this is the Compressor Speed.This parameter is for one of multip...";
CM_ SG_ 2364677886 HVESP7ThrmlMngmntSstmRltvHmdt "HVESP7 Thermal Management System Relative Humidty: When this High Voltage Energy Storage Pack Thermal Management System is equipped with a relative humidity sensor, this is the  measured Relative Humidity.This parameter is for one of multiple packs i...";
CM_ SG_ 2364677886 HVESP7ThrmlMngmntSstmHtrStts "HVESP7 Thermal Management System Heater Status: The state of this High Voltage Energy Storage Pack heaterThis parameter is for one of multiple packs in an HVESS.  If there is only one pack in the system, the HVESS parameters should be used. If there ...";
CM_ SG_ 2364677886 HVESP7ThrmlMngmntSstmHVILStts "HVESP7 Thermal Management System HVIL Status: In multiple HVES configurations, this is the status of the High Voltage Interlock Loop from the viewpoint of this Thermal Management System.00b = HVIL Closed01b = HVIL Open10b = Error11b = Not AvailableTh...";
CM_ SG_ 2364677886 HVESP7ThrmlMngmntSstmMd "HVESP7 Thermal Management System Mode: Indicates the operating mode of the Thermal Management System.  The heat transfer medium may be (e.g. liquid or air).  The cooling system may be fans, liquid coolant, or a combination of mediums.  The system may...";
CM_ SG_ 2364677886 HVESP7ThrmlMngmntSstmClntLvl "HVESP7 Thermal Management System Coolant Level: Indicates the coolant level in this HVES Thermal Management System (TMS).This parameter is for one of multiple packs in an HVESS.  If there is only one pack in the system, the HVESS parameters should be...";
CM_ BO_ 2364678142 "High Voltage Energy Storage Pack 7 Data 8";
CM_ SG_ 2364678142 HVESP7HghstCllVltgMdlNmr "HVESP7 Highest Cell Voltage Module Number: Identifies the location of the module containing SPN 14065 (HVESP7 Highest Cell Voltage).This parameter is for one of multiple packs in an HVESS. If there is only one pack in the system, the HVESS parameters...";
CM_ SG_ 2364678142 HVESP7HghstCllVltgCllNmr "HVESP7 Highest Cell Voltage Cell Number: Identifies the location of SPN 14065 (HVESP7 Highest Cell Voltage) within SPN 14145 (HVESP7 Highest Cell Voltage Module Number).This parameter is for one of multiple packs in an HVESS. If there is only one pac...";
CM_ SG_ 2364678142 HVESP7LwstCllVltgMdlNmr "HVESP7 Lowest Cell Voltage Module Number: Identifies the location of the module containing SPN 14066 (HVESP7 Lowest Cell Voltage).This parameter is for one of multiple packs in an HVESS. If there is only one pack in the system, the HVESS parameters s...";
CM_ SG_ 2364678142 HVESP7LwstCllVltgCllNmr "HVESP7 Lowest Cell Voltage Cell Number: Identifies the location of SPN 14066 (HVESP7 Lowest Cell Voltage) within SPN 14147 (HVESP7 Lowest Cell Voltage Module Number).This parameter is for one of multiple packs in an HVESS. If there is only one pack i...";
CM_ SG_ 2364678142 HVESP7AverageCellVoltage "HVESP7 Average Cell Voltage: The average cell voltage in this High Voltage Energy Storage Pack instance.This parameter is for one of multiple packs in an HVESS.  If there is only one pack in the system, the HVESS parameters should be used. If there a...";
CM_ BO_ 2364678398 "High Voltage Energy Storage Pack 7 Data 9";
CM_ SG_ 2364678398 HVESP7HghstCllTmprtrMdlNmr "HVESP7 Highest Cell Temperature Module Number: Identifies the location of the module containing SPN 14068 (HVESP7 Highest Cell Temperature).This parameter is for one of multiple packs in an HVESS. If there is only one pack in the system, the HVESS pa...";
CM_ SG_ 2364678398 HVESP7HghstCllTmprtrCllNmr "HVESP7 Highest Cell Temperature Cell Number: Identifies the location of SPN 14068 (HVESP7 Highest Cell Temperature) within SPN 14150 (HVESP7 Highest Cell Temperature Module Number).This parameter is for one of multiple packs in an HVESS. If there is ...";
CM_ SG_ 2364678398 HVESP7LwstCllTmprtrMdlNmr "HVESP7 Lowest Cell Temperature Module Number: Identifies the location of the module containing SPN 14069 (HVESP7 Lowest Cell Temperature).This parameter is for one of multiple packs in an HVESS. If there is only one pack in the system, the HVESS para...";
CM_ SG_ 2364678398 HVESP7LwstCllTmprtrCllNmr "HVESP7 Lowest Cell Temperature Cell Number: Identifies the location of SPN 14069 (HVESP7 Lowest Cell Temperature) within SPN 14152 (HVESP7 Lowest Cell Temperature Module Number).This parameter is for one of multiple packs in an HVESS. If there is onl...";
CM_ BO_ 2364678654 "High Voltage Energy Storage Pack 7 Data 10";
CM_ SG_ 2364678654 HVESP7HghstCllSttfChrgMdlNmr "HVESP7 Highest Cell State of Charge Module Number: Identifies the location of the module containing SPN 14078 (HVESP7 Highest Cell State of Charge).This parameter is for one of multiple packs in an HVESS. If there is only one pack in the system, the ...";
CM_ SG_ 2364678654 HVESP7HghstCllSttfChrgCllNmr "HVESP7 Highest Cell State of Charge Cell Number: Identifies the location of SPN 14078 (HVESP7 Highest Cell State of Charge) within SPN 14154 (HVESP7 Highest Cell State of Charge Module Number).This parameter is for one of multiple packs in an HVESS. ...";
CM_ SG_ 2364678654 HVESP7LwstCllSttfChrgMdlNmr "HVESP7 Lowest Cell State of Charge Module Number: Identifies the location of the module containing SPN 14077 (HVESP7 Lowest Cell State of Charge).This parameter is for one of multiple packs in an HVESS. If there is only one pack in the system, the HV...";
CM_ SG_ 2364678654 HVESP7LwstCllSttfChrgCllNmr "HVESP7 Lowest Cell State of Charge Cell Number: Identifies the location of SPN 14077 (HVESP7 Lowest Cell State of Charge) within SPN 14156 (HVESP7 Lowest Cell State of Charge Module Number).This parameter is for one of multiple packs in an HVESS. If ...";
CM_ SG_ 2364678654 HVESP7HghVltgBsAtvIsltnTstRslts "HVESP7 High-Voltage Bus Active Isolation Test Results: The isolation resistance expressed in Ohms per Volt that resulted from the High-Voltage Bus Active Isolation Test.See SPN 14090 (HVESP7 High-Voltage Bus Active Isolation Test Status) for test sta...";
CM_ SG_ 2364678654 HVESP7HVtBsPssvIstTstRsts "HVESP7 High-Voltage Bus Passive Isolation Test Results: The isolation resistance expressed in Ohms per Volt that resulted from the High-Voltage Bus Passive Isolation Test.See SPN 14091 (HVESP7 High-Voltage Bus Passive Isolation Test Status) for test ...";
CM_ BO_ 2364678910 "High Voltage Energy Storage Pack 7 Data 11";
CM_ SG_ 2364678910 HVESP7BsVltgNgtvtChsssGrndVltg "HVESP7 Bus Voltage Negative to Chassis Ground Voltage: Voltage difference between the most negative terminal of the HVES battery and chassis measured on the hybrid system bus side (not the battery side) of any HVES contained output contactor.  This v...";
CM_ SG_ 2364678910 HVESP7VltgLvlNgtvtChsssGrndVltg "HVESP7 Voltage Level Negative to Chassis Ground Voltage: Voltage difference between the most negative terminal of the HVES battery and chassis measured at the battery side of any HVES contained output contactor.  This voltage may be used for system l...";
CM_ SG_ 2364678910 HVESP7ActualChargeRate "HVESP7 Actual Charge Rate: This signal represents the actual present charge rate of this High Voltage Energy Storage Pack instance.This parameter is for one of multiple packs in an HVESS. If there is only one pack in the system, the HVESS parameters ...";
CM_ BO_ 2364679166 "High Voltage Energy Storage Pack 8 Status 2";
CM_ SG_ 2364679166 HVESP8DshrgPwrLmtDtSttfChrg "HVESP8 Discharge Power Limit Due to State of Charge: Indicates whether or not discharge power of this HVES instance is being limited due to state of charge.This parameter is for one of multiple packs in an HVESS.  If there is only one pack in the sys...";
CM_ SG_ 2364679166 HVESP8DshrgPwrLmtDtBttrTmprtr "HVESP8 Discharge Power Limit Due to Battery Temperature: Indicates whether or not discharge power of this HVES instance is being limited due to battery temperature.This parameter is for one of multiple packs in an HVESS.  If there is only one pack in...";
CM_ SG_ 2364679166 HVESP8DsPwLtDtBttDstCdt "HVESP8 Discharge Power Limit Due to Battery Diagnostic Condition: Indicates whether or not discharge power of this HVES instance is being limited due to a battery diagnostic condition.This parameter is for one of multiple packs in an HVESS.  If there...";
CM_ SG_ 2364679166 HVESP8DshrgPwrLmtDtBttrrCllVltg "HVESP8 Discharge Power Limit Due to Battery or Cell Voltage: Indicates whether or not discharge power of this HVES instance is being limited due to a battery or cell voltage level.This parameter is for one of multiple packs in an HVESS.  If there is ...";
CM_ SG_ 2364679166 HVESP8DshrgPwrLmtDtBttrCrrnt "HVESP8 Discharge Power Limit Due to Battery Current: Indicates whether or not discharge power of this HVES instance is being limited due to battery current.This parameter is for one of multiple packs in an HVESS.  If there is only one pack in the sys...";
CM_ SG_ 2364679166 HVESP8DshrgPwrLmtDtnUndfndCs "HVESP8 Discharge Power Limit Due to an Undefined Cause: Indicates whether or not discharge power of this HVES instance is being limited due to an undefined cause.This parameter is for one of multiple packs in an HVESS.  If there is only one pack in t...";
CM_ SG_ 2364679166 HVESP8ChrgPwrLmtDtSttfChrg "HVESP8 Charge Power Limit Due to State of Charge: Indicates whether or not charge power of this HVES instance is being limited due to state of charge.This parameter is for one of multiple packs in an HVESS.  If there is only one pack in the system, t...";
CM_ SG_ 2364679166 HVESP8ChrgPwrLmtDtBttrTmprtr "HVESP8 Charge Power Limit Due to Battery Temperature: Indicates whether or not charge power of this HVES instance is being limited due to battery temperature.This parameter is for one of multiple packs in an HVESS.  If there is only one pack in the s...";
CM_ SG_ 2364679166 HVESP8CPwLtDtBttDstCdt "HVESP8 Charge Power Limit Due to Battery Diagnostic Condition: Indicates whether or not charge power of this HVES instance is being limited due to a battery diagnostic condition.This parameter is for one of multiple packs in an HVESS.  If there is on...";
CM_ SG_ 2364679166 HVESP8ChrgPwrLmtDtBttrrCllVltg "HVESP8 Charge Power Limit Due to Battery or Cell Voltage: Indicates whether or not charge power of this HVES instance is being limited due to a battery or cell voltage level.This parameter is for one of multiple packs in an HVESS.  If there is only o...";
CM_ SG_ 2364679166 HVESP8ChrgPwrLmtDtBttrCrrnt "HVESP8 Charge Power Limit Due to Battery Current: Indicates whether or not charge power of this HVES instance is being limited due to battery current.This parameter is for one of multiple packs in an HVESS.  If there is only one pack in the system, t...";
CM_ SG_ 2364679166 HVESP8ChrgPwrLmtDtnUndfndCs "HVESP8 Charge Power Limit Due to an Undefined Cause: Indicates whether or not charge power of this HVES instance is being limited due to an undefined cause.This parameter is for one of multiple packs in an HVESS.  If there is only one pack in the sys...";
CM_ BO_ 2364679422 "High Voltage Energy Storage Pack 8 Data 1";
CM_ SG_ 2364679422 HVESP8AvailableDischargePower "HVESP8 Available Discharge Power: The rate at which this High Voltage Energy Storage Pack instance can currently provide energy for propulsion or other uses.This parameter is for one of multiple packs in an HVESS.  If there is only one pack in the sy...";
CM_ SG_ 2364679422 HVESP8AvailableChargePower "HVESP8 Available Charge Power: The rate at which this High Voltage Energy Storage Pack instance can currently receive energy from a regenerative or recharging system.This parameter is for one of multiple packs in an HVESS.  If there is only one pack ...";
CM_ SG_ 2364679422 HVESP8VoltageLevel "HVESP8 Voltage Level: The voltage level of this High Voltage Energy Storage Pack instance. This parameter should be synchronized with SPN 14206 (HVESP8 Current) such that a realized power value can be calculated. If the HVES component physically cont...";
CM_ SG_ 2364679422 HVESP8Current "HVESP8 Current: The current in or out of this High Voltage Energy Storage Pack instance. This parameter should be synchronized with SPN 14205 (HVESP8 Voltage Level) such that a realized power value can be calculated. This parameter is defined from th...";
CM_ BO_ 2364679678 "High Voltage Energy Storage Pack 8 Data 2";
CM_ SG_ 2364679678 HVESP8FastUpdateStateofCharge "HVESP8 Fast Update State of Charge: Indicates this High Voltage Energy Storage Pack instance state of charge. 0% means no charge remaining, 100% means the system is fully charged in terms of physical limits of this energy storage pack instance. Accep...";
CM_ SG_ 2364679678 HVESP8HighestCellVoltage "HVESP8 Highest Cell Voltage: The highest voltage level reported by any cell in this High Voltage Energy Storage Pack instance. If a single voltage sensor covers more than one cell, the value in this parameter is for the smallest group of cells measur...";
CM_ SG_ 2364679678 HVESP8LowestCellVoltage "HVESP8 Lowest Cell Voltage: The lowest voltage level reported by any cell in this High Voltage Energy Storage Pack instance. If a single voltage sensor covers more than one cell, the value in this parameter is for the smallest group of cells measured...";
CM_ SG_ 2364679678 HVESP8CllVltgDffrntlStts "HVESP8 Cell Voltage Differential Status: Indicates whether or not the differential between the highest and lowest cell voltages are within acceptable limits, according to this High Voltage Energy Storage Pack instance. The actual voltage differential...";
CM_ BO_ 2364679934 "High Voltage Energy Storage Pack 8 Data 3";
CM_ SG_ 2364679934 HVESP8HighestCellTemperature "HVESP8 Highest Cell Temperature: The highest temperature level reported by any cell in this High Voltage Energy Storage Pack instance. If a single temperature sensor covers more than one cell, the value in this parameter is for the smallest group of ...";
CM_ SG_ 2364679934 HVESP8LowestCellTemperature "HVESP8 Lowest Cell Temperature: The lowest temperature level reported by any cell in this High Voltage Energy Storage Pack instance. If a single temperature sensor covers more than one cell, the value in this parameter is for the smallest group of ce...";
CM_ SG_ 2364679934 HVESP8AverageCellTemperature "HVESP8 Average Cell Temperature: The average temperature level of all cells in this High Voltage Energy Storage Pack instance.This parameter is for one of multiple packs in an HVESS.  If there is only one pack in the system, the HVESS parameters shou...";
CM_ SG_ 2364679934 HVESP8CllTmprtrDffrntlStts "HVESP8 Cell Temperature Differential Status: Indicates whether or not the differential between the highest and lowest cell temperatures are within acceptable limits per this High Voltage Energy Storage Pack instance. The actual temperature differenti...";
CM_ BO_ 2364680190 "High Voltage Energy Storage Pack 8 Data 4";
CM_ SG_ 2364680190 HVESP8DischargeCapacity "HVESP8 Discharge Capacity: The amount of stored electrical charge in this High Voltage Energy Storage Pack instance that is available for use by the hybrid system, i.e. “how full is the tank”. See SPN 14245 (HVESP8 Discharge Energy Capacity) for kilo...";
CM_ SG_ 2364680190 HVESP8ChargeCapacity "HVESP8 Charge Capacity: The amount of unused electrical charge storage in this High Voltage Energy Storage Pack instance that is available to be filled by charging, i.e. “how much empty space is remaining in the tank”. See SPN 14246 (HVESP8 Charge En...";
CM_ SG_ 2364680190 HVESP8CellBalancingCount "HVESP8 Cell Balancing Count: The number of cells that are currently being balanced in this High Voltage Energy Storage Pack instance.This parameter is for one of multiple packs in an HVESS.  If there is only one pack in the system, the HVESS paramete...";
CM_ BO_ 2364680446 "High Voltage Energy Storage Pack 8 Data 5";
CM_ SG_ 2364680446 HVESP8DischargeCurrentLimit "HVESP8 Discharge Current Limit: The maximum permissible current flow out of this High Voltage Energy Storage Pack instance. This parameter is defined from the high voltage energy storage pack's point of view.A negative value represents current flowin...";
CM_ SG_ 2364680446 HVESP8ChargeCurrentLimit "HVESP8 Charge Current Limit: The maximum permissible current flow into this High Voltage Energy Storage Pack instance. This parameter is defined from the high voltage energy storage pack's point of view.A positive value represents current flowing int...";
CM_ SG_ 2364680446 HVESP8LowestCellStateofCharge "HVESP8 Lowest Cell State of Charge: Indicates the state of charge of the lowest-charged cell in this High Voltage Energy Storage Pack instance. 0% means no charge remaining, 100% means the cell is fully charged. If a single state of charge value cove...";
CM_ SG_ 2364680446 HVESP8HighestCellStateofCharge "HVESP8 Highest Cell State of Charge: Indicates the state of charge of the highest-charged cell in this High Voltage Energy Storage Pack instance. 0% means no charge remaining, 100% means the cell is fully charged. If a single state of charge value co...";
CM_ BO_ 2364680702 "High Voltage Energy Storage Pack 8 Data 6";
CM_ SG_ 2364680702 HVESP8BusVoltage "HVESP8 Bus Voltage: The voltage level of the high voltage bus, as measured by this High Voltage Energy Storage Pack instance on the bus side (not the battery side) of its contactors.This parameter is for one of multiple packs in an HVESS.  If there i...";
CM_ SG_ 2364680702 HVESP8IgnitionVoltage "HVESP8 Ignition Voltage: The voltage level at the ignition input of this High Voltage Energy Storage Pack controller.This parameter is for one of multiple packs in an HVESS.  If there is only one pack in the system, the HVESS parameters should be use...";
CM_ SG_ 2364680702 HVESP8IntakeCoolantTemperature "HVESP8 Intake Coolant Temperature: The temperature of liquid coolant as it enters this High Voltage Energy Storage Pack instance.This parameter is for one of multiple packs in an HVESS.  If there is only one pack in the system, the HVESS parameters s...";
CM_ SG_ 2364680702 HVESP8OutletCoolantTemperature "HVESP8 Outlet Coolant Temperature: The temperature of liquid coolant as it exits this High Voltage Energy Storage Pack instance.This parameter is for one of multiple packs in an HVESS.  If there is only one pack in the system, the HVESS parameters sh...";
CM_ SG_ 2364680702 HVESP8ElectronicsTemperature "HVESP8 Electronics Temperature: The temperature of the electronics or control modules in this High Voltage Energy Storage Pack instance.  If there are multiple temperature sensors then this parameter would be set to the maximum sensor reading.This pa...";
CM_ SG_ 2364680702 HVESP8Temperature "HVESP8 Temperature: The temperature of this High Voltage Energy Storage Pack instance. The value may be determined from a unique sensor specifically for this purpose, or by aggregating various temperature sensor readings within the pack.This paramete...";
CM_ BO_ 2364680958 "High Voltage Energy Storage Pack 8 Status 1";
CM_ SG_ 2364680958 HVESP8HghVltgBsPstvCnttrStt "HVESP8 High-Voltage Bus (Positive) Contactor State: Position of this High Voltage Energy Storage Pack instance positive side bus contactor.  When this contactor is closed, the positive side of this HVES instance is connected to the positive side of t...";
CM_ SG_ 2364680958 HVESP8HghVltgBsNgtvCnttrStt "HVESP8 High-Voltage Bus (Negative) Contactor State: Position of this High Voltage Energy Storage Pack instance negative side bus contactor. When this contactor is closed, the negative side of this HVES instance is connected to the negative side of th...";
CM_ SG_ 2364680958 HVESP8HghVltgBsDsnntFrwrnng "HVESP8 High-Voltage Bus Disconnect Forewarning: Indicates that this High Voltage Energy Storage Pack instance is about to disconnect from the high voltage bus due to unacceptable conditions.This parameter is for one of multiple packs in an HVESS. If ...";
CM_ SG_ 2364680958 HVESP8HghVltgBsPrChrgRlStt "HVESP8 High-Voltage Bus Pre-Charge Relay State: Position of the high-voltage bus contactor pre-charge relay.  When this relay is closed, this High Voltage Energy Storage Pack instance is bringing the high-voltage bus up to its operating level.This pa...";
CM_ SG_ 2364680958 HVESP8CntrfPkCnttrStt "HVESP8 Center of Pack Contactor State: Position of the center high-voltage contactor. When this contactor is closed, the positive half of this High Voltage Energy Storage Pack instance is connected to the negative half. If a system controls the posit...";
CM_ SG_ 2364680958 HVESP8HghVltgBsAtvIsltnTstStts "HVESP8 High-Voltage Bus Active Isolation Test Status: Status of the high-voltage bus electrical active isolation test as performed by this High Voltage Energy Storage Pack instance.This parameter is for one of multiple packs in an HVESS. If there is ...";
CM_ SG_ 2364680958 HVESP8HghVltgBsPssvIsltnTstStts "HVESP8 High-Voltage Bus Passive Isolation Test Status: Status of the high-voltage bus electrical passive isolation test as performed by this High Voltage Energy Storage Pack instance.This parameter is for one of multiple packs in an HVESS. If there i...";
CM_ SG_ 2364680958 HVESP8HVILStatus "HVESP8 HVIL Status: Status of the High Voltage Interlock Loop from the viewpoint of this High Voltage Energy Storage Pack instance.This parameter is for one of multiple packs in an HVESS. If there is only one pack in the system, the HVESS parameters ...";
CM_ SG_ 2364680958 HVESP8InertiaSwitchStatus "HVESP8 Inertia Switch Status: Switch indicating that an impact has been sensed by this High Voltage Energy Storage Pack instance. The impact indication may require action by another controller, or by this HVES instance itself.  For example, a control...";
CM_ SG_ 2364680958 HVESP8StateofChargeStatus "HVESP8 State of Charge Status: Status of this High Voltage Energy Storage Pack instance State of Charge (SOC).  Note:  A given HVES controller may not support all of the states.This parameter is for one of multiple packs in an HVESS.  If there is onl...";
CM_ SG_ 2364680958 HVESP8CellBalanceStatus "HVESP8 Cell Balance Status: Indicates whether or not the cells in this High Voltage Energy Storage Pack instance are balanced.This parameter is for one of multiple packs in an HVESS.  If there is only one pack in the system, the HVESS parameters shou...";
CM_ SG_ 2364680958 HVESP8CellBalancingActive "HVESP8 Cell Balancing Active: Indicates whether or not the cells in this High Voltage Energy Storage Pack instance are currently being balanced.This parameter is for one of multiple packs in an HVESS.  If there is only one pack in the system, the HVE...";
CM_ SG_ 2364680958 HVESP8InternalChargerStatus "HVESP8 Internal Charger Status: Indicates that the charger in this HVES instance is on.  External chargers may use the External Energy Source Connection Status (SPN 7898) and related SPs.This parameter is for one of multiple packs in an HVESS. If the...";
CM_ SG_ 2364680958 HVESP8HghVltgBsCnntnStts "HVESP8 High-Voltage Bus Connection Status: This parameter provides high level feedback on this High Voltage Energy Storage Pack instance high voltage bus connection. For specific contactor information, see SPN 14228 (HVESP8 High-Voltage Bus (Positive...";
CM_ SG_ 2364680958 HVESP8OperationalStatus "HVESP8 Operational Status: Provides feedback on where this High Voltage Energy Storage Pack instance is in its operating spectrum, and includes feedback in response to the Operation Consent [i.e. SPN 14186 (HVESP8 Operation Consent)] and Power Down C...";
CM_ SG_ 2364680958 HVESP8Status1Counter "HVESP8 Status 1 Counter: The message counter is used to detect situations where the transmitting ECU malfunction repeats the same frame all the time. The receiver of the information may use the counter parameter to detect this situation. The transmit...";
CM_ SG_ 2364680958 HVESP8Status1CRC "HVESP8 Status 1 CRC: The CRC is defined as follows: • Length: 8 bits • Polynomial: x^8+x^5+x^3+x^2+x+1 • Initial Value: FFh • Input Data Reflection: Not reflected • Result Data Reflection: Not reflected • XOR value: FFhSAE makes no claim of the funct...";
CM_ BO_ 2364681214 "High Voltage Energy Storage Pack 8 Data 7";
CM_ SG_ 2364681214 HVESP8DischargeEnergyCapacity "HVESP8 Discharge Energy Capacity: The amount of stored electrical energy in this High Voltage Energy Storage Pack instance that is available for use by the hybrid system, i.e. “how full is the tank”. See SPN 14215 (HVESP8 Discharge Capacity) for Ampe...";
CM_ SG_ 2364681214 HVESP8ChargeEnergyCapacity "HVESP8 Charge Energy Capacity: The amount of unused electrical energy storage available to be filled by charging this High Voltage Energy Storage Pack instance, i.e. “how much empty space is remaining in the tank”. See SPN 14216 (HVESP8 Charge Capaci...";
CM_ SG_ 2364681214 HVESP8MaximumChargeVoltageLimit "HVESP8 Maximum Charge Voltage Limit: The maximum voltage level not to be exceeded while charging this High Voltage Energy Storage Pack instance. If this parameter is not supported, the maximum charge voltage should be limited to SPN 14316 (HVESP8 Rec...";
CM_ BO_ 2364681470 "High Voltage Energy Storage Pack 8 Module Status 1";
CM_ SG_ 2364681470 HVESP8Module1OperationalStatus "HVESP8 Module 1 Operational Status: Operational Status of Module 1 in this High Voltage Energy Storage Pack Instance.  Not Operational is used when the module is initializing or not able to function (e.g. internal module level monitors have failed). ...";
CM_ SG_ 2364681470 HVESP8Module2OperationalStatus "HVESP8 Module 2 Operational Status: Operational Status of Module 2 in this High Voltage Energy Storage Pack Instance.  Not Operational is used when the module is initializing or not able to function (e.g. internal module level monitors have failed). ...";
CM_ SG_ 2364681470 HVESP8Module3OperationalStatus "HVESP8 Module 3 Operational Status: Operational Status of Module 3 in this High Voltage Energy Storage Pack Instance.  Not Operational is used when the module is initializing or not able to function (e.g. internal module level monitors have failed). ...";
CM_ SG_ 2364681470 HVESP8Module4OperationalStatus "HVESP8 Module 4 Operational Status: Operational Status of Module 4 in this High Voltage Energy Storage Pack Instance.  Not Operational is used when the module is initializing or not able to function (e.g. internal module level monitors have failed). ...";
CM_ SG_ 2364681470 HVESP8Module5OperationalStatus "HVESP8 Module 5 Operational Status: Operational Status of Module 5 in this High Voltage Energy Storage Pack Instance.  Not Operational is used when the module is initializing or not able to function (e.g. internal module level monitors have failed). ...";
CM_ SG_ 2364681470 HVESP8Module6OperationalStatus "HVESP8 Module 6 Operational Status: Operational Status of Module 6 in this High Voltage Energy Storage Pack Instance.  Not Operational is used when the module is initializing or not able to function (e.g. internal module level monitors have failed). ...";
CM_ SG_ 2364681470 HVESP8Module7OperationalStatus "HVESP8 Module 7 Operational Status: Operational Status of Module 7 in this High Voltage Energy Storage Pack Instance.  Not Operational is used when the module is initializing or not able to function (e.g. internal module level monitors have failed). ...";
CM_ SG_ 2364681470 HVESP8Module8OperationalStatus "HVESP8 Module 8 Operational Status: Operational Status of Module 8 in this High Voltage Energy Storage Pack Instance.  Not Operational is used when the module is initializing or not able to function (e.g. internal module level monitors have failed). ...";
CM_ SG_ 2364681470 HVESP8Module9OperationalStatus "HVESP8 Module 9 Operational Status: Operational Status of Module 9 in this High Voltage Energy Storage Pack Instance.  Not Operational is used when the module is initializing or not able to function (e.g. internal module level monitors have failed). ...";
CM_ SG_ 2364681470 HVESP8Module10OperationalStatus "HVESP8 Module 10 Operational Status: Operational Status of Module 10 in this High Voltage Energy Storage Pack Instance.  Not Operational is used when the module is initializing or not able to function (e.g. internal module level monitors have failed)...";
CM_ SG_ 2364681470 HVESP8Module11OperationalStatus "HVESP8 Module 11 Operational Status: Operational Status of Module 11 in this High Voltage Energy Storage Pack Instance.  Not Operational is used when the module is initializing or not able to function (e.g. internal module level monitors have failed)...";
CM_ SG_ 2364681470 HVESP8Module12OperationalStatus "HVESP8 Module 12 Operational Status: Operational Status of Module 12 in this High Voltage Energy Storage Pack Instance.  Not Operational is used when the module is initializing or not able to function (e.g. internal module level monitors have failed)...";
CM_ SG_ 2364681470 HVESP8Module13OperationalStatus "HVESP8 Module 13 Operational Status: Operational Status of Module 13 in this High Voltage Energy Storage Pack Instance.  Not Operational is used when the module is initializing or not able to function (e.g. internal module level monitors have failed)...";
CM_ SG_ 2364681470 HVESP8Module14OperationalStatus "HVESP8 Module 14 Operational Status: Operational Status of Module 14 in this High Voltage Energy Storage Pack Instance.  Not Operational is used when the module is initializing or not able to function (e.g. internal module level monitors have failed)...";
CM_ SG_ 2364681470 HVESP8Module15OperationalStatus "HVESP8 Module 15 Operational Status: Operational Status of Module 15 in this High Voltage Energy Storage Pack Instance.  Not Operational is used when the module is initializing or not able to function (e.g. internal module level monitors have failed)...";
CM_ SG_ 2364681470 HVESP8Module16OperationalStatus "HVESP8 Module 16 Operational Status: Operational Status of Module 16 in this High Voltage Energy Storage Pack Instance.  Not Operational is used when the module is initializing or not able to function (e.g. internal module level monitors have failed)...";
CM_ SG_ 2364681470 HVESP8Module17OperationalStatus "HVESP8 Module 17 Operational Status: Operational Status of Module 17 in this High Voltage Energy Storage Pack Instance.  Not Operational is used when the module is initializing or not able to function (e.g. internal module level monitors have failed)...";
CM_ SG_ 2364681470 HVESP8Module18OperationalStatus "HVESP8 Module 18 Operational Status: Operational Status of Module 18 in this High Voltage Energy Storage Pack Instance.  Not Operational is used when the module is initializing or not able to function (e.g. internal module level monitors have failed)...";
CM_ SG_ 2364681470 HVESP8Module19OperationalStatus "HVESP8 Module 19 Operational Status: Operational Status of Module 19 in this High Voltage Energy Storage Pack Instance.  Not Operational is used when the module is initializing or not able to function (e.g. internal module level monitors have failed)...";
CM_ SG_ 2364681470 HVESP8Module20OperationalStatus "HVESP8 Module 20 Operational Status: Operational Status of Module 20 in this High Voltage Energy Storage Pack Instance.  Not Operational is used when the module is initializing or not able to function (e.g. internal module level monitors have failed)...";
CM_ SG_ 2364681470 HVESP8Module21OperationalStatus "HVESP8 Module 21 Operational Status: Operational Status of Module 21 in this High Voltage Energy Storage Pack Instance.  Not Operational is used when the module is initializing or not able to function (e.g. internal module level monitors have failed)...";
CM_ SG_ 2364681470 HVESP8Module22OperationalStatus "HVESP8 Module 22 Operational Status: Operational Status of Module 22 in this High Voltage Energy Storage Pack Instance.  Not Operational is used when the module is initializing or not able to function (e.g. internal module level monitors have failed)...";
CM_ SG_ 2364681470 HVESP8Module23OperationalStatus "HVESP8 Module 23 Operational Status: Operational Status of Module 23 in this High Voltage Energy Storage Pack Instance.  Not Operational is used when the module is initializing or not able to function (e.g. internal module level monitors have failed)...";
CM_ SG_ 2364681470 HVESP8Module24OperationalStatus "HVESP8 Module 24 Operational Status: Operational Status of Module 24 in this High Voltage Energy Storage Pack Instance.  Not Operational is used when the module is initializing or not able to function (e.g. internal module level monitors have failed)...";
CM_ SG_ 2364681470 HVESP8Module25OperationalStatus "HVESP8 Module 25 Operational Status: Operational Status of Module 25 in this High Voltage Energy Storage Pack Instance.  Not Operational is used when the module is initializing or not able to function (e.g. internal module level monitors have failed)...";
CM_ SG_ 2364681470 HVESP8Module26OperationalStatus "HVESP8 Module 26 Operational Status: Operational Status of Module 26 in this High Voltage Energy Storage Pack Instance.  Not Operational is used when the module is initializing or not able to function (e.g. internal module level monitors have failed)...";
CM_ SG_ 2364681470 HVESP8Module27OperationalStatus "HVESP8 Module 27 Operational Status: Operational Status of Module 27 in this High Voltage Energy Storage Pack Instance.  Not Operational is used when the module is initializing or not able to function (e.g. internal module level monitors have failed)...";
CM_ SG_ 2364681470 HVESP8Module28OperationalStatus "HVESP8 Module 28 Operational Status: Operational Status of Module 28 in this High Voltage Energy Storage Pack Instance.  Not Operational is used when the module is initializing or not able to function (e.g. internal module level monitors have failed)...";
CM_ SG_ 2364681470 HVESP8Module29OperationalStatus "HVESP8 Module 29 Operational Status: Operational Status of Module 29 in this High Voltage Energy Storage Pack Instance.  Not Operational is used when the module is initializing or not able to function (e.g. internal module level monitors have failed)...";
CM_ SG_ 2364681470 HVESP8Module30OperationalStatus "HVESP8 Module 30 Operational Status: Operational Status of Module 30 in this High Voltage Energy Storage Pack Instance.  Not Operational is used when the module is initializing or not able to function (e.g. internal module level monitors have failed)...";
CM_ SG_ 2364681470 HVESP8Module31OperationalStatus "HVESP8 Module 31 Operational Status: Operational Status of Module 31 in this High Voltage Energy Storage Pack Instance.  Not Operational is used when the module is initializing or not able to function (e.g. internal module level monitors have failed)...";
CM_ SG_ 2364681470 HVESP8Module32OperationalStatus "HVESP8 Module 32 Operational Status: Operational Status of Module 32 in this High Voltage Energy Storage Pack Instance.  Not Operational is used when the module is initializing or not able to function (e.g. internal module level monitors have failed)...";
CM_ BO_ 2364681726 "High Voltage Energy Storage Pack 8 Thermal Management System Status 1";
CM_ SG_ 2364681726 HVESP8ThrmlMngmntSstmSLIInptPwr "HVESP8 Thermal Management System SLI Input Power: This is the low-voltage power consumed by this HVES Thermal Management System (TMS).This parameter is for one of multiple packs in an HVESS.  If there is only one pack in the system, the HVESS paramet...";
CM_ SG_ 2364681726 HVESP8TMtSstHVtIptPw "HVESP8 Thermal Management System High-Voltage Input Power: This is the high-voltage power consumed by this HVES Thermal Management System (TMS).This parameter is for one of multiple packs in an HVESS.  If there is only one pack in the system, the HVE...";
CM_ SG_ 2364681726 HVESP8ThrmlMngmntSstmCmprssrSpd "HVESP8 Thermal Management System Compressor Speed: When this High Voltage Energy Storage Pack Thermal Management System is equipped with an active cooling system (e.g. air conditioner), this is the Compressor Speed.This parameter is for one of multip...";
CM_ SG_ 2364681726 HVESP8ThrmlMngmntSstmRltvHmdt "HVESP8 Thermal Management System Relative Humidty: When this High Voltage Energy Storage Pack Thermal Management System is equipped with a relative humidity sensor, this is the  measured Relative Humidity.This parameter is for one of multiple packs i...";
CM_ SG_ 2364681726 HVESP8ThrmlMngmntSstmHtrStts "HVESP8 Thermal Management System Heater Status: The state of this High Voltage Energy Storage Pack heaterThis parameter is for one of multiple packs in an HVESS.  If there is only one pack in the system, the HVESS parameters should be used. If there ...";
CM_ SG_ 2364681726 HVESP8ThrmlMngmntSstmHVILStts "HVESP8 Thermal Management System HVIL Status: In multiple HVES configurations, this is the status of the High Voltage Interlock Loop from the viewpoint of this Thermal Management System.00b = HVIL Closed01b = HVIL Open10b = Error11b = Not AvailableTh...";
CM_ SG_ 2364681726 HVESP8ThrmlMngmntSstmMd "HVESP8 Thermal Management System Mode: Indicates the operating mode of the Thermal Management System.  The heat transfer medium may be (e.g. liquid or air).  The cooling system may be fans, liquid coolant, or a combination of mediums.  The system may...";
CM_ SG_ 2364681726 HVESP8ThrmlMngmntSstmClntLvl "HVESP8 Thermal Management System Coolant Level: Indicates the coolant level in this HVES Thermal Management System (TMS).This parameter is for one of multiple packs in an HVESS.  If there is only one pack in the system, the HVESS parameters should be...";
CM_ BO_ 2364681982 "High Voltage Energy Storage Pack 8 Data 8";
CM_ SG_ 2364681982 HVESP8HghstCllVltgMdlNmr "HVESP8 Highest Cell Voltage Module Number: Identifies the location of the module containing SPN 14208 (HVESP8 Highest Cell Voltage).This parameter is for one of multiple packs in an HVESS. If there is only one pack in the system, the HVESS parameters...";
CM_ SG_ 2364681982 HVESP8HghstCllVltgCllNmr "HVESP8 Highest Cell Voltage Cell Number: Identifies the location of SPN 14208 (HVESP8 Highest Cell Voltage) within SPN 14288 (HVESP8 Highest Cell Voltage Module Number).This parameter is for one of multiple packs in an HVESS. If there is only one pac...";
CM_ SG_ 2364681982 HVESP8LwstCllVltgMdlNmr "HVESP8 Lowest Cell Voltage Module Number: Identifies the location of the module containing SPN 14209 (HVESP8 Lowest Cell Voltage).This parameter is for one of multiple packs in an HVESS. If there is only one pack in the system, the HVESS parameters s...";
CM_ SG_ 2364681982 HVESP8LwstCllVltgCllNmr "HVESP8 Lowest Cell Voltage Cell Number: Identifies the location of SPN 14209 (HVESP8 Lowest Cell Voltage) within SPN 14290 (HVESP8 Lowest Cell Voltage Module Number).This parameter is for one of multiple packs in an HVESS. If there is only one pack i...";
CM_ SG_ 2364681982 HVESP8AverageCellVoltage "HVESP8 Average Cell Voltage: The average cell voltage in this High Voltage Energy Storage Pack instance.This parameter is for one of multiple packs in an HVESS.  If there is only one pack in the system, the HVESS parameters should be used. If there a...";
CM_ BO_ 2364682238 "High Voltage Energy Storage Pack 8 Data 9";
CM_ SG_ 2364682238 HVESP8HghstCllTmprtrMdlNmr "HVESP8 Highest Cell Temperature Module Number: Identifies the location of the module containing SPN 14211 (HVESP8 Highest Cell Temperature).This parameter is for one of multiple packs in an HVESS. If there is only one pack in the system, the HVESS pa...";
CM_ SG_ 2364682238 HVESP8HghstCllTmprtrCllNmr "HVESP8 Highest Cell Temperature Cell Number: Identifies the location of SPN 14211 (HVESP8 Highest Cell Temperature) within SPN 14293 (HVESP8 Highest Cell Temperature Module Number).This parameter is for one of multiple packs in an HVESS. If there is ...";
CM_ SG_ 2364682238 HVESP8LwstCllTmprtrMdlNmr "HVESP8 Lowest Cell Temperature Module Number: Identifies the location of the module containing SPN 14212 (HVESP8 Lowest Cell Temperature).This parameter is for one of multiple packs in an HVESS. If there is only one pack in the system, the HVESS para...";
CM_ SG_ 2364682238 HVESP8LwstCllTmprtrCllNmr "HVESP8 Lowest Cell Temperature Cell Number: Identifies the location of SPN 14212 (HVESP8 Lowest Cell Temperature) within SPN 14295 (HVESP8 Lowest Cell Temperature Module Number).This parameter is for one of multiple packs in an HVESS. If there is onl...";
CM_ BO_ 2364682494 "High Voltage Energy Storage Pack 8 Data 10";
CM_ SG_ 2364682494 HVESP8HghstCllSttfChrgMdlNmr "HVESP8 Highest Cell State of Charge Module Number: Identifies the location of the module containing SPN 14221 (HVESP8 Highest Cell State of Charge).This parameter is for one of multiple packs in an HVESS. If there is only one pack in the system, the ...";
CM_ SG_ 2364682494 HVESP8HghstCllSttfChrgCllNmr "HVESP8 Highest Cell State of Charge Cell Number: Identifies the location of SPN 14221 (HVESP8 Highest Cell State of Charge) within SPN 14297 (HVESP8 Highest Cell State of Charge Module Number).This parameter is for one of multiple packs in an HVESS. ...";
CM_ SG_ 2364682494 HVESP8LwstCllSttfChrgMdlNmr "HVESP8 Lowest Cell State of Charge Module Number: Identifies the location of the module containing SPN 14220 (HVESP8 Lowest Cell State of Charge).This parameter is for one of multiple packs in an HVESS. If there is only one pack in the system, the HV...";
CM_ SG_ 2364682494 HVESP8LwstCllSttfChrgCllNmr "HVESP8 Lowest Cell State of Charge Cell Number: Identifies the location of SPN 14220 (HVESP8 Lowest Cell State of Charge) within SPN 14299 (HVESP8 Lowest Cell State of Charge Module Number).This parameter is for one of multiple packs in an HVESS. If ...";
CM_ SG_ 2364682494 HVESP8HghVltgBsAtvIsltnTstRslts "HVESP8 High-Voltage Bus Active Isolation Test Results: The isolation resistance expressed in Ohms per Volt that resulted from the High-Voltage Bus Active Isolation Test.See SPN 14233 (HVESP8 High-Voltage Bus Active Isolation Test Status) for test sta...";
CM_ SG_ 2364682494 HVESP8HVtBsPssvIstTstRsts "HVESP8 High-Voltage Bus Passive Isolation Test Results: The isolation resistance expressed in Ohms per Volt that resulted from the High-Voltage Bus Passive Isolation Test.See SPN 14234 (HVESP8 High-Voltage Bus Passive Isolation Test Status) for test ...";
CM_ BO_ 2364682750 "High Voltage Energy Storage Pack 8 Data 11";
CM_ SG_ 2364682750 HVESP8BsVltgNgtvtChsssGrndVltg "HVESP8 Bus Voltage Negative to Chassis Ground Voltage: Voltage difference between the most negative terminal of the HVES battery and chassis measured on the hybrid system bus side (not the battery side) of any HVES contained output contactor.  This v...";
CM_ SG_ 2364682750 HVESP8VltgLvlNgtvtChsssGrndVltg "HVESP8 Voltage Level Negative to Chassis Ground Voltage: Voltage difference between the most negative terminal of the HVES battery and chassis measured at the battery side of any HVES contained output contactor.  This voltage may be used for system l...";
CM_ SG_ 2364682750 HVESP8ActualChargeRate "HVESP8 Actual Charge Rate: This signal represents the actual present charge rate of this High Voltage Energy Storage Pack instance.This parameter is for one of multiple packs in an HVESS. If there is only one pack in the system, the HVESS parameters ...";
BA_DEF_ SG_  "SPN" INT 0 524287;
BA_DEF_ BO_  "VFrameFormat" ENUM  "StandardCAN","ExtendedCAN","reserved","J1939PG";
BA_DEF_DEF_  "SPN" 0;
BA_DEF_DEF_  "VFrameFormat" "J1939PG";
BA_ "SPN" SG_ 2633719294 VFSSMdl3Dttr1DttrTp 10893;
BA_ "SPN" SG_ 2633719294 VFSSMdl3Dttr1DttrDtSLOT 10894;
BA_ "SPN" SG_ 2633719294 VFSSMdl3Dttr2DttrTp 10896;
BA_ "SPN" SG_ 2633719294 VFSSMdl3Dttr2DttrDtSLOT 10897;
BA_ "SPN" SG_ 2633719294 VFSSMdl3Dttr3DttrTp 10899;
BA_ "SPN" SG_ 2633719294 VFSSMdl3Dttr3DttrDtSLOT 10900;
BA_ "SPN" SG_ 2633719294 VFSSMdl3Dttr4DttrTp 10902;
BA_ "SPN" SG_ 2633719294 VFSSMdl3Dttr4DttrDtSLOT 10903;
BA_ "SPN" SG_ 2633719294 VFSSMdl3Dttr5DttrTp 10905;
BA_ "SPN" SG_ 2633719294 VFSSMdl3Dttr5DttrDtSLOT 10906;
BA_ "SPN" SG_ 2633719294 VFSSMdl3Dttr6DttrTp 10908;
BA_ "SPN" SG_ 2633719294 VFSSMdl3Dttr6DttrDtSLOT 10909;
BA_ "SPN" SG_ 2633719294 VFSSMdl3Dttr7DttrTp 10911;
BA_ "SPN" SG_ 2633719294 VFSSMdl3Dttr7DttrDtSLOT 10912;
BA_ "SPN" SG_ 2633719294 VFSSMdl3Dttr8DttrTp 10914;
BA_ "SPN" SG_ 2633719294 VFSSMdl3Dttr8DttrDtSLOT 10915;
BA_ "SPN" SG_ 2633719550 VFSSMdl4Dttr1DttrTp 10917;
BA_ "SPN" SG_ 2633719550 VFSSMdl4Dttr1DttrDtSLOT 10918;
BA_ "SPN" SG_ 2633719550 VFSSMdl4Dttr2DttrTp 10920;
BA_ "SPN" SG_ 2633719550 VFSSMdl4Dttr2DttrDtSLOT 10921;
BA_ "SPN" SG_ 2633719550 VFSSMdl4Dttr3DttrTp 10923;
BA_ "SPN" SG_ 2633719550 VFSSMdl4Dttr3DttrDtSLOT 10924;
BA_ "SPN" SG_ 2633719550 VFSSMdl4Dttr4DttrTp 10926;
BA_ "SPN" SG_ 2633719550 VFSSMdl4Dttr4DttrDtSLOT 10927;
BA_ "SPN" SG_ 2633719550 VFSSMdl4Dttr5DttrTp 10929;
BA_ "SPN" SG_ 2633719550 VFSSMdl4Dttr5DttrDtSLOT 10930;
BA_ "SPN" SG_ 2633719550 VFSSMdl4Dttr6DttrTp 10932;
BA_ "SPN" SG_ 2633719550 VFSSMdl4Dttr6DttrDtSLOT 10933;
BA_ "SPN" SG_ 2633719550 VFSSMdl4Dttr7DttrTp 10935;
BA_ "SPN" SG_ 2633719550 VFSSMdl4Dttr7DttrDtSLOT 10936;
BA_ "SPN" SG_ 2633719550 VFSSMdl4Dttr8DttrTp 10938;
BA_ "SPN" SG_ 2633719550 VFSSMdl4Dttr8DttrDtSLOT 10939;
BA_ "SPN" SG_ 2633719806 VFSSModule1HeatZone1Data 10941;
BA_ "SPN" SG_ 2633719806 VFSSModule1HeatZone2Data 10942;
BA_ "SPN" SG_ 2633719806 VFSSModule1ReleaseZone1Data 10943;
BA_ "SPN" SG_ 2633719806 VFSSModule1ReleaseZone2Data 10944;
BA_ "SPN" SG_ 2633719806 VFSSModule1PressureSwitch1Data 10945;
BA_ "SPN" SG_ 2633719806 VFSSModule1PressureSwitch2Data 10946;
BA_ "SPN" SG_ 2633719806 VFSSModule1PrimaryPowerVoltage 10947;
BA_ "SPN" SG_ 2633719806 VFSSMdl1SndrPwrVltg 10948;
BA_ "SPN" SG_ 2633720062 VFSSModule2HeatZone1Data 10949;
BA_ "SPN" SG_ 2633720062 VFSSModule2HeatZone2Data 10950;
BA_ "SPN" SG_ 2633720062 VFSSModule2ReleaseZone1Data 10951;
BA_ "SPN" SG_ 2633720062 VFSSModule2ReleaseZone2Data 10952;
BA_ "SPN" SG_ 2633720062 VFSSModule2PressureSwitch1Data 10953;
BA_ "SPN" SG_ 2633720062 VFSSModule2PressureSwitch2Data 10954;
BA_ "SPN" SG_ 2633720062 VFSSModule2PrimaryPowerVoltage 10955;
BA_ "SPN" SG_ 2633720062 VFSSMdl2SndrPwrVltg 10956;
BA_ "SPN" SG_ 2633720318 VFSSModule3HeatZone1Data 10957;
BA_ "SPN" SG_ 2633720318 VFSSModule3HeatZone2Data 10958;
BA_ "SPN" SG_ 2633720318 VFSSModule3ReleaseZone1Data 10959;
BA_ "SPN" SG_ 2633720318 VFSSModule3ReleaseZone2Data 10960;
BA_ "SPN" SG_ 2633720318 VFSSModule3PressureSwitch1Data 10961;
BA_ "SPN" SG_ 2633720318 VFSSModule3PressureSwitch2Data 10962;
BA_ "SPN" SG_ 2633720318 VFSSModule3PrimaryPowerVoltage 10963;
BA_ "SPN" SG_ 2633720318 VFSSMdl3SndrPwrVltg 10964;
BA_ "SPN" SG_ 2633720574 VFSSModule4HeatZone1Data 10965;
BA_ "SPN" SG_ 2633720574 VFSSModule4HeatZone2Data 10966;
BA_ "SPN" SG_ 2633720574 VFSSModule4ReleaseZone1Data 10967;
BA_ "SPN" SG_ 2633720574 VFSSModule4ReleaseZone2Data 10968;
BA_ "SPN" SG_ 2633720574 VFSSModule4PressureSwitch1Data 10969;
BA_ "SPN" SG_ 2633720574 VFSSModule4PressureSwitch2Data 10970;
BA_ "SPN" SG_ 2633720574 VFSSModule4PrimaryPowerVoltage 10971;
BA_ "SPN" SG_ 2633720574 VFSSMdl4SndrPwrVltg 10972;
BA_ "SPN" SG_ 2633720830 VFSSModule1Name 10973;
BA_ "SPN" SG_ 2633720830 VFSSModule1DetectorZone1Name 10974;
BA_ "SPN" SG_ 2633720830 VFSSModule1DetectorZone2Name 10975;
BA_ "SPN" SG_ 2633720830 VFSSModule1DetectorZone3Name 10976;
BA_ "SPN" SG_ 2633720830 VFSSModule1DetectorZone4Name 10977;
BA_ "SPN" SG_ 2633720830 VFSSModule1DetectorZone5Name 10978;
BA_ "SPN" SG_ 2633720830 VFSSModule1DetectorZone6Name 10979;
BA_ "SPN" SG_ 2633720830 VFSSModule1DetectorZone7Name 10980;
BA_ "SPN" SG_ 2633720830 VFSSModule1DetectorZone8Name 10981;
BA_ "SPN" SG_ 2633720830 VFSSModule1HeatZone1Name 10982;
BA_ "SPN" SG_ 2633720830 VFSSModule1HeatZone2Name 10983;
BA_ "SPN" SG_ 2633720830 VFSSModule1ReleaseZone1Name 10984;
BA_ "SPN" SG_ 2633720830 VFSSModule1ReleaseZone2Name 10985;
BA_ "SPN" SG_ 2633721086 VFSSModule2Name 10986;
BA_ "SPN" SG_ 2633721086 VFSSModule2DetectorZone1Name 10987;
BA_ "SPN" SG_ 2633721086 VFSSModule2DetectorZone2Name 10988;
BA_ "SPN" SG_ 2633721086 VFSSModule2DetectorZone3Name 10989;
BA_ "SPN" SG_ 2633721086 VFSSModule2DetectorZone4Name 10990;
BA_ "SPN" SG_ 2633721086 VFSSModule2DetectorZone5Name 10991;
BA_ "SPN" SG_ 2633721086 VFSSModule2DetectorZone6Name 10992;
BA_ "SPN" SG_ 2633721086 VFSSModule2DetectorZone7Name 10993;
BA_ "SPN" SG_ 2633721086 VFSSModule2DetectorZone8Name 10994;
BA_ "SPN" SG_ 2633721086 VFSSModule2HeatZone1Name 10995;
BA_ "SPN" SG_ 2633721086 VFSSModule2HeatZone2Name 10996;
BA_ "SPN" SG_ 2633721086 VFSSModule2ReleaseZone1Name 10997;
BA_ "SPN" SG_ 2633721086 VFSSModule2ReleaseZone2Name 10998;
BA_ "SPN" SG_ 2633721342 VFSSModule3Name 10999;
BA_ "SPN" SG_ 2633721342 VFSSModule3DetectorZone1Name 11000;
BA_ "SPN" SG_ 2633721342 VFSSModule3DetectorZone2Name 11001;
BA_ "SPN" SG_ 2633721342 VFSSModule3DetectorZone3Name 11002;
BA_ "SPN" SG_ 2633721342 VFSSModule3DetectorZone4Name 11003;
BA_ "SPN" SG_ 2633721342 VFSSModule3DetectorZone5Name 11004;
BA_ "SPN" SG_ 2633721342 VFSSModule3DetectorZone6Name 11005;
BA_ "SPN" SG_ 2633721342 VFSSModule3DetectorZone7Name 11006;
BA_ "SPN" SG_ 2633721342 VFSSModule3DetectorZone8Name 11007;
BA_ "SPN" SG_ 2633721342 VFSSModule3HeatZone1Name 11008;
BA_ "SPN" SG_ 2633721342 VFSSModule3HeatZone2Name 11009;
BA_ "SPN" SG_ 2633721342 VFSSModule3ReleaseZone1Name 11010;
BA_ "SPN" SG_ 2633721342 VFSSModule3ReleaseZone2Name 11011;
BA_ "SPN" SG_ 2633721598 VFSSModule4Name 11012;
BA_ "SPN" SG_ 2633721598 VFSSModule4DetectorZone1Name 11013;
BA_ "SPN" SG_ 2633721598 VFSSModule4DetectorZone2Name 11014;
BA_ "SPN" SG_ 2633721598 VFSSModule4DetectorZone3Name 11015;
BA_ "SPN" SG_ 2633721598 VFSSModule4DetectorZone4Name 11016;
BA_ "SPN" SG_ 2633721598 VFSSModule4DetectorZone5Name 11017;
BA_ "SPN" SG_ 2633721598 VFSSModule4DetectorZone6Name 11018;
BA_ "SPN" SG_ 2633721598 VFSSModule4DetectorZone7Name 11019;
BA_ "SPN" SG_ 2633721598 VFSSModule4DetectorZone8Name 11020;
BA_ "SPN" SG_ 2633721598 VFSSModule4HeatZone1Name 11021;
BA_ "SPN" SG_ 2633721598 VFSSModule4HeatZone2Name 11022;
BA_ "SPN" SG_ 2633721598 VFSSModule4ReleaseZone1Name 11023;
BA_ "SPN" SG_ 2633721598 VFSSModule4ReleaseZone2Name 11024;
BA_ "SPN" SG_ 2566612990 MtGt2IvtPwLtddtUddRs 10817;
BA_ "SPN" SG_ 2566612990 MtGt2IvtPwLtddtDCSdCtMx 10818;
BA_ "SPN" SG_ 2566612990 MtGt2IvtPwLtddtDCSdCtM 10819;
BA_ "SPN" SG_ 2566612990 MtGt2IvtPwLtddtDCSdVtMx 10820;
BA_ "SPN" SG_ 2566612990 MtGt2IvtPwLtddtDCSdVtM 10821;
BA_ "SPN" SG_ 2566612990 MtGt2IvtPwLtddtMPwMx 10822;
BA_ "SPN" SG_ 2566612990 MtGt2IvtPwLtddtMPwM 10823;
BA_ "SPN" SG_ 2566612990 MtGt2IvtPwLtddtDCSdPwMx 10824;
BA_ "SPN" SG_ 2566612990 MtGt2IvtPwLtddtDCSdPwM 10825;
BA_ "SPN" SG_ 2566612990 MtrGnrtr2InvrtrPwrLmtddtTrqMxmm 10826;
BA_ "SPN" SG_ 2566612990 MtrGnrtr2InvrtrPwrLmtddtTrqMnmm 10827;
BA_ "SPN" SG_ 2566612990 MtrGnrtr2InvrtrPwrLmtddtSpdMxmm 10828;
BA_ "SPN" SG_ 2566612990 MtrGnrtr2InvrtrPwrLmtddtSpdMnmm 10829;
BA_ "SPN" SG_ 2566612990 MtGt2IvtPwLtddtIvtTpt 10830;
BA_ "SPN" SG_ 2566612990 MtGt2IvtPwLtddtMtTpt 10831;
BA_ "SPN" SG_ 2566612990 MtGt2IvtPwLtdDtFtCdt 13045;
BA_ "SPN" SG_ 2566612990 MtGt2IvtPwLtdDtAtvTqRtLt 13046;
BA_ "SPN" SG_ 2566612990 MtGt2IvtPwLtdDtAtvSpdRtLt 13047;
BA_ "SPN" SG_ 2566612990 MtGt2IvtTqLtdDtMCtsts 13048;
BA_ "SPN" SG_ 2566613246 MtrGnrtr2InvrtrIsltnIntgrtCRC 10810;
BA_ "SPN" SG_ 2566613246 MtrGnrtr2InvrtrIsltnIntgrtCntr 10811;
BA_ "SPN" SG_ 2566613246 MtGt2IvtDCSdNtvtCsssGdVt 10812;
BA_ "SPN" SG_ 2566613246 MtGt2IvtHVtBsAtvIstTstStts 10813;
BA_ "SPN" SG_ 2566613246 MtGt2IvtHVtBsPssvIstTstStts 10814;
BA_ "SPN" SG_ 2566613246 MtGt2IvtHVtBsAtvIstTstRsts 10815;
BA_ "SPN" SG_ 2566613246 MtGt2IvtHVtBsPssvIstTstRsts 10816;
BA_ "SPN" SG_ 2566613502 MtGt1IvtPwLtddtUddRs 10779;
BA_ "SPN" SG_ 2566613502 MtGt1IvtPwLtddtDCSdCtMx 10780;
BA_ "SPN" SG_ 2566613502 MtGt1IvtPwLtddtDCSdCtM 10781;
BA_ "SPN" SG_ 2566613502 MtGt1IvtPwLtddtDCSdVtMx 10782;
BA_ "SPN" SG_ 2566613502 MtGt1IvtPwLtddtDCSdVtM 10783;
BA_ "SPN" SG_ 2566613502 MtGt1IvtPwLtddtMPwMx 10784;
BA_ "SPN" SG_ 2566613502 MtGt1IvtPwLtddtMPwM 10785;
BA_ "SPN" SG_ 2566613502 MtGt1IvtPwLtddtDCSdPwMx 10786;
BA_ "SPN" SG_ 2566613502 MtGt1IvtPwLtddtDCSdPwM 10787;
BA_ "SPN" SG_ 2566613502 MtrGnrtr1InvrtrPwrLmtddtTrqMxmm 10788;
BA_ "SPN" SG_ 2566613502 MtrGnrtr1InvrtrPwrLmtddtTrqMnmm 10789;
BA_ "SPN" SG_ 2566613502 MtrGnrtr1InvrtrPwrLmtddtSpdMxmm 10790;
BA_ "SPN" SG_ 2566613502 MtrGnrtr1InvrtrPwrLmtddtSpdMnmm 10791;
BA_ "SPN" SG_ 2566613502 MtGt1IvtPwLtddtIvtTpt 10792;
BA_ "SPN" SG_ 2566613502 MtGt1IvtPwLtddtMtTpt 10793;
BA_ "SPN" SG_ 2566613502 MtGt1IvtPwLtdDtFtCdt 13041;
BA_ "SPN" SG_ 2566613502 MtGt1IvtPwLtdDtAtvTqRtLt 13042;
BA_ "SPN" SG_ 2566613502 MtGt1IvtPwLtdDtAtvSpdRtLt 13043;
BA_ "SPN" SG_ 2566613502 MtGt1IvtTqLtdDtMCtsts 13044;
BA_ "SPN" SG_ 2566613758 MtrGnrtr1InvrtrIsltnIntgrtCRC 10772;
BA_ "SPN" SG_ 2566613758 MtrGnrtr1InvrtrIsltnIntgrtCntr 10773;
BA_ "SPN" SG_ 2566613758 MtGt1IvtDCSdNtvtCsssGdVt 10774;
BA_ "SPN" SG_ 2566613758 MtGt1IvtHVtBsAtvIstTstStts 10775;
BA_ "SPN" SG_ 2566613758 MtGt1IvtHVtBsPssvIstTstStts 10776;
BA_ "SPN" SG_ 2566613758 MtGt1IvtHVtBsAtvIstTstRsts 10777;
BA_ "SPN" SG_ 2566613758 MtGt1IvtHVtBsPssvIstTstRsts 10778;
BA_ "SPN" SG_ 2566614014 HighVoltageDCBusAvailability 10298;
BA_ "SPN" SG_ 2352021246 HVESP7HghVltgBsCnntCmmnd 14037;
BA_ "SPN" SG_ 2352021246 HVESP7PowerDownCommand 14038;
BA_ "SPN" SG_ 2352021246 HVESP7HghVltgBsAtvIsltnTstCmmnd 14039;
BA_ "SPN" SG_ 2352021246 HVESP7HVtBsPssvIstTstCd 14040;
BA_ "SPN" SG_ 2352021246 HVESP7CellBalancingCommand 14041;
BA_ "SPN" SG_ 2352021246 HVESP7EnlIntrnlChrgrCmmnd 14042;
BA_ "SPN" SG_ 2352021246 HVESP7OperationConsent 14043;
BA_ "SPN" SG_ 2352021246 HVESP7HVtBsHSdRsstCtRqst 14044;
BA_ "SPN" SG_ 2352021246 HVESP7HVtBsLwSdRsstCtRqst 14045;
BA_ "SPN" SG_ 2352021246 HVESP7Control1Counter 14046;
BA_ "SPN" SG_ 2352021246 HVESP7Control1CRC 14047;
BA_ "SPN" SG_ 2352086782 HVESP8HghVltgBsCnntCmmnd 14180;
BA_ "SPN" SG_ 2352086782 HVESP8PowerDownCommand 14181;
BA_ "SPN" SG_ 2352086782 HVESP8HghVltgBsAtvIsltnTstCmmnd 14182;
BA_ "SPN" SG_ 2352086782 HVESP8HVtBsPssvIstTstCd 14183;
BA_ "SPN" SG_ 2352086782 HVESP8CellBalancingCommand 14184;
BA_ "SPN" SG_ 2352086782 HVESP8EnlIntrnlChrgrCmmnd 14185;
BA_ "SPN" SG_ 2352086782 HVESP8OperationConsent 14186;
BA_ "SPN" SG_ 2352086782 HVESP8HVtBsHSdRsstCtRqst 14187;
BA_ "SPN" SG_ 2352086782 HVESP8HVtBsLwSdRsstCtRqst 14188;
BA_ "SPN" SG_ 2352086782 HVESP8Control1Counter 14189;
BA_ "SPN" SG_ 2352086782 HVESP8Control1CRC 14190;
BA_ "SPN" SG_ 2352152318 HVESP9HghVltgBsCnntCmmnd 14323;
BA_ "SPN" SG_ 2352152318 HVESP9PowerDownCommand 14324;
BA_ "SPN" SG_ 2352152318 HVESP9HghVltgBsAtvIsltnTstCmmnd 14325;
BA_ "SPN" SG_ 2352152318 HVESP9HVtBsPssvIstTstCd 14326;
BA_ "SPN" SG_ 2352152318 HVESP9CellBalancingCommand 14327;
BA_ "SPN" SG_ 2352152318 HVESP9EnlIntrnlChrgrCmmnd 14328;
BA_ "SPN" SG_ 2352152318 HVESP9OperationConsent 14329;
BA_ "SPN" SG_ 2352152318 HVESP9HVtBsHSdRsstCtRqst 14330;
BA_ "SPN" SG_ 2352152318 HVESP9HVtBsLwSdRsstCtRqst 14331;
BA_ "SPN" SG_ 2352152318 HVESP9Control1Counter 14332;
BA_ "SPN" SG_ 2352152318 HVESP9Control1CRC 14333;
BA_ "SPN" SG_ 2352217854 HVESP10HghVltgBsCnntCmmnd 14466;
BA_ "SPN" SG_ 2352217854 HVESP10PowerDownCommand 14467;
BA_ "SPN" SG_ 2352217854 HVESP10HVtBsAtvIstTstCd 14468;
BA_ "SPN" SG_ 2352217854 HVESP10HVtBsPssvIstTstCd 14469;
BA_ "SPN" SG_ 2352217854 HVESP10CellBalancingCommand 14470;
BA_ "SPN" SG_ 2352217854 HVESP10EnlIntrnlChrgrCmmnd 14471;
BA_ "SPN" SG_ 2352217854 HVESP10OperationConsent 14472;
BA_ "SPN" SG_ 2352217854 HVESP10HVtBsHSdRsstCtRqst 14473;
BA_ "SPN" SG_ 2352217854 HVESP10HVtBsLwSdRsstCtRqst 14474;
BA_ "SPN" SG_ 2352217854 HVESP10Control1Counter 14475;
BA_ "SPN" SG_ 2352217854 HVESP10Control1CRC 14476;
BA_ "SPN" SG_ 2555379454 DataTransferManufacturerID 12993;
BA_ "SPN" SG_ 2555379454 TotalWeeklyMessageInstances 12997;
BA_ "SPN" SG_ 2555379454 LongestWeeklyMessageInstance 12998;
BA_ "SPN" SG_ 2555379454 TotalMonthlyMessageInstances 13000;
BA_ "SPN" SG_ 2555379454 LongestMonthlyMessageInstance 13001;
BA_ "SPN" SG_ 2555379454 TotalDailyMessageInstances 12994;
BA_ "SPN" SG_ 2555379454 LongestDailyMessageInstance 12995;
BA_ "SPN" SG_ 2555379454 TotalDailyMessageBytes 12996;
BA_ "SPN" SG_ 2555379454 TotalWeeklyMessageBytes 12999;
BA_ "SPN" SG_ 2555379454 TotalMonthlyMessageBytes 13002;
BA_ "SPN" SG_ 2555444990 MonthlyMessageInstance 12983;
BA_ "SPN" SG_ 2555444990 MnthlMssgInstnsRmnng 12984;
BA_ "SPN" SG_ 2555444990 MonthlyDataManufacturerID 12985;
BA_ "SPN" SG_ 2555510526 WeeklyMessageInstance 12978;
BA_ "SPN" SG_ 2555510526 WeeklyMessageInstancesRemaining 12979;
BA_ "SPN" SG_ 2555510526 WeeklyDataManufacturerID 12980;
BA_ "SPN" SG_ 2555576062 DailyMessageInstance 12973;
BA_ "SPN" SG_ 2555576062 DailyMessageInstancesRemaining 12974;
BA_ "SPN" SG_ 2555576062 DailyDataManufacturerID 12975;
BA_ "SPN" SG_ 2364675326 HVESP7DshrgPwrLmtDtSttfChrg 14048;
BA_ "SPN" SG_ 2364675326 HVESP7DshrgPwrLmtDtBttrTmprtr 14049;
BA_ "SPN" SG_ 2364675326 HVESP7DsPwLtDtBttDstCdt 14050;
BA_ "SPN" SG_ 2364675326 HVESP7DshrgPwrLmtDtBttrrCllVltg 14051;
BA_ "SPN" SG_ 2364675326 HVESP7DshrgPwrLmtDtBttrCrrnt 14052;
BA_ "SPN" SG_ 2364675326 HVESP7DshrgPwrLmtDtnUndfndCs 14053;
BA_ "SPN" SG_ 2364675326 HVESP7ChrgPwrLmtDtSttfChrg 14054;
BA_ "SPN" SG_ 2364675326 HVESP7ChrgPwrLmtDtBttrTmprtr 14055;
BA_ "SPN" SG_ 2364675326 HVESP7CPwLtDtBttDstCdt 14056;
BA_ "SPN" SG_ 2364675326 HVESP7ChrgPwrLmtDtBttrrCllVltg 14057;
BA_ "SPN" SG_ 2364675326 HVESP7ChrgPwrLmtDtBttrCrrnt 14058;
BA_ "SPN" SG_ 2364675326 HVESP7ChrgPwrLmtDtnUndfndCs 14059;
BA_ "SPN" SG_ 2364675582 HVESP7AvailableDischargePower 14060;
BA_ "SPN" SG_ 2364675582 HVESP7AvailableChargePower 14061;
BA_ "SPN" SG_ 2364675582 HVESP7VoltageLevel 14062;
BA_ "SPN" SG_ 2364675582 HVESP7Current 14063;
BA_ "SPN" SG_ 2364675838 HVESP7FastUpdateStateofCharge 14064;
BA_ "SPN" SG_ 2364675838 HVESP7HighestCellVoltage 14065;
BA_ "SPN" SG_ 2364675838 HVESP7LowestCellVoltage 14066;
BA_ "SPN" SG_ 2364675838 HVESP7CllVltgDffrntlStts 14067;
BA_ "SPN" SG_ 2364676094 HVESP7HighestCellTemperature 14068;
BA_ "SPN" SG_ 2364676094 HVESP7LowestCellTemperature 14069;
BA_ "SPN" SG_ 2364676094 HVESP7AverageCellTemperature 14070;
BA_ "SPN" SG_ 2364676094 HVESP7CllTmprtrDffrntlStts 14071;
BA_ "SPN" SG_ 2364676350 HVESP7DischargeCapacity 14072;
BA_ "SPN" SG_ 2364676350 HVESP7ChargeCapacity 14073;
BA_ "SPN" SG_ 2364676350 HVESP7CellBalancingCount 14074;
BA_ "SPN" SG_ 2364676606 HVESP7DischargeCurrentLimit 14075;
BA_ "SPN" SG_ 2364676606 HVESP7ChargeCurrentLimit 14076;
BA_ "SPN" SG_ 2364676606 HVESP7LowestCellStateofCharge 14077;
BA_ "SPN" SG_ 2364676606 HVESP7HighestCellStateofCharge 14078;
BA_ "SPN" SG_ 2364676862 HVESP7BusVoltage 14079;
BA_ "SPN" SG_ 2364676862 HVESP7IgnitionVoltage 14080;
BA_ "SPN" SG_ 2364676862 HVESP7IntakeCoolantTemperature 14081;
BA_ "SPN" SG_ 2364676862 HVESP7OutletCoolantTemperature 14082;
BA_ "SPN" SG_ 2364676862 HVESP7ElectronicsTemperature 14083;
BA_ "SPN" SG_ 2364676862 HVESP7Temperature 14084;
BA_ "SPN" SG_ 2364677118 HVESP7HghVltgBsPstvCnttrStt 14085;
BA_ "SPN" SG_ 2364677118 HVESP7HghVltgBsNgtvCnttrStt 14086;
BA_ "SPN" SG_ 2364677118 HVESP7HghVltgBsDsnntFrwrnng 14087;
BA_ "SPN" SG_ 2364677118 HVESP7HghVltgBsPrChrgRlStt 14088;
BA_ "SPN" SG_ 2364677118 HVESP7CntrfPkCnttrStt 14089;
BA_ "SPN" SG_ 2364677118 HVESP7HghVltgBsAtvIsltnTstStts 14090;
BA_ "SPN" SG_ 2364677118 HVESP7HghVltgBsPssvIsltnTstStts 14091;
BA_ "SPN" SG_ 2364677118 HVESP7HVILStatus 14092;
BA_ "SPN" SG_ 2364677118 HVESP7InertiaSwitchStatus 14093;
BA_ "SPN" SG_ 2364677118 HVESP7StateofChargeStatus 14094;
BA_ "SPN" SG_ 2364677118 HVESP7CellBalanceStatus 14095;
BA_ "SPN" SG_ 2364677118 HVESP7CellBalancingActive 14096;
BA_ "SPN" SG_ 2364677118 HVESP7InternalChargerStatus 14097;
BA_ "SPN" SG_ 2364677118 HVESP7HghVltgBsCnntnStts 14098;
BA_ "SPN" SG_ 2364677118 HVESP7OperationalStatus 14099;
BA_ "SPN" SG_ 2364677118 HVESP7Status1Counter 14100;
BA_ "SPN" SG_ 2364677118 HVESP7Status1CRC 14101;
BA_ "SPN" SG_ 2364677374 HVESP7DischargeEnergyCapacity 14102;
BA_ "SPN" SG_ 2364677374 HVESP7ChargeEnergyCapacity 14103;
BA_ "SPN" SG_ 2364677374 HVESP7MaximumChargeVoltageLimit 14104;
BA_ "SPN" SG_ 2364677630 HVESP7Module1OperationalStatus 14105;
BA_ "SPN" SG_ 2364677630 HVESP7Module2OperationalStatus 14106;
BA_ "SPN" SG_ 2364677630 HVESP7Module3OperationalStatus 14107;
BA_ "SPN" SG_ 2364677630 HVESP7Module4OperationalStatus 14108;
BA_ "SPN" SG_ 2364677630 HVESP7Module5OperationalStatus 14109;
BA_ "SPN" SG_ 2364677630 HVESP7Module6OperationalStatus 14110;
BA_ "SPN" SG_ 2364677630 HVESP7Module7OperationalStatus 14111;
BA_ "SPN" SG_ 2364677630 HVESP7Module8OperationalStatus 14112;
BA_ "SPN" SG_ 2364677630 HVESP7Module9OperationalStatus 14113;
BA_ "SPN" SG_ 2364677630 HVESP7Module10OperationalStatus 14114;
BA_ "SPN" SG_ 2364677630 HVESP7Module11OperationalStatus 14115;
BA_ "SPN" SG_ 2364677630 HVESP7Module12OperationalStatus 14116;
BA_ "SPN" SG_ 2364677630 HVESP7Module13OperationalStatus 14117;
BA_ "SPN" SG_ 2364677630 HVESP7Module14OperationalStatus 14118;
BA_ "SPN" SG_ 2364677630 HVESP7Module15OperationalStatus 14119;
BA_ "SPN" SG_ 2364677630 HVESP7Module16OperationalStatus 14120;
BA_ "SPN" SG_ 2364677630 HVESP7Module17OperationalStatus 14121;
BA_ "SPN" SG_ 2364677630 HVESP7Module18OperationalStatus 14122;
BA_ "SPN" SG_ 2364677630 HVESP7Module19OperationalStatus 14123;
BA_ "SPN" SG_ 2364677630 HVESP7Module20OperationalStatus 14124;
BA_ "SPN" SG_ 2364677630 HVESP7Module21OperationalStatus 14125;
BA_ "SPN" SG_ 2364677630 HVESP7Module22OperationalStatus 14126;
BA_ "SPN" SG_ 2364677630 HVESP7Module23OperationalStatus 14127;
BA_ "SPN" SG_ 2364677630 HVESP7Module24OperationalStatus 14128;
BA_ "SPN" SG_ 2364677630 HVESP7Module25OperationalStatus 14129;
BA_ "SPN" SG_ 2364677630 HVESP7Module26OperationalStatus 14130;
BA_ "SPN" SG_ 2364677630 HVESP7Module27OperationalStatus 14131;
BA_ "SPN" SG_ 2364677630 HVESP7Module28OperationalStatus 14132;
BA_ "SPN" SG_ 2364677630 HVESP7Module29OperationalStatus 14133;
BA_ "SPN" SG_ 2364677630 HVESP7Module30OperationalStatus 14134;
BA_ "SPN" SG_ 2364677630 HVESP7Module31OperationalStatus 14135;
BA_ "SPN" SG_ 2364677630 HVESP7Module32OperationalStatus 14136;
BA_ "SPN" SG_ 2364677886 HVESP7ThrmlMngmntSstmSLIInptPwr 14137;
BA_ "SPN" SG_ 2364677886 HVESP7TMtSstHVtIptPw 14138;
BA_ "SPN" SG_ 2364677886 HVESP7ThrmlMngmntSstmCmprssrSpd 14139;
BA_ "SPN" SG_ 2364677886 HVESP7ThrmlMngmntSstmRltvHmdt 14140;
BA_ "SPN" SG_ 2364677886 HVESP7ThrmlMngmntSstmHtrStts 14141;
BA_ "SPN" SG_ 2364677886 HVESP7ThrmlMngmntSstmHVILStts 14142;
BA_ "SPN" SG_ 2364677886 HVESP7ThrmlMngmntSstmMd 14143;
BA_ "SPN" SG_ 2364677886 HVESP7ThrmlMngmntSstmClntLvl 14144;
BA_ "SPN" SG_ 2364678142 HVESP7HghstCllVltgMdlNmr 14145;
BA_ "SPN" SG_ 2364678142 HVESP7HghstCllVltgCllNmr 14146;
BA_ "SPN" SG_ 2364678142 HVESP7LwstCllVltgMdlNmr 14147;
BA_ "SPN" SG_ 2364678142 HVESP7LwstCllVltgCllNmr 14148;
BA_ "SPN" SG_ 2364678142 HVESP7AverageCellVoltage 14149;
BA_ "SPN" SG_ 2364678398 HVESP7HghstCllTmprtrMdlNmr 14150;
BA_ "SPN" SG_ 2364678398 HVESP7HghstCllTmprtrCllNmr 14151;
BA_ "SPN" SG_ 2364678398 HVESP7LwstCllTmprtrMdlNmr 14152;
BA_ "SPN" SG_ 2364678398 HVESP7LwstCllTmprtrCllNmr 14153;
BA_ "SPN" SG_ 2364678654 HVESP7HghstCllSttfChrgMdlNmr 14154;
BA_ "SPN" SG_ 2364678654 HVESP7HghstCllSttfChrgCllNmr 14155;
BA_ "SPN" SG_ 2364678654 HVESP7LwstCllSttfChrgMdlNmr 14156;
BA_ "SPN" SG_ 2364678654 HVESP7LwstCllSttfChrgCllNmr 14157;
BA_ "SPN" SG_ 2364678654 HVESP7HghVltgBsAtvIsltnTstRslts 14158;
BA_ "SPN" SG_ 2364678654 HVESP7HVtBsPssvIstTstRsts 14159;
BA_ "SPN" SG_ 2364678910 HVESP7BsVltgNgtvtChsssGrndVltg 14160;
BA_ "SPN" SG_ 2364678910 HVESP7VltgLvlNgtvtChsssGrndVltg 14161;
BA_ "SPN" SG_ 2364678910 HVESP7ActualChargeRate 14162;
BA_ "SPN" SG_ 2364679166 HVESP8DshrgPwrLmtDtSttfChrg 14191;
BA_ "SPN" SG_ 2364679166 HVESP8DshrgPwrLmtDtBttrTmprtr 14192;
BA_ "SPN" SG_ 2364679166 HVESP8DsPwLtDtBttDstCdt 14193;
BA_ "SPN" SG_ 2364679166 HVESP8DshrgPwrLmtDtBttrrCllVltg 14194;
BA_ "SPN" SG_ 2364679166 HVESP8DshrgPwrLmtDtBttrCrrnt 14195;
BA_ "SPN" SG_ 2364679166 HVESP8DshrgPwrLmtDtnUndfndCs 14196;
BA_ "SPN" SG_ 2364679166 HVESP8ChrgPwrLmtDtSttfChrg 14197;
BA_ "SPN" SG_ 2364679166 HVESP8ChrgPwrLmtDtBttrTmprtr 14198;
BA_ "SPN" SG_ 2364679166 HVESP8CPwLtDtBttDstCdt 14199;
BA_ "SPN" SG_ 2364679166 HVESP8ChrgPwrLmtDtBttrrCllVltg 14200;
BA_ "SPN" SG_ 2364679166 HVESP8ChrgPwrLmtDtBttrCrrnt 14201;
BA_ "SPN" SG_ 2364679166 HVESP8ChrgPwrLmtDtnUndfndCs 14202;
BA_ "SPN" SG_ 2364679422 HVESP8AvailableDischargePower 14203;
BA_ "SPN" SG_ 2364679422 HVESP8AvailableChargePower 14204;
BA_ "SPN" SG_ 2364679422 HVESP8VoltageLevel 14205;
BA_ "SPN" SG_ 2364679422 HVESP8Current 14206;
BA_ "SPN" SG_ 2364679678 HVESP8FastUpdateStateofCharge 14207;
BA_ "SPN" SG_ 2364679678 HVESP8HighestCellVoltage 14208;
BA_ "SPN" SG_ 2364679678 HVESP8LowestCellVoltage 14209;
BA_ "SPN" SG_ 2364679678 HVESP8CllVltgDffrntlStts 14210;
BA_ "SPN" SG_ 2364679934 HVESP8HighestCellTemperature 14211;
BA_ "SPN" SG_ 2364679934 HVESP8LowestCellTemperature 14212;
BA_ "SPN" SG_ 2364679934 HVESP8AverageCellTemperature 14213;
BA_ "SPN" SG_ 2364679934 HVESP8CllTmprtrDffrntlStts 14214;
BA_ "SPN" SG_ 2364680190 HVESP8DischargeCapacity 14215;
BA_ "SPN" SG_ 2364680190 HVESP8ChargeCapacity 14216;
BA_ "SPN" SG_ 2364680190 HVESP8CellBalancingCount 14217;
BA_ "SPN" SG_ 2364680446 HVESP8DischargeCurrentLimit 14218;
BA_ "SPN" SG_ 2364680446 HVESP8ChargeCurrentLimit 14219;
BA_ "SPN" SG_ 2364680446 HVESP8LowestCellStateofCharge 14220;
BA_ "SPN" SG_ 2364680446 HVESP8HighestCellStateofCharge 14221;
BA_ "SPN" SG_ 2364680702 HVESP8BusVoltage 14222;
BA_ "SPN" SG_ 2364680702 HVESP8IgnitionVoltage 14223;
BA_ "SPN" SG_ 2364680702 HVESP8IntakeCoolantTemperature 14224;
BA_ "SPN" SG_ 2364680702 HVESP8OutletCoolantTemperature 14225;
BA_ "SPN" SG_ 2364680702 HVESP8ElectronicsTemperature 14226;
BA_ "SPN" SG_ 2364680702 HVESP8Temperature 14227;
BA_ "SPN" SG_ 2364680958 HVESP8HghVltgBsPstvCnttrStt 14228;
BA_ "SPN" SG_ 2364680958 HVESP8HghVltgBsNgtvCnttrStt 14229;
BA_ "SPN" SG_ 2364680958 HVESP8HghVltgBsDsnntFrwrnng 14230;
BA_ "SPN" SG_ 2364680958 HVESP8HghVltgBsPrChrgRlStt 14231;
BA_ "SPN" SG_ 2364680958 HVESP8CntrfPkCnttrStt 14232;
BA_ "SPN" SG_ 2364680958 HVESP8HghVltgBsAtvIsltnTstStts 14233;
BA_ "SPN" SG_ 2364680958 HVESP8HghVltgBsPssvIsltnTstStts 14234;
BA_ "SPN" SG_ 2364680958 HVESP8HVILStatus 14235;
BA_ "SPN" SG_ 2364680958 HVESP8InertiaSwitchStatus 14236;
BA_ "SPN" SG_ 2364680958 HVESP8StateofChargeStatus 14237;
BA_ "SPN" SG_ 2364680958 HVESP8CellBalanceStatus 14238;
BA_ "SPN" SG_ 2364680958 HVESP8CellBalancingActive 14239;
BA_ "SPN" SG_ 2364680958 HVESP8InternalChargerStatus 14240;
BA_ "SPN" SG_ 2364680958 HVESP8HghVltgBsCnntnStts 14241;
BA_ "SPN" SG_ 2364680958 HVESP8OperationalStatus 14242;
BA_ "SPN" SG_ 2364680958 HVESP8Status1Counter 14243;
BA_ "SPN" SG_ 2364680958 HVESP8Status1CRC 14244;
BA_ "SPN" SG_ 2364681214 HVESP8DischargeEnergyCapacity 14245;
BA_ "SPN" SG_ 2364681214 HVESP8ChargeEnergyCapacity 14246;
BA_ "SPN" SG_ 2364681214 HVESP8MaximumChargeVoltageLimit 14247;
BA_ "SPN" SG_ 2364681470 HVESP8Module1OperationalStatus 14248;
BA_ "SPN" SG_ 2364681470 HVESP8Module2OperationalStatus 14249;
BA_ "SPN" SG_ 2364681470 HVESP8Module3OperationalStatus 14250;
BA_ "SPN" SG_ 2364681470 HVESP8Module4OperationalStatus 14251;
BA_ "SPN" SG_ 2364681470 HVESP8Module5OperationalStatus 14252;
BA_ "SPN" SG_ 2364681470 HVESP8Module6OperationalStatus 14253;
BA_ "SPN" SG_ 2364681470 HVESP8Module7OperationalStatus 14254;
BA_ "SPN" SG_ 2364681470 HVESP8Module8OperationalStatus 14255;
BA_ "SPN" SG_ 2364681470 HVESP8Module9OperationalStatus 14256;
BA_ "SPN" SG_ 2364681470 HVESP8Module10OperationalStatus 14257;
BA_ "SPN" SG_ 2364681470 HVESP8Module11OperationalStatus 14258;
BA_ "SPN" SG_ 2364681470 HVESP8Module12OperationalStatus 14259;
BA_ "SPN" SG_ 2364681470 HVESP8Module13OperationalStatus 14260;
BA_ "SPN" SG_ 2364681470 HVESP8Module14OperationalStatus 14261;
BA_ "SPN" SG_ 2364681470 HVESP8Module15OperationalStatus 14262;
BA_ "SPN" SG_ 2364681470 HVESP8Module16OperationalStatus 14263;
BA_ "SPN" SG_ 2364681470 HVESP8Module17OperationalStatus 14264;
BA_ "SPN" SG_ 2364681470 HVESP8Module18OperationalStatus 14265;
BA_ "SPN" SG_ 2364681470 HVESP8Module19OperationalStatus 14266;
BA_ "SPN" SG_ 2364681470 HVESP8Module20OperationalStatus 14267;
BA_ "SPN" SG_ 2364681470 HVESP8Module21OperationalStatus 14268;
BA_ "SPN" SG_ 2364681470 HVESP8Module22OperationalStatus 14269;
BA_ "SPN" SG_ 2364681470 HVESP8Module23OperationalStatus 14270;
BA_ "SPN" SG_ 2364681470 HVESP8Module24OperationalStatus 14271;
BA_ "SPN" SG_ 2364681470 HVESP8Module25OperationalStatus 14272;
BA_ "SPN" SG_ 2364681470 HVESP8Module26OperationalStatus 14273;
BA_ "SPN" SG_ 2364681470 HVESP8Module27OperationalStatus 14274;
BA_ "SPN" SG_ 2364681470 HVESP8Module28OperationalStatus 14275;
BA_ "SPN" SG_ 2364681470 HVESP8Module29OperationalStatus 14276;
BA_ "SPN" SG_ 2364681470 HVESP8Module30OperationalStatus 14277;
BA_ "SPN" SG_ 2364681470 HVESP8Module31OperationalStatus 14278;
BA_ "SPN" SG_ 2364681470 HVESP8Module32OperationalStatus 14279;
BA_ "SPN" SG_ 2364681726 HVESP8ThrmlMngmntSstmSLIInptPwr 14280;
BA_ "SPN" SG_ 2364681726 HVESP8TMtSstHVtIptPw 14281;
BA_ "SPN" SG_ 2364681726 HVESP8ThrmlMngmntSstmCmprssrSpd 14282;
BA_ "SPN" SG_ 2364681726 HVESP8ThrmlMngmntSstmRltvHmdt 14283;
BA_ "SPN" SG_ 2364681726 HVESP8ThrmlMngmntSstmHtrStts 14284;
BA_ "SPN" SG_ 2364681726 HVESP8ThrmlMngmntSstmHVILStts 14285;
BA_ "SPN" SG_ 2364681726 HVESP8ThrmlMngmntSstmMd 14286;
BA_ "SPN" SG_ 2364681726 HVESP8ThrmlMngmntSstmClntLvl 14287;
BA_ "SPN" SG_ 2364681982 HVESP8HghstCllVltgMdlNmr 14288;
BA_ "SPN" SG_ 2364681982 HVESP8HghstCllVltgCllNmr 14289;
BA_ "SPN" SG_ 2364681982 HVESP8LwstCllVltgMdlNmr 14290;
BA_ "SPN" SG_ 2364681982 HVESP8LwstCllVltgCllNmr 14291;
BA_ "SPN" SG_ 2364681982 HVESP8AverageCellVoltage 14292;
BA_ "SPN" SG_ 2364682238 HVESP8HghstCllTmprtrMdlNmr 14293;
BA_ "SPN" SG_ 2364682238 HVESP8HghstCllTmprtrCllNmr 14294;
BA_ "SPN" SG_ 2364682238 HVESP8LwstCllTmprtrMdlNmr 14295;
BA_ "SPN" SG_ 2364682238 HVESP8LwstCllTmprtrCllNmr 14296;
BA_ "SPN" SG_ 2364682494 HVESP8HghstCllSttfChrgMdlNmr 14297;
BA_ "SPN" SG_ 2364682494 HVESP8HghstCllSttfChrgCllNmr 14298;
BA_ "SPN" SG_ 2364682494 HVESP8LwstCllSttfChrgMdlNmr 14299;
BA_ "SPN" SG_ 2364682494 HVESP8LwstCllSttfChrgCllNmr 14300;
BA_ "SPN" SG_ 2364682494 HVESP8HghVltgBsAtvIsltnTstRslts 14301;
BA_ "SPN" SG_ 2364682494 HVESP8HVtBsPssvIstTstRsts 14302;
BA_ "SPN" SG_ 2364682750 HVESP8BsVltgNgtvtChsssGrndVltg 14303;
BA_ "SPN" SG_ 2364682750 HVESP8VltgLvlNgtvtChsssGrndVltg 14304;
BA_ "SPN" SG_ 2364682750 HVESP8ActualChargeRate 14305;
